VERSION ""

NS_ :

BS_:

BU_: WPC2 PSB SHVU_RR FCS vHS_B2 EMCU SLB GW_APSU GW_DLBCU RCM ARS CGW_CCU vDummy_HS_B GW_RLPSU ATS RLHV SGU PFSU GW_RRPSU ALBCU DSAU SWRC SHVU_FR RCS GW_DPSU BLTN_CAM SCM OHCL RWPC RRHV WPC HOD ASAU

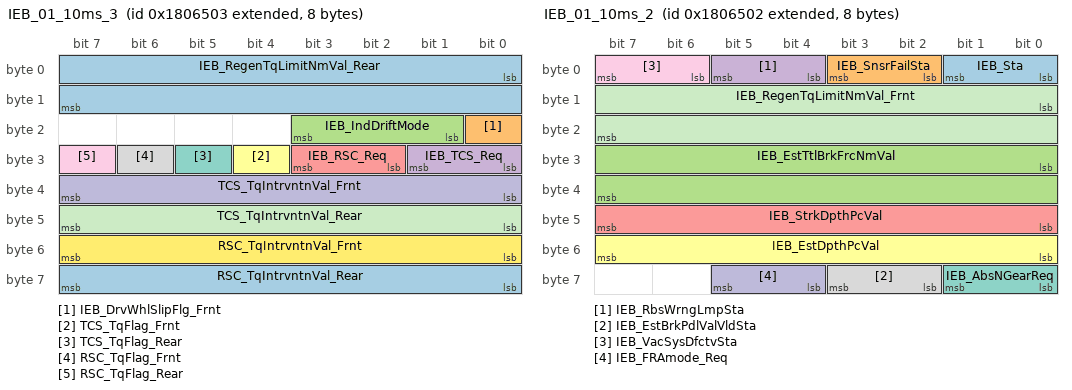
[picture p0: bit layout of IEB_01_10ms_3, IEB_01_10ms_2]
BO_ 2172675331 IEB_01_10ms_3: 8 CGW_CCU
 SG_ IEB_RegenTqLimitNmVal_Rear : 0|16@1+ (1,0) [0|0] "Nm" Vector__XXX
 SG_ IEB_DrvWhlSlipFlg_Frnt : 16|1@1+ (1,0) [0|0] "" Vector__XXX
 SG_ IEB_IndDriftMode : 17|3@1+ (1,0) [0|0] "" Vector__XXX
 SG_ IEB_TCS_Req : 24|2@1+ (1,0) [0|0] "" Vector__XXX
 SG_ IEB_RSC_Req : 26|2@1+ (1,0) [0|0] "" Vector__XXX
 SG_ TCS_TqFlag_Frnt : 28|1@1+ (1,0) [0|0] "" Vector__XXX
 SG_ TCS_TqFlag_Rear : 29|1@1+ (1,0) [0|0] "" Vector__XXX
 SG_ RSC_TqFlag_Frnt : 30|1@1+ (1,0) [0|0] "" Vector__XXX
 SG_ RSC_TqFlag_Rear : 31|1@1+ (1,0) [0|0] "" Vector__XXX
 SG_ TCS_TqIntrvntnVal_Frnt : 32|8@1+ (0.390625,0) [0|0] "%" Vector__XXX
 SG_ TCS_TqIntrvntnVal_Rear : 40|8@1+ (0.390625,0) [0|0] "%" Vector__XXX
 SG_ RSC_TqIntrvntnVal_Frnt : 48|8@1+ (0.390625,0) [0|0] "%" Vector__XXX
 SG_ RSC_TqIntrvntnVal_Rear : 56|8@1+ (0.390625,0) [0|0] "%" Vector__XXX

BO_ 2172675330 IEB_01_10ms_2: 8 CGW_CCU
 SG_ IEB_Sta : 0|2@1+ (1,0) [0|0] "" Vector__XXX
 SG_ IEB_SnsrFailSta : 2|2@1+ (1,0) [0|0] "" Vector__XXX
 SG_ IEB_EstTtlBrkFrcNmVal : 24|16@1+ (1,0) [0|0] "Nm" Vector__XXX
 SG_ IEB_RbsWrngLmpSta : 4|2@1+ (1,0) [0|0] "" Vector__XXX
 SG_ IEB_StrkDpthPcVal : 40|8@1+ (0.39215,0) [0|0] "%" Vector__XXX
 SG_ IEB_EstDpthPcVal : 48|8@1+ (0.390625,0) [0|0] "%" Vector__XXX
 SG_ IEB_AbsNGearReq : 56|2@1+ (1,0) [0|0] "" Vector__XXX
 SG_ IEB_EstBrkPdlValVldSta : 58|2@1+ (1,0) [0|0] "" Vector__XXX
 SG_ IEB_VacSysDfctvSta : 6|2@1+ (1,0) [0|0] "" Vector__XXX
 SG_ IEB_FRAmode_Req : 60|2@1+ (1,0) [0|0] "" Vector__XXX
 SG_ IEB_RegenTqLimitNmVal_Frnt : 8|16@1+ (1,0) [0|0] "Nm" Vector__XXX

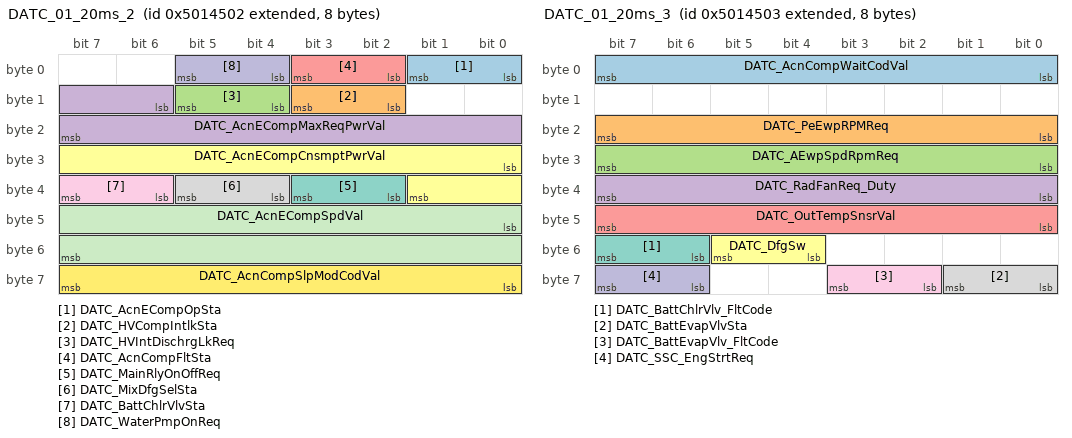
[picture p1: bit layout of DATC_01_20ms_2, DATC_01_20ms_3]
BO_ 2231452930 DATC_01_20ms_2: 8 CGW_CCU
 SG_ DATC_AcnECompOpSta : 0|2@1+ (1,0) [0|0] "flag" Vector__XXX
 SG_ DATC_HVCompIntlkSta : 10|2@1+ (1,0) [0|0] "flag" Vector__XXX
 SG_ DATC_HVIntDischrgLkReq : 12|2@1+ (1,0) [0|0] "flag" Vector__XXX
 SG_ DATC_AcnECompMaxReqPwrVal : 14|10@1+ (20,0) [0|0] "W" Vector__XXX
 SG_ DATC_AcnCompFltSta : 2|2@1+ (1,0) [0|0] "flag" Vector__XXX
 SG_ DATC_AcnECompCnsmptPwrVal : 24|10@1+ (20,0) [0|0] "W" Vector__XXX
 SG_ DATC_MainRlyOnOffReq : 34|2@1+ (1,0) [0|0] "flag" Vector__XXX
 SG_ DATC_MixDfgSelSta : 36|2@1+ (1,0) [0|0] "flag" Vector__XXX
 SG_ DATC_BattChlrVlvSta : 38|2@1+ (1,0) [0|0] "" Vector__XXX
 SG_ DATC_WaterPmpOnReq : 4|2@1+ (1,0) [0|0] "flag" Vector__XXX
 SG_ DATC_AcnECompSpdVal : 40|16@1+ (1,0) [0|0] "rpm" Vector__XXX
 SG_ DATC_AcnCompSlpModCodVal : 56|8@1+ (1,0) [0|0] "" Vector__XXX

BO_ 2231452931 DATC_01_20ms_3: 8 CGW_CCU
 SG_ DATC_AcnCompWaitCodVal : 0|8@1+ (1,0) [0|0] "" Vector__XXX
 SG_ DATC_PeEwpRPMReq : 16|8@1+ (30,0) [0|0] "" Vector__XXX
 SG_ DATC_AEwpSpdRpmReq : 24|8@1+ (20,0) [0|0] "rpm" Vector__XXX
 SG_ DATC_RadFanReq_Duty : 32|8@1+ (1,0) [0|0] "%" Vector__XXX
 SG_ DATC_OutTempSnsrVal : 40|8@1+ (0.5,-40) [0|0] "¡É"  RCM
 SG_ DATC_DfgSw : 52|2@1+ (1,0) [0|0] "" Vector__XXX
 SG_ DATC_BattChlrVlv_FltCode : 54|2@1+ (1,0) [0|0] "" Vector__XXX
 SG_ DATC_BattEvapVlvSta : 56|2@1+ (1,0) [0|0] "" Vector__XXX
 SG_ DATC_BattEvapVlv_FltCode : 58|2@1+ (1,0) [0|0] "" Vector__XXX
 SG_ DATC_SSC_EngStrtReq : 62|2@1+ (1,0) [0|0] "" Vector__XXX

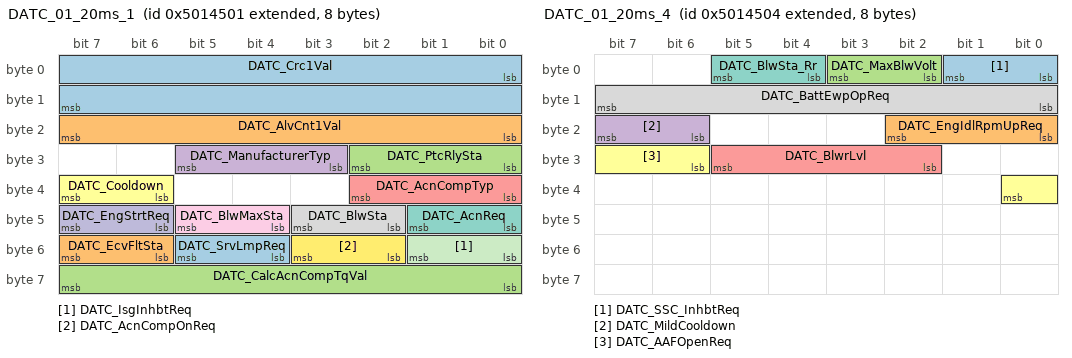
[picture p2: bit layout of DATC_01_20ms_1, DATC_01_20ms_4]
BO_ 2231452929 DATC_01_20ms_1: 8 CGW_CCU
 SG_ DATC_Crc1Val : 0|16@1+ (1,0) [0|0] "" Vector__XXX
 SG_ DATC_AlvCnt1Val : 16|8@1+ (1,0) [0|0] "" Vector__XXX
 SG_ DATC_PtcRlySta : 24|3@1+ (1,0) [0|0] "" Vector__XXX
 SG_ DATC_ManufacturerTyp : 27|3@1+ (1,0) [0|0] "" Vector__XXX
 SG_ DATC_AcnCompTyp : 32|3@1+ (1,0) [0|0] "flag" Vector__XXX
 SG_ DATC_Cooldown : 38|2@1+ (1,0) [0|0] "" Vector__XXX
 SG_ DATC_AcnReq : 40|2@1+ (1,0) [0|0] "" Vector__XXX
 SG_ DATC_BlwSta : 42|2@1+ (1,0) [0|0] "" Vector__XXX
 SG_ DATC_BlwMaxSta : 44|2@1+ (1,0) [0|0] "" Vector__XXX
 SG_ DATC_EngStrtReq : 46|2@1+ (1,0) [0|0] "" Vector__XXX
 SG_ DATC_IsgInhbtReq : 48|2@1+ (1,0) [0|0] "" Vector__XXX
 SG_ DATC_AcnCompOnReq : 50|2@1+ (1,0) [0|0] "flag" Vector__XXX
 SG_ DATC_SrvLmpReq : 52|2@1+ (1,0) [0|0] "" Vector__XXX
 SG_ DATC_EcvFltSta : 54|2@1+ (1,0) [0|0] "" Vector__XXX
 SG_ DATC_CalcAcnCompTqVal : 56|8@1+ (0.2,0) [0|0] "Nm" Vector__XXX

BO_ 2231452932 DATC_01_20ms_4: 8 CGW_CCU
 SG_ DATC_SSC_InhbtReq : 0|2@1+ (1,0) [0|0] "" Vector__XXX
 SG_ DATC_EngIdlRpmUpReq : 16|3@1+ (1,0) [0|0] "" Vector__XXX
 SG_ DATC_MaxBlwVolt : 2|2@1+ (1,0) [0|0] "" Vector__XXX
 SG_ DATC_MildCooldown : 22|2@1+ (1,0) [0|0] "" Vector__XXX
 SG_ DATC_BlwrLvl : 26|4@1+ (1,0) [0|0] "" Vector__XXX
 SG_ DATC_AAFOpenReq : 30|3@1+ (1,0) [0|0] "" Vector__XXX
 SG_ DATC_BlwSta_Rr : 4|2@1+ (1,0) [0|0] "" Vector__XXX
 SG_ DATC_BattEwpOpReq : 8|8@1+ (30,0) [0|0] "rpm" Vector__XXX

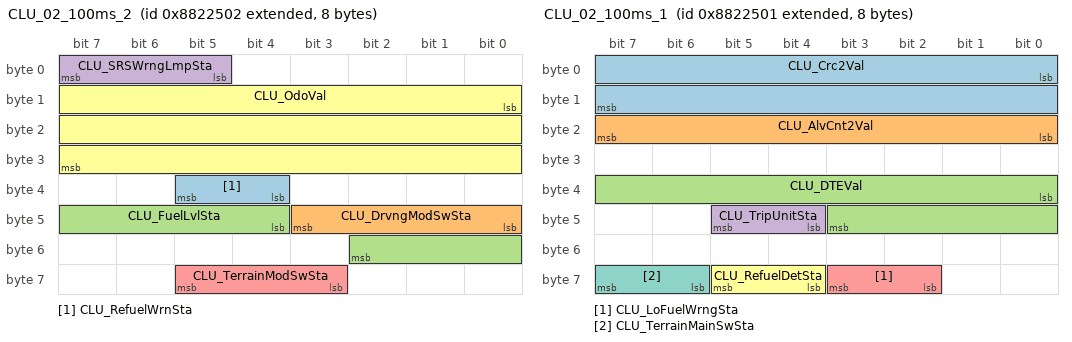
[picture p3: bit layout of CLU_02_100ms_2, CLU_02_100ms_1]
BO_ 2290230530 CLU_02_100ms_2: 8 CGW_CCU
 SG_ CLU_RefuelWrnSta : 36|2@1+ (1,0) [0|0] "" Vector__XXX
 SG_ CLU_DrvngModSwSta : 40|4@1+ (1,0) [0|0] ""  ALBCU,GW_DLBCU,SWRC
 SG_ CLU_FuelLvlSta : 44|7@1+ (1,0) [0|0] "%" Vector__XXX
 SG_ CLU_SRSWrngLmpSta : 5|3@1+ (1,0) [0|0] "" Vector__XXX
 SG_ CLU_TerrainModSwSta : 59|3@1+ (1,0) [0|0] ""  ALBCU,ASAU,DSAU,GW_DLBCU,SWRC
 SG_ CLU_OdoVal : 8|24@1+ (0.1,0) [0|0] "km" Vector__XXX

BO_ 2290230529 CLU_02_100ms_1: 8 CGW_CCU
 SG_ CLU_Crc2Val : 0|16@1+ (1,0) [0|0] "" Vector__XXX
 SG_ CLU_AlvCnt2Val : 16|8@1+ (1,0) [0|0] "" Vector__XXX
 SG_ CLU_DTEVal : 32|12@1+ (1,0) [0|0] "" Vector__XXX
 SG_ CLU_TripUnitSta : 44|2@1+ (1,0) [0|0] "" Vector__XXX
 SG_ CLU_LoFuelWrngSta : 58|2@1+ (1,0) [0|0] "" Vector__XXX
 SG_ CLU_RefuelDetSta : 60|2@1+ (1,0) [0|0] "" Vector__XXX
 SG_ CLU_TerrainMainSwSta : 62|2@1+ (1,0) [0|0] ""  FCS,SWRC

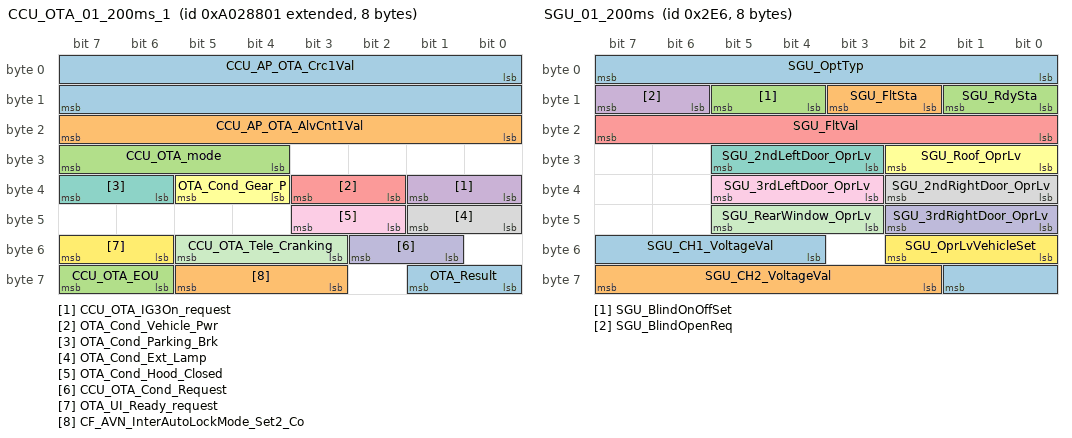
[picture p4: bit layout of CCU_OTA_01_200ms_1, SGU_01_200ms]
BO_ 2315421697 CCU_OTA_01_200ms_1: 8 CGW_CCU
 SG_ CCU_AP_OTA_Crc1Val : 0|16@1+ (1,0) [0|0] ""  vDummy_HS_B
 SG_ CCU_AP_OTA_AlvCnt1Val : 16|8@1+ (1,0) [0|0] ""  vDummy_HS_B
 SG_ CCU_OTA_mode : 28|4@1+ (1,0) [0|0] "" Vector__XXX
 SG_ CCU_OTA_IG3On_request : 32|2@1+ (1,0) [0|0] "" Vector__XXX
 SG_ OTA_Cond_Vehicle_Pwr : 34|2@1+ (1,0) [0|0] "flag" Vector__XXX
 SG_ OTA_Cond_Gear_P : 36|2@1+ (1,0) [0|0] "flag" Vector__XXX
 SG_ OTA_Cond_Parking_Brk : 38|2@1+ (1,0) [0|0] "flag" Vector__XXX
 SG_ OTA_Cond_Ext_Lamp : 40|2@1+ (1,0) [0|0] "flag" Vector__XXX
 SG_ OTA_Cond_Hood_Closed : 42|2@1+ (1,0) [0|0] "flag" Vector__XXX
 SG_ CCU_OTA_Cond_Request : 49|2@1+ (1,0) [0|0] "" Vector__XXX
 SG_ CCU_OTA_Tele_Cranking : 51|3@1+ (1,0) [0|0] "" Vector__XXX
 SG_ OTA_UI_Ready_request : 54|2@1+ (1,0) [0|0] "" Vector__XXX
 SG_ OTA_Result : 56|2@1+ (1,0) [0|0] "flag" Vector__XXX
 SG_ CF_AVN_InterAutoLockMode_Set2_Co : 59|3@1+ (1,0) [0|0] "" Vector__XXX
 SG_ CCU_OTA_EOU : 62|2@1+ (1,0) [0|0] "" Vector__XXX

BO_ 2470763009 CLU_09_00ms_1: 8 CGW_CCU
 SG_ CLU_Crc9Val : 0|16@1+ (1,0) [0|0] "" Vector__XXX
 SG_ CLU_AlvCnt9Val : 16|8@1+ (1,0) [0|0] "" Vector__XXX
 SG_ USM_MdLmpClrSetReq : 24|4@1+ (1,0) [0|0] "" Vector__XXX
 SG_ USM_RrWiperRevSetReq : 28|2@1+ (1,0) [0|0] "" Vector__XXX
 SG_ USM_RrStRemindSetReq : 30|2@1+ (1,0) [0|0] "" Vector__XXX
 SG_ USM_RrWpcSetReq : 32|2@1+ (1,0) [0|0] "" Vector__XXX
 SG_ USM_WpcSetReq : 34|2@1+ (1,0) [0|0] ""  WPC,WPC2
 SG_ USM_SeqLmpSetReq : 36|2@1+ (1,0) [0|0] "" Vector__XXX
 SG_ USM_UnlckWlcmSetReq : 38|2@1+ (1,0) [0|0] "" Vector__XXX
 SG_ USM_SmrtWlcmSetReq : 40|2@1+ (1,0) [0|0] "" Vector__XXX
 SG_ USM_UipSetReq : 42|2@1+ (1,0) [0|0] "" Vector__XXX
 SG_ USM_DigitalKeyEnblSetReq : 44|2@1+ (1,0) [0|0] "" Vector__XXX
 SG_ USM_OwnerPhnRegSetReq : 46|2@1+ (1,0) [0|0] "" Vector__XXX
 SG_ USM_NFCCard1RegSetReq : 48|2@1+ (1,0) [0|0] "" Vector__XXX
 SG_ USM_NFCCard2RegSetReq : 50|2@1+ (1,0) [0|0] "" Vector__XXX
 SG_ USM_ProcStpReq : 52|1@1+ (1,0) [0|0] "" Vector__XXX
 SG_ USM_PwrAutoOffTimeSetReq : 54|3@1+ (1,0) [0|0] "" Vector__XXX
 SG_ USM_RrStRemindSetReq_RestMode : 57|3@1+ (1,0) [0|0] "" Vector__XXX
 SG_ USM_1stRrStRemindSetReq : 60|2@1+ (1,0) [0|0] "" Vector__XXX
 SG_ USM_Wpc2SetReq : 62|2@1+ (1,0) [0|0] ""  WPC2

BO_ 742 SGU_01_200ms: 8 SGU
 SG_ SGU_OptTyp : 0|8@1+ (1,0) [0|0] "" Vector__XXX
 SG_ SGU_FltSta : 10|2@1+ (1,0) [0|0] "" Vector__XXX
 SG_ SGU_BlindOnOffSet : 12|2@1+ (1,0) [0|0] ""  CGW_CCU
 SG_ SGU_BlindOpenReq : 14|2@1+ (1,0) [0|0] ""  RCM
 SG_ SGU_FltVal : 16|8@1+ (1,0) [0|0] "" Vector__XXX
 SG_ SGU_Roof_OprLv : 24|3@1+ (1,0) [0|0] ""  CGW_CCU
 SG_ SGU_2ndLeftDoor_OprLv : 27|3@1+ (1,0) [0|0] ""  CGW_CCU
 SG_ SGU_2ndRightDoor_OprLv : 32|3@1+ (1,0) [0|0] ""  CGW_CCU
 SG_ SGU_3rdLeftDoor_OprLv : 35|3@1+ (1,0) [0|0] ""  CGW_CCU
 SG_ SGU_3rdRightDoor_OprLv : 40|3@1+ (1,0) [0|0] ""  CGW_CCU
 SG_ SGU_RearWindow_OprLv : 43|3@1+ (1,0) [0|0] ""  CGW_CCU
 SG_ SGU_OprLvVehicleSet : 48|3@1+ (1,0) [0|0] ""  CGW_CCU
 SG_ SGU_CH1_VoltageVal : 52|6@1+ (0.1,0) [0|0] "V" Vector__XXX
 SG_ SGU_CH2_VoltageVal : 58|6@1+ (0.1,0) [0|0] "V" Vector__XXX
 SG_ SGU_RdySta : 8|2@1+ (1,0) [0|0] "" Vector__XXX

BO_ 763 SBCM_DRV_03_200ms: 8 CGW_CCU
 SG_ SBCM_DRV_Crc3Val : 0|8@1+ (1,0) [0|0] "" Vector__XXX
 SG_ CDM_TypeOption : 10|2@1+ (1,0) [0|0] "" Vector__XXX
 SG_ SBCM_DRV_AlvCnt3Val : 12|4@1+ (1,0) [0|0] "" Vector__XXX
 SG_ CDM_ImmeChgSw_SBCM : 16|2@1+ (1,0) [0|0] "" Vector__XXX
 SG_ CDM_FobSrchReq_DRV : 18|2@1+ (1,0) [0|0] "" Vector__XXX
 SG_ CDM_OpnClsState_SBCM : 20|2@1+ (1,0) [0|0] "" Vector__XXX
 SG_ CDM_WarnMsg_SBCM : 22|2@1+ (1,0) [0|0] "" Vector__XXX
 SG_ CDM_AutoWashModeSta : 24|3@1+ (1,0) [0|0] "" Vector__XXX
 SG_ CDM_CmdStatus_SBCM : 28|4@1+ (1,0) [0|0] "" Vector__XXX
 SG_ CDM_OutsideOpnSwSta : 32|2@1+ (1,0) [0|0] "" Vector__XXX
 SG_ PwrDRBuzzerOut_DRV : 34|2@1+ (1,0) [0|0] "" Vector__XXX
 SG_ Warn_HoodSwSta_SBCM : 36|2@1+ (1,0) [0|0] ""  BLTN_CAM
 SG_ Hood_TypeOption : 38|2@1+ (1,0) [0|0] ""  BLTN_CAM
 SG_ SBCM_FrunkSta : 40|2@1+ (1,0) [0|0] "" Vector__XXX
 SG_ Warn_HoodSwFullSta_SBCM : 42|2@1+ (1,0) [0|0] "" Vector__XXX
 SG_ FrunkWarning_SBCM : 44|2@1+ (1,0) [0|0] "" Vector__XXX
 SG_ SBCM_Longkey_DRVDrAtClsSwSta : 46|2@1+ (1,0) [0|0] "" Vector__XXX
 SG_ PwrDRClosingDRVDrSta : 48|3@1+ (1,0) [0|0] "" Vector__XXX
 SG_ Drv_DrLkRetryFail_SBCM : 51|2@1+ (1,0) [0|0] "" Vector__XXX
 SG_ CDM_GbtImmeChgSw_SBCM : 54|2@1+ (1,0) [0|0] "" Vector__XXX
 SG_ CDM_GbtOpnClsState_SBCM : 56|2@1+ (1,0) [0|0] "" Vector__XXX
 SG_ CDM_GbtWarnMsg_SBCM : 58|2@1+ (1,0) [0|0] "" Vector__XXX
 SG_ CDM_GbtOutsideOpnSwSta : 60|2@1+ (1,0) [0|0] "" Vector__XXX
 SG_ DoorLock_DrvLkOutSta_SBCM : 62|2@1+ (1,0) [0|0] "" Vector__XXX
 SG_ CDM_InsideOpnSwSta : 8|2@1+ (1,0) [0|0] "" Vector__XXX

BO_ 761 SBCM_AST_03_200ms: 8 CGW_CCU
 SG_ SBCM_AST_Crc3Val : 0|8@1+ (1,0) [0|0] "" Vector__XXX
 SG_ CDM_TypeOption_AST : 10|2@1+ (1,0) [0|0] "" Vector__XXX
 SG_ SBCM_AST_AlvCnt3Val : 12|4@1+ (1,0) [0|0] "" Vector__XXX
 SG_ CDM_ImmeChgSw_AST : 16|2@1+ (1,0) [0|0] "" Vector__XXX
 SG_ CDM_FobSrchReq_AST : 18|2@1+ (1,0) [0|0] "" Vector__XXX
 SG_ CDM_OpnClsState_AST : 20|2@1+ (1,0) [0|0] "" Vector__XXX
 SG_ CDM_WarnMsg_AST : 22|2@1+ (1,0) [0|0] "" Vector__XXX
 SG_ Mirror_RH_FoldingSta : 24|2@1+ (1,0) [0|0] "" Vector__XXX
 SG_ Mirror_RH_UnfoldingSta : 26|2@1+ (1,0) [0|0] "" Vector__XXX
 SG_ CDM_CmdStatus_AST : 28|4@1+ (1,0) [0|0] "" Vector__XXX
 SG_ AST_CrashMRActAlarm : 32|2@1+ (1,0) [0|0] "" Vector__XXX
 SG_ PwrDRBuzzerOut_AST : 34|2@1+ (1,0) [0|0] "" Vector__XXX
 SG_ IMS_OSMirPlayBackSta_RH : 36|4@1+ (1,0) [0|0] ""  GW_DPSU
 SG_ PwrDRClosingASTDrSta : 40|3@1+ (1,0) [0|0] "" Vector__XXX
 SG_ CDM_OutsideOpnSwSta_AST : 44|2@1+ (1,0) [0|0] "" Vector__XXX
 SG_ SBCM_Longkey_ASTDrAtClsSwSta : 46|2@1+ (1,0) [0|0] "" Vector__XXX
 SG_ Hood_TypeOption_AST : 48|2@1+ (1,0) [0|0] "" Vector__XXX
 SG_ Warn_HoodSwSta_AST : 50|2@1+ (1,0) [0|0] "" Vector__XXX
 SG_ FrunkWarning_AST : 52|2@1+ (1,0) [0|0] "" Vector__XXX
 SG_ SBCM_FrunkSta_AST : 54|2@1+ (1,0) [0|0] "" Vector__XXX
 SG_ Ast_DrLkRetryFail_SBCM : 60|2@1+ (1,0) [0|0] "" Vector__XXX
 SG_ DoorLock_AstLkOutSta_SBCM : 62|2@1+ (1,0) [0|0] "" Vector__XXX
 SG_ SBCM_AST_DiagSta : 8|2@1+ (1,0) [0|0] "" Vector__XXX

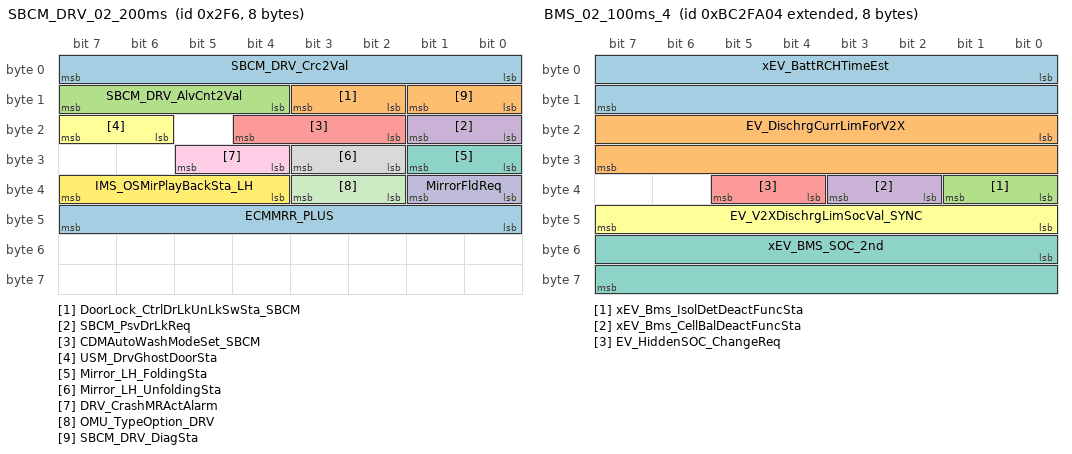
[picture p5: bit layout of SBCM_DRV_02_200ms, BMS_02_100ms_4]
BO_ 758 SBCM_DRV_02_200ms: 8 CGW_CCU
 SG_ SBCM_DRV_Crc2Val : 0|8@1+ (1,0) [0|0] "" Vector__XXX
 SG_ DoorLock_CtrlDrLkUnLkSwSta_SBCM : 10|2@1+ (1,0) [0|0] "" Vector__XXX
 SG_ SBCM_DRV_AlvCnt2Val : 12|4@1+ (1,0) [0|0] "" Vector__XXX
 SG_ SBCM_PsvDrLkReq : 16|2@1+ (1,0) [0|0] "" Vector__XXX
 SG_ CDMAutoWashModeSet_SBCM : 18|3@1+ (1,0) [0|0] "" Vector__XXX
 SG_ USM_DrvGhostDoorSta : 22|2@1+ (1,0) [0|0] "" Vector__XXX
 SG_ Mirror_LH_FoldingSta : 24|2@1+ (1,0) [0|0] "" Vector__XXX
 SG_ Mirror_LH_UnfoldingSta : 26|2@1+ (1,0) [0|0] "" Vector__XXX
 SG_ DRV_CrashMRActAlarm : 28|2@1+ (1,0) [0|0] "" Vector__XXX
 SG_ MirrorFldReq : 32|2@1+ (1,0) [0|0] "" Vector__XXX
 SG_ OMU_TypeOption_DRV : 34|2@1+ (1,0) [0|0] "" Vector__XXX
 SG_ IMS_OSMirPlayBackSta_LH : 36|4@1+ (1,0) [0|0] ""  GW_DPSU
 SG_ ECMMRR_PLUS : 40|8@1+ (1,0) [0|0] "" Vector__XXX
 SG_ SBCM_DRV_DiagSta : 8|2@1+ (1,0) [0|0] "" Vector__XXX

BO_ 2344811012 BMS_02_100ms_4: 8 CGW_CCU
 SG_ xEV_BattRCHTimeEst : 0|16@1+ (1,0) [0|0] "Min" Vector__XXX
 SG_ EV_DischrgCurrLimForV2X : 16|16@1+ (0.1,0) [0|0] "A" Vector__XXX
 SG_ xEV_Bms_IsolDetDeactFuncSta : 32|2@1+ (1,0) [0|0] "flg" Vector__XXX
 SG_ xEV_Bms_CellBalDeactFuncSta : 34|2@1+ (1,0) [0|0] "flag" Vector__XXX
 SG_ EV_HiddenSOC_ChangeReq : 36|2@1+ (1,0) [0|0] "" Vector__XXX
 SG_ EV_V2XDischrgLimSocVal_SYNC : 40|8@1+ (0.5,0) [0|0] "%" Vector__XXX
 SG_ xEV_BMS_SOC_2nd : 48|16@1+ (0.05,0) [0|0] "%" Vector__XXX

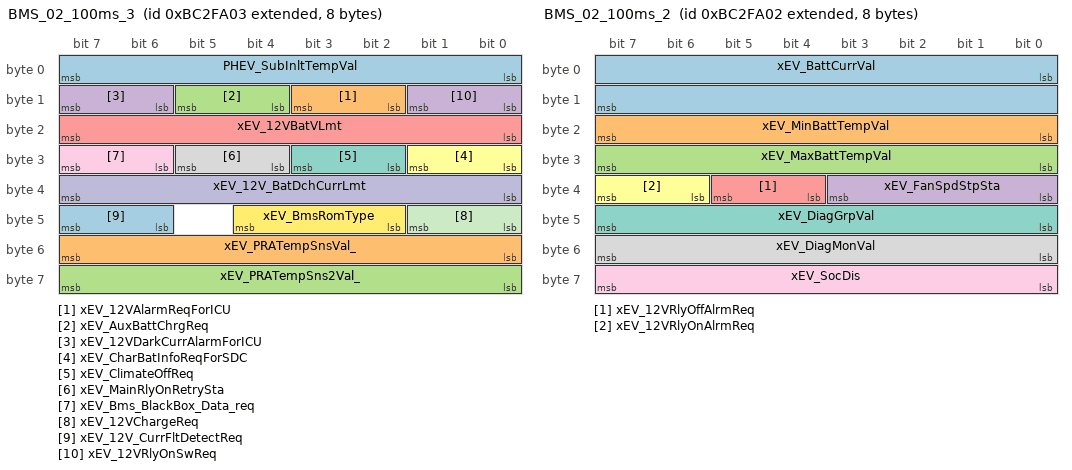
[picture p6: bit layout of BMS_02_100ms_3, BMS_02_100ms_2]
BO_ 2344811011 BMS_02_100ms_3: 8 CGW_CCU
 SG_ PHEV_SubInltTempVal : 0|8@1- (1,0) [0|0] "¡É" Vector__XXX
 SG_ xEV_12VAlarmReqForICU : 10|2@1+ (1,0) [0|0] "" Vector__XXX
 SG_ xEV_AuxBattChrgReq : 12|2@1+ (1,0) [0|0] "" Vector__XXX
 SG_ xEV_12VDarkCurrAlarmForICU : 14|2@1+ (1,0) [0|0] "" Vector__XXX
 SG_ xEV_12VBatVLmt : 16|8@1+ (0.1,0) [0|0] "V" Vector__XXX
 SG_ xEV_CharBatInfoReqForSDC : 24|2@1+ (1,0) [0|0] "" Vector__XXX
 SG_ xEV_ClimateOffReq : 26|2@1+ (1,0) [0|0] "" Vector__XXX
 SG_ xEV_MainRlyOnRetrySta : 28|2@1+ (1,0) [0|0] "" Vector__XXX
 SG_ xEV_Bms_BlackBox_Data_req : 30|2@1+ (1,0) [0|0] "" Vector__XXX
 SG_ xEV_12V_BatDchCurrLmt : 32|8@1+ (1,0) [0|0] "A" Vector__XXX
 SG_ xEV_12VChargeReq : 40|2@1+ (1,0) [0|0] "" Vector__XXX
 SG_ xEV_BmsRomType : 42|3@1+ (1,0) [0|0] "" Vector__XXX
 SG_ xEV_12V_CurrFltDetectReq : 46|2@1+ (1,0) [0|0] "" Vector__XXX
 SG_ xEV_PRATempSnsVal_ : 48|8@1- (2,0) [0|0] "¡É" Vector__XXX
 SG_ xEV_PRATempSns2Val_ : 56|8@1- (2,0) [0|0] "¡É" Vector__XXX
 SG_ xEV_12VRlyOnSwReq : 8|2@1+ (1,0) [0|0] "" Vector__XXX

BO_ 2344811010 BMS_02_100ms_2: 8 CGW_CCU
 SG_ xEV_BattCurrVal : 0|16@1- (0.1,0) [0|0] "A" Vector__XXX
 SG_ xEV_MinBattTempVal : 16|8@1- (1,0) [0|0] "¡É" Vector__XXX
 SG_ xEV_MaxBattTempVal : 24|8@1- (1,0) [0|0] "¡É" Vector__XXX
 SG_ xEV_FanSpdStpSta : 32|4@1+ (1,0) [0|0] "Step" Vector__XXX
 SG_ xEV_12VRlyOffAlrmReq : 36|2@1+ (1,0) [0|0] "" Vector__XXX
 SG_ xEV_12VRlyOnAlrmReq : 38|2@1+ (1,0) [0|0] "" Vector__XXX
 SG_ xEV_DiagGrpVal : 40|8@1+ (1,0) [0|0] "" Vector__XXX
 SG_ xEV_DiagMonVal : 48|8@1+ (1,0) [0|0] "" Vector__XXX
 SG_ xEV_SocDis : 56|8@1+ (0.5,0) [0|0] "%"  SWRC

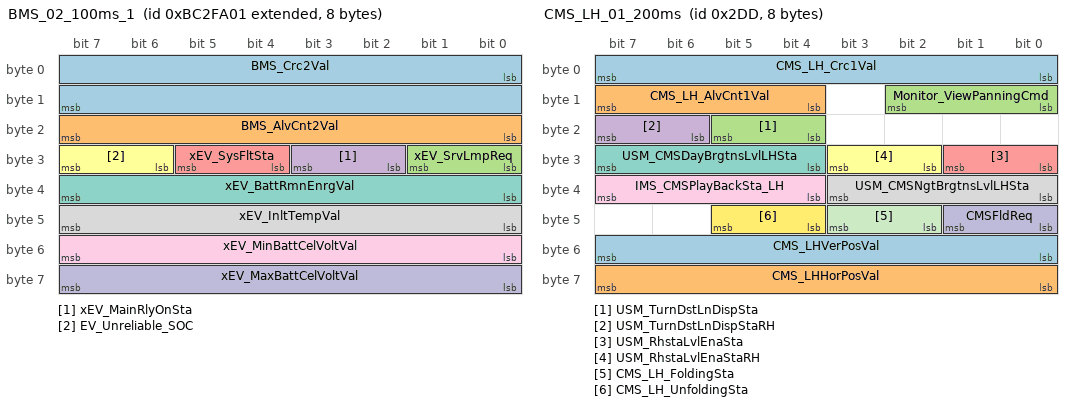
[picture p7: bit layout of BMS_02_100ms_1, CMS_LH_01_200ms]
BO_ 2344811009 BMS_02_100ms_1: 8 CGW_CCU
 SG_ BMS_Crc2Val : 0|16@1+ (1,0) [0|0] "" Vector__XXX
 SG_ BMS_AlvCnt2Val : 16|8@1+ (1,0) [0|0] "" Vector__XXX
 SG_ xEV_SrvLmpReq : 24|2@1+ (1,0) [0|0] "" Vector__XXX
 SG_ xEV_MainRlyOnSta : 26|2@1+ (1,0) [0|0] ""  ALBCU,GW_APSU,GW_DLBCU,GW_DPSU,GW_RLPSU,GW_RRPSU,RLHV,RRHV,SHVU_FR,SHVU_RR
 SG_ xEV_SysFltSta : 28|2@1+ (1,0) [0|0] "" Vector__XXX
 SG_ EV_Unreliable_SOC : 30|2@1+ (1,0) [0|0] "" Vector__XXX
 SG_ xEV_BattRmnEnrgVal : 32|8@1+ (1,0) [0|0] "" Vector__XXX
 SG_ xEV_InltTempVal : 40|8@1- (1,0) [0|0] "¡É" Vector__XXX
 SG_ xEV_MinBattCelVoltVal : 48|8@1+ (0.02,0) [0|0] "V" Vector__XXX
 SG_ xEV_MaxBattCelVoltVal : 56|8@1+ (0.02,0) [0|0] "V" Vector__XXX

BO_ 733 CMS_LH_01_200ms: 8 CGW_CCU
 SG_ CMS_LH_Crc1Val : 0|8@1+ (1,0) [0|0] "" Vector__XXX
 SG_ CMS_LH_AlvCnt1Val : 12|4@1+ (1,0) [0|0] "" Vector__XXX
 SG_ USM_TurnDstLnDispSta : 20|2@1+ (1,0) [0|0] "" Vector__XXX
 SG_ USM_TurnDstLnDispStaRH : 22|2@1+ (1,0) [0|0] "" Vector__XXX
 SG_ USM_RhstaLvlEnaSta : 24|2@1+ (1,0) [0|0] "" Vector__XXX
 SG_ USM_RhstaLvlEnaStaRH : 26|2@1+ (1,0) [0|0] "" Vector__XXX
 SG_ USM_CMSDayBrgtnsLvlLHSta : 28|4@1+ (1,0) [0|0] "" Vector__XXX
 SG_ USM_CMSNgtBrgtnsLvlLHSta : 32|4@1+ (1,0) [0|0] "" Vector__XXX
 SG_ IMS_CMSPlayBackSta_LH : 36|4@1+ (1,0) [0|0] ""  GW_DPSU
 SG_ CMSFldReq : 40|2@1+ (1,0) [0|0] "" Vector__XXX
 SG_ CMS_LH_FoldingSta : 42|2@1+ (1,0) [0|0] "" Vector__XXX
 SG_ CMS_LH_UnfoldingSta : 44|2@1+ (1,0) [0|0] "" Vector__XXX
 SG_ CMS_LHVerPosVal : 48|8@1+ (0.02,0) [0|0] "V" Vector__XXX
 SG_ CMS_LHHorPosVal : 56|8@1+ (0.02,0) [0|0] "V" Vector__XXX
 SG_ Monitor_ViewPanningCmd : 8|3@1+ (1,0) [0|0] "" Vector__XXX

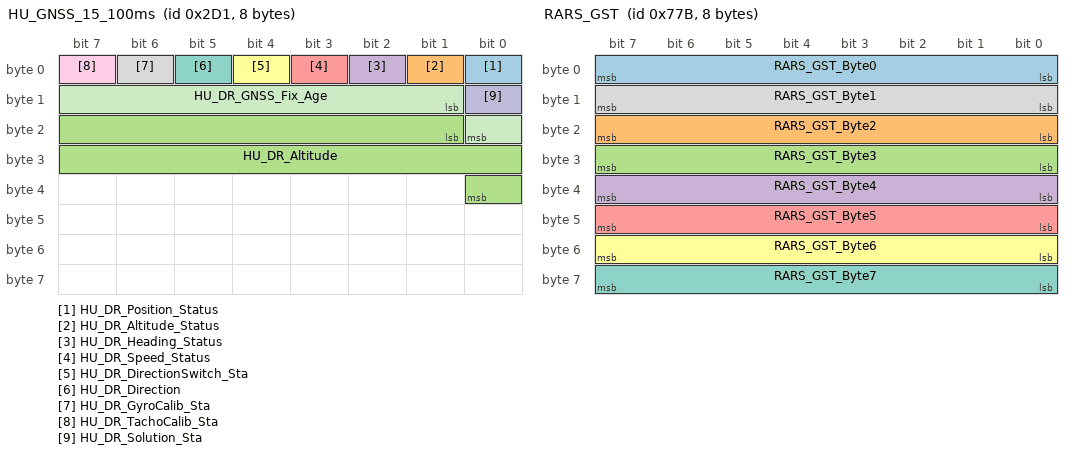
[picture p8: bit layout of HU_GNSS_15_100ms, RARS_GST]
BO_ 721 HU_GNSS_15_100ms: 8 CGW_CCU
 SG_ HU_DR_Position_Status : 0|1@1+ (1,0) [0|0] "" Vector__XXX
 SG_ HU_DR_Altitude_Status : 1|1@1+ (1,0) [0|0] "" Vector__XXX
 SG_ HU_DR_Altitude : 17|16@1- (1,0) [0|0] "m"  BLTN_CAM
 SG_ HU_DR_Heading_Status : 2|1@1+ (1,0) [0|0] "" Vector__XXX
 SG_ HU_DR_Speed_Status : 3|1@1+ (1,0) [0|0] "" Vector__XXX
 SG_ HU_DR_DirectionSwitch_Sta : 4|1@1+ (1,0) [0|0] "" Vector__XXX
 SG_ HU_DR_Direction : 5|1@1+ (1,0) [0|0] "" Vector__XXX
 SG_ HU_DR_GyroCalib_Sta : 6|1@1+ (1,0) [0|0] "" Vector__XXX
 SG_ HU_DR_TachoCalib_Sta : 7|1@1+ (1,0) [0|0] "" Vector__XXX
 SG_ HU_DR_Solution_Sta : 8|1@1+ (1,0) [0|0] "" Vector__XXX
 SG_ HU_DR_GNSS_Fix_Age : 9|8@1+ (1,0) [0|0] "Sec" Vector__XXX

BO_ 722 HU_GNSS_16_100ms: 8 CGW_CCU
 SG_ HU_DR_Latitude : 0|32@1- (1,0) [0|0] "¢ª"  BLTN_CAM
 SG_ HU_DR_Longitude : 32|32@1- (1,0) [0|0] "¢ª"  BLTN_CAM

BO_ 723 HU_GNSS_17_100ms: 8 CGW_CCU
 SG_ HU_DR_Heading : 0|16@1+ (1,0) [0|0] "¢ª"  BLTN_CAM
 SG_ HU_DR_Speed : 16|16@1- (0.01,0) [0|0] "m/s" Vector__XXX

BO_ 1915 RARS_GST: 8 ARS
 SG_ RARS_GST_Byte0 : 0|8@1+ (1,0) [0|0] ""  CGW_CCU
 SG_ RARS_GST_Byte2 : 16|8@1+ (1,0) [0|0] ""  CGW_CCU
 SG_ RARS_GST_Byte3 : 24|8@1+ (1,0) [0|0] ""  CGW_CCU
 SG_ RARS_GST_Byte4 : 32|8@1+ (1,0) [0|0] ""  CGW_CCU
 SG_ RARS_GST_Byte5 : 40|8@1+ (1,0) [0|0] ""  CGW_CCU
 SG_ RARS_GST_Byte6 : 48|8@1+ (1,0) [0|0] ""  CGW_CCU
 SG_ RARS_GST_Byte7 : 56|8@1+ (1,0) [0|0] ""  CGW_CCU
 SG_ RARS_GST_Byte1 : 8|8@1+ (1,0) [0|0] ""  CGW_CCU

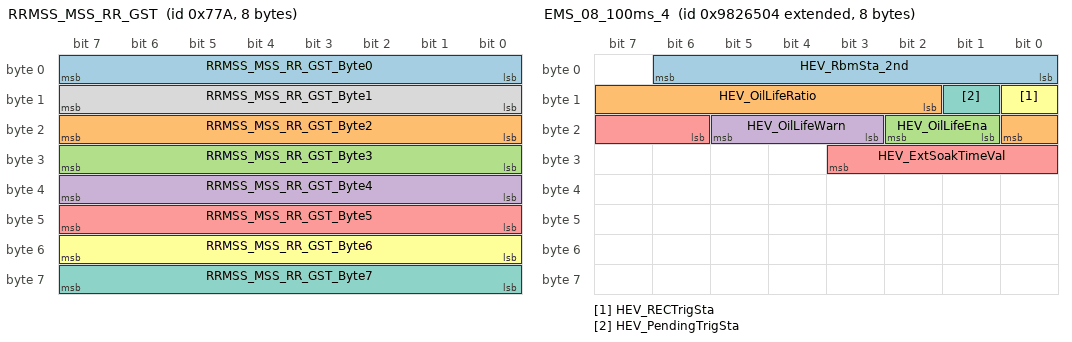
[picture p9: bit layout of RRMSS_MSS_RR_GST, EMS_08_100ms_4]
BO_ 1914 RRMSS_MSS_RR_GST: 8 GW_RRPSU
 SG_ RRMSS_MSS_RR_GST_Byte0 : 0|8@1+ (1,0) [0|0] ""  CGW_CCU
 SG_ RRMSS_MSS_RR_GST_Byte2 : 16|8@1+ (1,0) [0|0] ""  CGW_CCU
 SG_ RRMSS_MSS_RR_GST_Byte3 : 24|8@1+ (1,0) [0|0] ""  CGW_CCU
 SG_ RRMSS_MSS_RR_GST_Byte4 : 32|8@1+ (1,0) [0|0] ""  CGW_CCU
 SG_ RRMSS_MSS_RR_GST_Byte5 : 40|8@1+ (1,0) [0|0] ""  CGW_CCU
 SG_ RRMSS_MSS_RR_GST_Byte6 : 48|8@1+ (1,0) [0|0] ""  CGW_CCU
 SG_ RRMSS_MSS_RR_GST_Byte7 : 56|8@1+ (1,0) [0|0] ""  CGW_CCU
 SG_ RRMSS_MSS_RR_GST_Byte1 : 8|8@1+ (1,0) [0|0] ""  CGW_CCU

BO_ 2307024132 EMS_08_100ms_4: 8 CGW_CCU
 SG_ HEV_RbmSta_2nd : 0|7@1+ (1,0) [0|0] "" Vector__XXX
 SG_ HEV_OilLifeRatio : 10|7@1+ (1,0) [0|0] "%" Vector__XXX
 SG_ HEV_OilLifeEna : 17|2@1+ (1,0) [0|0] "" Vector__XXX
 SG_ HEV_OilLifeWarn : 19|3@1+ (1,0) [0|0] "" Vector__XXX
 SG_ HEV_ExtSoakTimeVal : 22|6@1+ (5,0) [0|0] "" Vector__XXX
 SG_ HEV_RECTrigSta : 8|1@1+ (1,0) [0|0] "" Vector__XXX
 SG_ HEV_PendingTrigSta : 9|1@1+ (1,0) [0|0] "" Vector__XXX

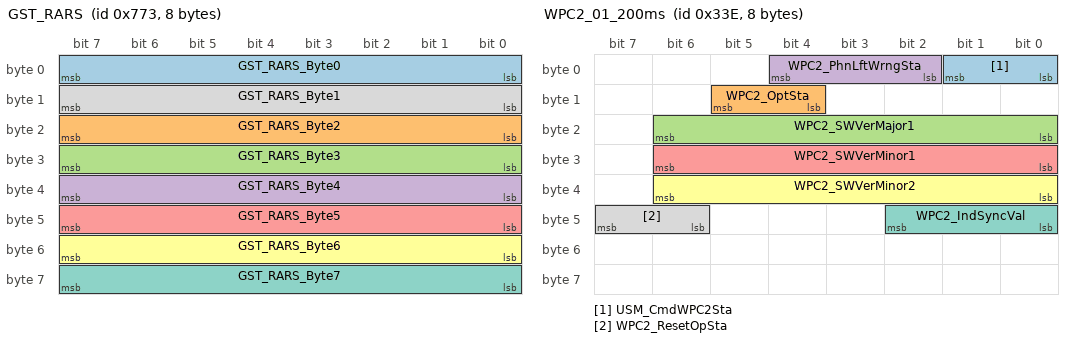
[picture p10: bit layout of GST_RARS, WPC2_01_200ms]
BO_ 1907 GST_RARS: 8 CGW_CCU
 SG_ GST_RARS_Byte0 : 0|8@1+ (1,0) [0|0] ""  ARS
 SG_ GST_RARS_Byte2 : 16|8@1+ (1,0) [0|0] ""  ARS
 SG_ GST_RARS_Byte3 : 24|8@1+ (1,0) [0|0] ""  ARS
 SG_ GST_RARS_Byte4 : 32|8@1+ (1,0) [0|0] ""  ARS
 SG_ GST_RARS_Byte5 : 40|8@1+ (1,0) [0|0] ""  ARS
 SG_ GST_RARS_Byte6 : 48|8@1+ (1,0) [0|0] ""  ARS
 SG_ GST_RARS_Byte7 : 56|8@1+ (1,0) [0|0] ""  ARS
 SG_ GST_RARS_Byte1 : 8|8@1+ (1,0) [0|0] ""  ARS

BO_ 830 WPC2_01_200ms: 8 WPC
 SG_ USM_CmdWPC2Sta : 0|2@1+ (1,0) [0|0] ""  CGW_CCU
 SG_ WPC2_OptSta : 12|2@1+ (1,0) [0|0] ""  CGW_CCU
 SG_ WPC2_SWVerMajor1 : 16|7@1+ (1,0) [0|0] ""  CGW_CCU
 SG_ WPC2_PhnLftWrngSta : 2|3@1+ (1,0) [0|0] ""  CGW_CCU
 SG_ WPC2_SWVerMinor1 : 24|7@1+ (1,0) [0|0] ""  CGW_CCU
 SG_ WPC2_SWVerMinor2 : 32|7@1+ (1,0) [0|0] ""  CGW_CCU
 SG_ WPC2_IndSyncVal : 40|3@1+ (1,0) [0|0] ""  RWPC,WPC
 SG_ WPC2_ResetOpSta : 46|2@1+ (1,0) [0|0] "" Vector__XXX

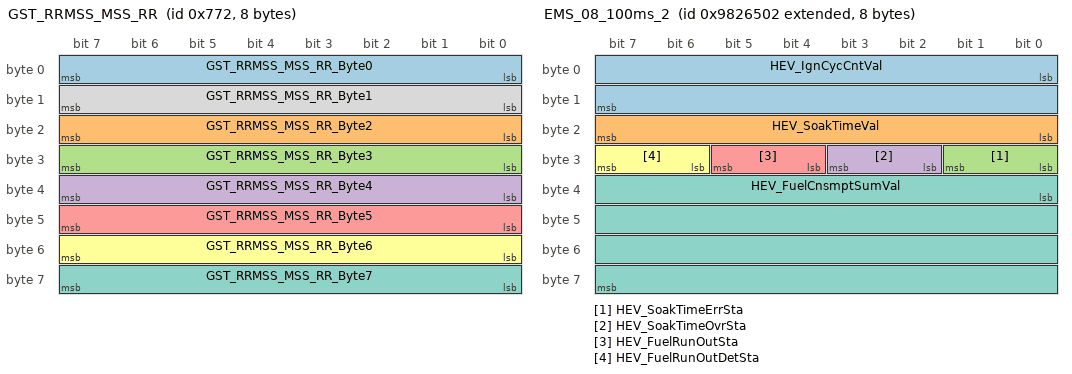
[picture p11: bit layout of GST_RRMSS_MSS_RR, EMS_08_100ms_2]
BO_ 1906 GST_RRMSS_MSS_RR: 8 CGW_CCU
 SG_ GST_RRMSS_MSS_RR_Byte0 : 0|8@1+ (1,0) [0|0] ""  GW_RRPSU
 SG_ GST_RRMSS_MSS_RR_Byte2 : 16|8@1+ (1,0) [0|0] ""  GW_RRPSU
 SG_ GST_RRMSS_MSS_RR_Byte3 : 24|8@1+ (1,0) [0|0] ""  GW_RRPSU
 SG_ GST_RRMSS_MSS_RR_Byte4 : 32|8@1+ (1,0) [0|0] ""  GW_RRPSU
 SG_ GST_RRMSS_MSS_RR_Byte5 : 40|8@1+ (1,0) [0|0] ""  GW_RRPSU
 SG_ GST_RRMSS_MSS_RR_Byte6 : 48|8@1+ (1,0) [0|0] ""  GW_RRPSU
 SG_ GST_RRMSS_MSS_RR_Byte7 : 56|8@1+ (1,0) [0|0] ""  GW_RRPSU
 SG_ GST_RRMSS_MSS_RR_Byte1 : 8|8@1+ (1,0) [0|0] ""  GW_RRPSU

BO_ 2307024130 EMS_08_100ms_2: 8 CGW_CCU
 SG_ HEV_IgnCycCntVal : 0|16@1+ (1,0) [0|0] "" Vector__XXX
 SG_ HEV_SoakTimeVal : 16|8@1+ (1,0) [0|0] "Min" Vector__XXX
 SG_ HEV_SoakTimeErrSta : 24|2@1+ (1,0) [0|0] "" Vector__XXX
 SG_ HEV_SoakTimeOvrSta : 26|2@1+ (1,0) [0|0] "" Vector__XXX
 SG_ HEV_FuelRunOutSta : 28|2@1+ (1,0) [0|0] "" Vector__XXX
 SG_ HEV_FuelRunOutDetSta : 30|2@1+ (1,0) [0|0] "" Vector__XXX
 SG_ HEV_FuelCnsmptSumVal : 32|32@1+ (0.0001280018,0) [0|0] "ml" Vector__XXX

BO_TX_BU_ 830 : WPC,WPC2;
CM_ BO_ 2172675331 "[P] Periodic";
CM_ SG_ 2172675331 IEB_RegenTqLimitNmVal_Rear "IEB_RegenTorqueLimitValue Rear";
CM_ SG_ 2172675331 IEB_DrvWhlSlipFlg_Frnt "Slip status of driving wheel ##2G##ESC ? EBS2 ? CF_Brk_DrvWhlSlipFlg";
CM_ SG_ 2172675331 IEB_IndDriftMode "Signal for feedback from AVNT drift mode ON/OFF command";
CM_ SG_ 2172675331 IEB_TCS_Req "IEB_TCS_Request";
CM_ SG_ 2172675331 IEB_RSC_Req "IEB_RSC_Request";
CM_ SG_ 2172675331 TCS_TqFlag_Frnt "TCS_TorqueFlag_Front";
CM_ SG_ 2172675331 TCS_TqFlag_Rear "TCS_TorqueFlag_Rear";
CM_ SG_ 2172675331 RSC_TqFlag_Frnt "RSC_TorqueFlag_Front";
CM_ SG_ 2172675331 RSC_TqFlag_Rear "RSC_TorqueFlag_Rear";
CM_ SG_ 2172675331 TCS_TqIntrvntnVal_Frnt "TCS_TorqueInterventionValue_Front";
CM_ SG_ 2172675331 TCS_TqIntrvntnVal_Rear "TCS_TorqueInterventionValue_Rear";
CM_ SG_ 2172675331 RSC_TqIntrvntnVal_Frnt "RSC_TorqueInterventionValue_Front";
CM_ SG_ 2172675331 RSC_TqIntrvntnVal_Rear "RSC_TorqueInterventionValue_Rear";
CM_ BO_ 2172675330 "[P] Periodic";
CM_ SG_ 2172675330 IEB_Sta "IEB_Status ##2G##ESC - EBS1 - CF_Brk_EBSStat";
CM_ SG_ 2172675330 IEB_SnsrFailSta "IEB_SensorFailStatus ##2G##ESC - EBS1 - CF_Brk_SnsFail";
CM_ SG_ 2172675330 IEB_EstTtlBrkFrcNmVal "IEB_EstimatedTotalBrakeForceValue ##2G##ESC - EBS1 - CR_Brk_EstTot_Nm";
CM_ SG_ 2172675330 IEB_RbsWrngLmpSta "IEB_RbsWarningLamp ##2G##ESC - EBS1 - CF_Brk_RBSWLamp";
CM_ SG_ 2172675330 IEB_StrkDpthPcVal "IEB_StrokeDepthPcValue ##2G##ESC - EBS2 - CR_Brk_StkDep_Pc";
CM_ SG_ 2172675330 IEB_EstDpthPcVal "IEB_EstimatedPedalDepthValue ##2G##ESC - EBS2 - CR_Brk_Est_StkDep_Pc";
CM_ SG_ 2172675330 IEB_AbsNGearReq "IEB_AbsNGearRequest ##2G##ESC - TCS11 - CF_Brk_AbsNReq";
CM_ SG_ 2172675330 IEB_EstBrkPdlValVldSta "IEB_EstimatedBrakePedalValueValidityStatus ##2G##ESC - EBS2 - CF_Brk_Est_StkValid";
CM_ SG_ 2172675330 IEB_VacSysDfctvSta "IEB_VacuumSystemDefectiveStatus ##2G##ESC - EBS1 - CF_Brk_VacuumSysDef";
CM_ SG_ 2172675330 IEB_RegenTqLimitNmVal_Frnt "IEB_RegenTorqueLimitValue ##2G##ESC - EBS1 - CR_Brk_RegenTqLimit_Nm";
CM_ BO_ 2231452930 "[P] Periodic";
CM_ SG_ 2231452930 DATC_AcnECompOpSta "DATC_AirconElectricCompressorOperationStatus";
CM_ SG_ 2231452930 DATC_HVCompIntlkSta "DATC_HighVoltageCompressorInterlockStatus";
CM_ SG_ 2231452930 DATC_HVIntDischrgLkReq "DATC_HighVoltageInterlockDischargeRequest";
CM_ SG_ 2231452930 DATC_AcnECompMaxReqPwrVal "DATC_AirconElectricalCompressorMaximumRequestPowerValue";
CM_ SG_ 2231452930 DATC_AcnCompFltSta "DATC_AirconElectricCompressorFaultStatus";
CM_ SG_ 2231452930 DATC_AcnECompCnsmptPwrVal "DATC_AirconElectricalCompressorConsumptionPowerValue";
CM_ SG_ 2231452930 DATC_MainRlyOnOffReq "DATC_MainRelayoffRequest";
CM_ SG_ 2231452930 DATC_MixDfgSelSta "DATC_MixDefogSelectStatus";
CM_ SG_ 2231452930 DATC_BattChlrVlvSta "Battery chiller valve status";
CM_ SG_ 2231452930 DATC_WaterPmpOnReq "DATC_WaterPumpOnRequest";
CM_ SG_ 2231452930 DATC_AcnECompSpdVal "DATC_AirconElectricalCompressorSpeedValue";
CM_ SG_ 2231452930 DATC_AcnCompSlpModCodVal "DATC_AirconCompressorSleepModeCodeValue";
CM_ BO_ 2231452931 "[P] Periodic";
CM_ SG_ 2231452931 DATC_AcnCompWaitCodVal "DATC_AirconCompressorWaitCode";
CM_ SG_ 2231452931 DATC_PeEwpRPMReq "DATC_PeEwpRpmRequest";
CM_ SG_ 2231452931 DATC_AEwpSpdRpmReq "DATC_AsistenceEwpSpeedRpmRequest";
CM_ SG_ 2231452931 DATC_RadFanReq_Duty "This signal indicates Request cooling fan speed to cool HVAC System (Duty)";
CM_ SG_ 2231452931 DATC_OutTempSnsrVal "DATC_OutsideTemperatureSensorValue";
CM_ SG_ 2231452931 DATC_DfgSw "DATC_DefogSwitch";
CM_ SG_ 2231452931 DATC_BattChlrVlv_FltCode "Battery Chiller Filt Code";
CM_ SG_ 2231452931 DATC_BattEvapVlvSta "BATTERY COOL V/V (EVAP) STATUS";
CM_ SG_ 2231452931 DATC_BattEvapVlv_FltCode "BATTERY COOL V/V (EVAP) FltCode";
CM_ SG_ 2231452931 DATC_SSC_EngStrtReq "Engine start request in SSC state";
CM_ BO_ 2231452929 "[P] Periodic";
CM_ SG_ 2231452929 DATC_Crc1Val "DATC_CyclicRedundancyCheck1Value";
CM_ SG_ 2231452929 DATC_AlvCnt1Val "DATC_AliveCounter1Value";
CM_ SG_ 2231452929 DATC_PtcRlySta "DATC_PtcRelayStatus";
CM_ SG_ 2231452929 DATC_ManufacturerTyp "DATC_ManufacturerType";
CM_ SG_ 2231452929 DATC_AcnCompTyp "DATC_AirconCompressorType";
CM_ SG_ 2231452929 DATC_Cooldown "Complete of cooldown";
CM_ SG_ 2231452929 DATC_AcnReq "DATC_AirconRequest";
CM_ SG_ 2231452929 DATC_BlwSta "DATC_BlowerStatus";
CM_ SG_ 2231452929 DATC_BlwMaxSta "DATC_BlowerMaxStatus";
CM_ SG_ 2231452929 DATC_EngStrtReq "DATC_EngineStartRequest";
CM_ SG_ 2231452929 DATC_IsgInhbtReq "DATC_IsgInhibitRequset";
CM_ SG_ 2231452929 DATC_AcnCompOnReq "DATC_AirconCompressorOnRequest";
CM_ SG_ 2231452929 DATC_SrvLmpReq "DATC_ServiceLampRequest";
CM_ SG_ 2231452929 DATC_EcvFltSta "DATC_EcvFaultStatus";
CM_ SG_ 2231452929 DATC_CalcAcnCompTqVal "DATC_CalculatedAirconCompressortorqueValue";
CM_ BO_ 2231452932 "[P] Periodic";
CM_ SG_ 2231452932 DATC_SSC_InhbtReq "Request to EMS not to enter SSC";
CM_ SG_ 2231452932 DATC_EngIdlRpmUpReq "DATC_EngineIdleRpmUpRequest";
CM_ SG_ 2231452932 DATC_MaxBlwVolt "DATC_MaxBlowerVoltage";
CM_ SG_ 2231452932 DATC_BlwSta_Rr "DATC_BlowerStatus_Rear";
CM_ SG_ 2231452932 DATC_BattEwpOpReq "Battery EWP Operating Request";
CM_ BO_ 2290230530 "[P] Periodic";
CM_ SG_ 2290230530 CLU_RefuelWrnSta "CLU_RefuelWarningStatus";
CM_ SG_ 2290230530 CLU_DrvngModSwSta "CLU_DrivingModeSwitchStatus";
CM_ SG_ 2290230530 CLU_FuelLvlSta "CLU_FuelLevelStatus";
CM_ SG_ 2290230530 CLU_SRSWrngLmpSta "CLU_SRSWarningLampStatus";
CM_ SG_ 2290230530 CLU_TerrainModSwSta "CLU_TerrainModeSwitchStatus";
CM_ SG_ 2290230530 CLU_OdoVal "CLU_OdometerValue";
CM_ BO_ 2290230529 "[P] Periodic";
CM_ SG_ 2290230529 CLU_Crc2Val "CLU_CyclicRedundancyCheck2Value";
CM_ SG_ 2290230529 CLU_AlvCnt2Val "CLU_AliveCounter2Value";
CM_ SG_ 2290230529 CLU_DTEVal "CLU_DTEValue";
CM_ SG_ 2290230529 CLU_TripUnitSta "CLU_TripUnitStatus";
CM_ SG_ 2290230529 CLU_LoFuelWrngSta "CLU_LowFuelWarningStatus";
CM_ SG_ 2290230529 CLU_RefuelDetSta "CLU_RefuelDetectedStatus";
CM_ SG_ 2290230529 CLU_TerrainMainSwSta "CLU_TerrainMainSwitchStatus";
CM_ BO_ 2315421697 "[PE] Periodic and On Event";
CM_ SG_ 2315421697 CCU_AP_OTA_Crc1Val "CCU_AP_OTA_CyclicRedundancyCheck1Value";
CM_ SG_ 2315421697 CCU_AP_OTA_AlvCnt1Val "CCU_AP_OTA_AliveCounter1Value";
CM_ SG_ 2315421697 CCU_OTA_mode "OTA_mode";
CM_ SG_ 2315421697 CCU_OTA_IG3On_request "IG3 Rly ON request";
CM_ SG_ 2315421697 CCU_OTA_Cond_Request "CCU_OTA_CondRequest";
CM_ SG_ 2315421697 CCU_OTA_Tele_Cranking "Vehicle cranking request signfal for OTA Update";
CM_ SG_ 2315421697 OTA_UI_Ready_request "OTA UI Ready";
CM_ SG_ 2315421697 OTA_Result "¾÷µ¥ÀÌÆ® °á°ú";
CM_ SG_ 2315421697 CF_AVN_InterAutoLockMode_Set2_Co "USM Request for Charing Connector Locking Mode (Auto/Lock/Unlock)";
CM_ BO_ 2470763009 "[EC] On Event and On Change";
CM_ SG_ 2470763009 CLU_Crc9Val "CLU_CyclicRedundancyCheck9Value";
CM_ SG_ 2470763009 CLU_AlvCnt9Val "CLU_AliveCounter9Value";
CM_ SG_ 2470763009 USM_MdLmpClrSetReq "USM_MoodLampColorSetRequest";
CM_ SG_ 2470763009 USM_RrWiperRevSetReq "USM_RearWiperReverseSetRequest";
CM_ SG_ 2470763009 USM_RrStRemindSetReq "USM_RrseatReminderSetRequest(2nd :General: CLU20/CF_Clu_RrSeatRemindNValueSet)";
CM_ SG_ 2470763009 USM_RrWpcSetReq "USM_RearWpcSetRequest";
CM_ SG_ 2470763009 USM_WpcSetReq "USM_WpcSetRequest";
CM_ SG_ 2470763009 USM_SeqLmpSetReq "USM_SequencialLampSetRequest";
CM_ SG_ 2470763009 USM_UnlckWlcmSetReq "USM_UnlockWelcomeSetRequest";
CM_ SG_ 2470763009 USM_SmrtWlcmSetReq "USM_SmartWelcomeSetRequest";
CM_ SG_ 2470763009 USM_UipSetReq "2nd General: CF_Clu_UIPNValueSet";
CM_ SG_ 2470763009 USM_DigitalKeyEnblSetReq "Request to set the Digital Key ON or OFF(2nd General DB: CF_Clu_DigitalKeyNValueSet)";
CM_ SG_ 2470763009 USM_OwnerPhnRegSetReq "2nd general DB: CF_Clu_OwnerPhoneNValueSet";
CM_ SG_ 2470763009 USM_NFCCard1RegSetReq "2nd General DB:CF_Clu_NFCCard1NValueSet";
CM_ SG_ 2470763009 USM_NFCCard2RegSetReq "2nd General DB:CF_Clu_NFCCard2NValueSet";
CM_ SG_ 2470763009 USM_ProcStpReq "2nd General DB:CF_Clu_ProcessStopReq";
CM_ SG_ 2470763009 USM_PwrAutoOffTimeSetReq "USM_PowerAutoofftimeSetRequest";
CM_ SG_ 2470763009 USM_RrStRemindSetReq_RestMode "Request to set  Restmod of Rear Seat remind";
CM_ SG_ 2470763009 USM_1stRrStRemindSetReq "USM_RrseatReminderSetRequest(2nd :General: CLU21/CF_Clu_1stRrSeatRemindNValueSet)";
CM_ SG_ 2470763009 USM_Wpc2SetReq "USM_Wpc2SetRequest";
CM_ BO_ 742 "[PE] Periodic and On Event";
CM_ SG_ 742 SGU_FltSta "It indicates if SGU is normal or fault";
CM_ SG_ 742 SGU_BlindOnOffSet "It indicates smart glass user setting for roll blind operation.";
CM_ SG_ 742 SGU_BlindOpenReq "Blind Open Command by SGU";
CM_ SG_ 742 SGU_FltVal "It indicates details of SGU fault status";
CM_ SG_ 742 SGU_Roof_OprLv "It indicates tranmittance of Roof Smart Glass";
CM_ SG_ 742 SGU_2ndLeftDoor_OprLv "It indicates tranmittance of 2nd Row Left Door Smart Glass";
CM_ SG_ 742 SGU_2ndRightDoor_OprLv "It indicates transmittance of 2nd Row Right Door Smart Glass";
CM_ SG_ 742 SGU_3rdLeftDoor_OprLv "It Indicates transmittance of 3rd Row Left Door Smart Glass";
CM_ SG_ 742 SGU_3rdRightDoor_OprLv "It Indicates transmittance of 3rd Row Right Door Smart Glass";
CM_ SG_ 742 SGU_RearWindow_OprLv "It indicates transmittance of Rear Window Smart Glass";
CM_ SG_ 742 SGU_OprLvVehicleSet "It indicates Smart Glass Maximum Operation Level Setting Value for each vehicles.";
CM_ SG_ 742 SGU_CH1_VoltageVal "It indicates CH1 Alteranting Current voltage value of  smart glass unit";
CM_ SG_ 742 SGU_CH2_VoltageVal "It indicates CH2 Alternating Current voltage value of smart glass unit";
CM_ SG_ 742 SGU_RdySta "It indicates if SGU is ready or not to operate smart glass";
CM_ BO_ 763 "[PE] Periodic and On Event";
CM_ SG_ 763 SBCM_DRV_Crc3Val "SBCM_DRV_CyclicRedundancyCheck3Value";
CM_ SG_ 763 CDM_TypeOption "CDM_HS_OptionType";
CM_ SG_ 763 SBCM_DRV_AlvCnt3Val "SBCM_DRV_AliveCounter3Value";
CM_ SG_ 763 CDM_ImmeChgSw_SBCM "State of Immediate Charging Switch";
CM_ SG_ 763 CDM_OpnClsState_SBCM "CDM_HS_ OpenCloseState";
CM_ SG_ 763 CDM_WarnMsg_SBCM "CDM_HS_WarningMessage";
CM_ SG_ 763 CDM_CmdStatus_SBCM "CDM_HS_CommandStatus";
CM_ SG_ 763 Hood_TypeOption "E-Hood_Option Type";
CM_ SG_ 763 CDM_GbtImmeChgSw_SBCM "State of Immediate Charging Switch";
CM_ SG_ 763 CDM_GbtOpnClsState_SBCM "CDM_HS_ OpenCloseState";
CM_ SG_ 763 CDM_GbtWarnMsg_SBCM "CDM_HS_WarningMessage";
CM_ BO_ 761 "[PE] Periodic and On Event";
CM_ SG_ 761 SBCM_AST_Crc3Val "SBCM_AST_CyclicRedundancyCheck3Value";
CM_ SG_ 761 SBCM_AST_AlvCnt3Val "SBCM_AST_AliveCounter3Value";
CM_ SG_ 761 SBCM_Longkey_ASTDrAtClsSwSta "FCS Power Door Long key Status";
CM_ SG_ 761 Hood_TypeOption_AST "E-Hood_Option Type";
CM_ BO_ 758 "[PE] Periodic and On Event";
CM_ SG_ 758 SBCM_DRV_Crc2Val "SBCM_DRV_CyclicRedundancyCheck2Value";
CM_ SG_ 758 DoorLock_CtrlDrLkUnLkSwSta_SBCM "Central Door Lock/Unlock Switch State";
CM_ SG_ 758 SBCM_DRV_AlvCnt2Val "SBCM_DRV_AliveCounter2Value";
CM_ SG_ 758 CDMAutoWashModeSet_SBCM "Auto wash mode set signal for CDM from SBCM_DRV";
CM_ SG_ 758 ECMMRR_PLUS "ECM Voltage value";
CM_ BO_ 2344811012 "[P] Periodic";
CM_ SG_ 2344811012 xEV_BattRCHTimeEst "calculated charging power by estimated output OBC power";
CM_ SG_ 2344811012 EV_DischrgCurrLimForV2X "Discharge Current Limit(for V2X)";
CM_ SG_ 2344811012 xEV_Bms_IsolDetDeactFuncSta "xEV_Isolation Detection Circuit Deactivate Function Status (GDS Function)";
CM_ SG_ 2344811012 xEV_Bms_CellBalDeactFuncSta "xEV_Cell Balancing Deactivate Function Status (GDS Function)";
CM_ SG_ 2344811012 EV_HiddenSOC_ChangeReq "Hidden SOC Change alarm";
CM_ SG_ 2344811012 EV_V2XDischrgLimSocVal_SYNC "Feedback SOC of  V2X discharge limitation for sync by BMS";
CM_ SG_ 2344811012 xEV_BMS_SOC_2nd "2nd SOC for NEV (Unit 0.05%)";
CM_ BO_ 2344811011 "[P] Periodic";
CM_ SG_ 2344811011 PHEV_SubInltTempVal "PHEV_SubInletTemperatureValue";
CM_ SG_ 2344811011 xEV_12VAlarmReqForICU "xEV_12VBatteryAlarmRequestForICU";
CM_ SG_ 2344811011 xEV_AuxBattChrgReq "Aux. Battery Charge Request Flag";
CM_ SG_ 2344811011 xEV_12VDarkCurrAlarmForICU "xEV_12VDarkCurrentAlarmForICU";
CM_ SG_ 2344811011 xEV_12VBatVLmt "xEV_12VBatteryVoltageLimit";
CM_ SG_ 2344811011 xEV_CharBatInfoReqForSDC "xEV_ChargeBatteryInformationRequestForSDC";
CM_ SG_ 2344811011 xEV_ClimateOffReq "xEV_ClimateOffRequest";
CM_ SG_ 2344811011 xEV_MainRlyOnRetrySta "xEV_MainRelayONRetryStatus";
CM_ SG_ 2344811011 xEV_Bms_BlackBox_Data_req "For Saving BMS data set, this signal transmits to MCU";
CM_ SG_ 2344811011 xEV_12V_BatDchCurrLmt "xEV_12VBatteryDischargeCurrentLimit";
CM_ SG_ 2344811011 xEV_12VChargeReq "xEV_12V BatteryChargeRequest";
CM_ SG_ 2344811011 xEV_12V_CurrFltDetectReq "xEV_12VBatteryCurrentSensorFaultDetectRequest";
CM_ SG_ 2344811011 xEV_PRATempSnsVal_ "PRA Temperature #1 (Relay Busbar Temperature #1)";
CM_ SG_ 2344811011 xEV_PRATempSns2Val_ "PRA Temperature #2 (Relay Busbar Temperature #2)";
CM_ SG_ 2344811011 xEV_12VRlyOnSwReq "xEV_12VRelayOnSwitchRequest";
CM_ BO_ 2344811010 "[P] Periodic";
CM_ SG_ 2344811010 xEV_BattCurrVal "xEV_BatteryCurrentValue";
CM_ SG_ 2344811010 xEV_MinBattTempVal "xEV_MinimumBatteryTemperatureValue";
CM_ SG_ 2344811010 xEV_MaxBattTempVal "xEV_MaximumBatteryTemperatureValue";
CM_ SG_ 2344811010 xEV_FanSpdStpSta "xEV_FanSpeedStepStatus";
CM_ SG_ 2344811010 xEV_12VRlyOffAlrmReq "xEV_12VRelayOffAlarmRequest";
CM_ SG_ 2344811010 xEV_12VRlyOnAlrmReq "xEV_12VRelayOnAlarmRequest";
CM_ SG_ 2344811010 xEV_DiagGrpVal "xEV_DiagnosticGroupValue";
CM_ SG_ 2344811010 xEV_DiagMonVal "xEV_DiagnosticMonitorValue";
CM_ SG_ 2344811010 xEV_SocDis "xEV_StateOfChargeDisplay";
CM_ BO_ 2344811009 "[P] Periodic";
CM_ SG_ 2344811009 BMS_Crc2Val "BMS_CyclicRedundancyCheck2Value";
CM_ SG_ 2344811009 BMS_AlvCnt2Val "BMS_AliveCounter2Value";
CM_ SG_ 2344811009 xEV_SrvLmpReq "xEV_ServiceLampRequest";
CM_ SG_ 2344811009 xEV_MainRlyOnSta "xEV_MainRelayOnStatus";
CM_ SG_ 2344811009 xEV_SysFltSta "xEV_SystemFaultStatus";
CM_ SG_ 2344811009 EV_Unreliable_SOC "Unreliable SOC Alarm FLAG";
CM_ SG_ 2344811009 xEV_BattRmnEnrgVal "xEV_BatteryRemainEnergyValue";
CM_ SG_ 2344811009 xEV_InltTempVal "xEV_InletTemperatureValue";
CM_ SG_ 2344811009 xEV_MinBattCelVoltVal "xEV_MinimumBatteryCellVoltageValue";
CM_ SG_ 2344811009 xEV_MaxBattCelVoltVal "xEV_MaximumBatteryCellVoltageValue";
CM_ BO_ 733 "[PE] Periodic and On Event";
CM_ SG_ 733 CMS_LH_Crc1Val "CMS_LH_CyclicRedundancyCheck1Value";
CM_ SG_ 733 CMS_LH_AlvCnt1Val "CMS_LH_AliveCounter1Value";
CM_ SG_ 733 CMS_LHVerPosVal "LH Outside Mirror Vertical Position sensor value";
CM_ SG_ 733 CMS_LHHorPosVal "LH Outside Mirror Horizontal Position Sensor Voltage";
CM_ SG_ 733 Monitor_ViewPanningCmd "Monitor_ViewPanningCommand";
CM_ BO_ 721 "[P] Periodic";
CM_ SG_ 721 HU_DR_Position_Status "DR Position status";
CM_ SG_ 721 HU_DR_Altitude_Status "DR Altitude Status";
CM_ SG_ 721 HU_DR_Altitude "range [-400,10000]";
CM_ SG_ 721 HU_DR_Heading_Status "DR Heading Status";
CM_ SG_ 721 HU_DR_Speed_Status "DR Speed status";
CM_ SG_ 721 HU_DR_DirectionSwitch_Sta "DR DirectionSwitch Status";
CM_ SG_ 721 HU_DR_Direction "DR Direction, Backward";
CM_ SG_ 721 HU_DR_GyroCalib_Sta "DR Gyro Calibration Status";
CM_ SG_ 721 HU_DR_TachoCalib_Sta "DR Tacho Calibration Status";
CM_ SG_ 721 HU_DR_GNSS_Fix_Age "Time since last GNSS fix";
CM_ BO_ 722 "[P] Periodic";
CM_ SG_ 722 HU_DR_Latitude "1sc(semi-cicle)= pi rad=180  /   unit : 2^-31sc  /  range [-1/2~1/2] sc";
CM_ SG_ 722 HU_DR_Longitude "1sc(semi-circle)=pi rad=180 / unit:2^-31sc / range:[-1, 1]sc";
CM_ BO_ 723 "[P] Periodic";
CM_ SG_ 723 HU_DR_Heading "1sc(semi-circle)=pi rad=180 / unit=2^-15sc / range:[0,2]SC";
CM_ SG_ 723 HU_DR_Speed "unit : 1cm/s";
CM_ BO_ 1915 "[TP] Transport Protocol";
CM_ BO_ 1914 "[TP] Transport Protocol";
CM_ BO_ 2307024132 "[P] Periodic";
CM_ SG_ 2307024132 HEV_RbmSta_2nd "HEV_RateBasedMonitoringStatus";
CM_ SG_ 2307024132 HEV_OilLifeRatio "Remaining engine oil life with % unit";
CM_ SG_ 2307024132 HEV_OilLifeEna "Enabling information if engine oil life monitoring from EMS is applied or not";
CM_ SG_ 2307024132 HEV_OilLifeWarn "Request to activate engine oil life warning";
CM_ SG_ 2307024132 HEV_ExtSoakTimeVal "The additional Soak Time information extended from HEV_SoakTimeVal of EMS_08_100ms";
CM_ SG_ 2307024132 HEV_RECTrigSta "VCRM trigger bit by REC";
CM_ SG_ 2307024132 HEV_PendingTrigSta "VCRM trigger bit by pending DTC";
CM_ BO_ 1907 "[TP] Transport Protocol";
CM_ BO_ 830 "[PE] Periodic and On Event";
CM_ SG_ 830 USM_CmdWPC2Sta "USM_CommandWPC2Status";
CM_ SG_ 830 WPC2_SWVerMajor1 "First Word(ASCII) in WPC2 S/W Ver";
CM_ SG_ 830 WPC2_PhnLftWrngSta "WPC2_PhoneLeftWarningStatus";
CM_ SG_ 830 WPC2_SWVerMinor1 "Second Word(ASCII) in WPC2 S/W Ver";
CM_ SG_ 830 WPC2_SWVerMinor2 "Third Word(ASCII) in WPC2 S/W Ver";
CM_ SG_ 830 WPC2_ResetOpSta "This signal indicates whether the reset operation has been completed or not";
CM_ BO_ 1906 "[TP] Transport Protocol";
CM_ BO_ 2307024130 "[P] Periodic";
CM_ SG_ 2307024130 HEV_IgnCycCntVal "HEV_IgnitionCycleCounterValue";
CM_ SG_ 2307024130 HEV_SoakTimeVal "HEV_SoakTimeValue";
CM_ SG_ 2307024130 HEV_SoakTimeErrSta "HEV_SoakTimeErrorStatus";
CM_ SG_ 2307024130 HEV_SoakTimeOvrSta "HEV_SoakTimeOverStatus";
CM_ SG_ 2307024130 HEV_FuelRunOutSta "HEV_FuelRunOutStatus";
CM_ SG_ 2307024130 HEV_FuelRunOutDetSta "HEV_FuelRunOutDetectStatus";
CM_ SG_ 2307024130 HEV_FuelCnsmptSumVal "HEV_FuelConsumptionSumValue";
BA_DEF_ BO_  "DiagState" ENUM  "No","Yes";
BA_DEF_ BO_  "DiagResponse" ENUM  "No","Yes";
BA_DEF_ BO_  "DiagRequest" ENUM  "No","Yes";
BA_DEF_ BO_  "TpMessage" ENUM  "No","Yes";
BA_DEF_ BO_  "UsrMsgIDSforwardDeviation" INT 0 100;
BA_DEF_ BO_  "UsrMsgIDSbackwardDeviation" INT 50 1000;
BA_DEF_ BO_  "GenMsgCycleTime" INT 0 2000;
BA_DEF_ BO_  "GenMsgStartDelayTime" INT 0 2000;
BA_DEF_ BO_  "GenMsgSendType" ENUM  "Cyclic","NoMsgSendType";
BA_DEF_ BO_  "GenMsgCycleTimeFast" INT 0 500;
BA_DEF_ BO_  "GenMsgDelayTime" INT 0 20;
BA_DEF_ BO_  "GenMsgILSupport" ENUM  "No","Yes";
BA_DEF_ BO_  "GenMsgNrOfRepetition" INT 0 3;
BA_DEF_ BO_  "NmMessage" ENUM  "No","Yes";
BA_DEF_ BO_  "NWM-Botschaft" ENUM  "No","Yes";
BA_DEF_ BO_  "TpTxIndex" INT 0 65535;
BA_DEF_ BO_  "VFrameFormat" ENUM  "StandardCAN","ExtendedCAN","reserved","reserved","reserved","reserved","reserved","reserved","reserved","reserved","reserved","reserved","reserved","reserved","StandardCAN_FD","ExtendedCAN_FD";
BA_DEF_ SG_  "UserSigValidity" ENUM  "B+","ACC","IG","IG1","IG2","IG3","IG1 or IG2","IG1 or IG3","Undef";
BA_DEF_ SG_  "TimeoutValue" STRING ;
BA_DEF_ SG_  "UsrSigPurpose" ENUM  "Undef","FN","DIAG","DIAG(Req)","DIAG(Res)","DIAG(Phy)","DEV","CCP(Req)","CCP(Res)","NM","TP";
BA_DEF_ SG_  "GenSigStartValue" INT 0 1215752192;
BA_DEF_ SG_  "NetworkRequest" ENUM  "Yes","No";
BA_DEF_ SG_  "NetworkRequestHoldingTime" INT 0 65535;
BA_DEF_ SG_  "Description" STRING ;
BA_DEF_ SG_  "Version" STRING ;
BA_DEF_ SG_  "GenSigEnvVarType" ENUM  "Int","Float","Undef";
BA_DEF_ SG_  "GenSigSendType" ENUM  "Cyclic","OnWrite","OnWriteWithRepetition","OnChange","OnChangeWithRepetition","IfActive","IfActiveWithRepetition","NoSigSendType","OnChangeAndIfActive","OnChangeAndIfActiveWithRepetition";
BA_DEF_ SG_  "GwSigLatencyTime" INT 0 65536;
BA_DEF_ SG_  "GwSigMissingSourceType" ENUM  "Undef","OldValue","DefaultValue","InitialValue";
BA_DEF_ SG_  "NWM-WakeupAllowed" ENUM  "<n.a.>";
BA_DEF_ SG_  "RoutingFactor" INT 1 1215752192;
BA_DEF_ SG_  "SystemSignalLongSymbol" STRING ;
BA_DEF_REL_ BU_SG_REL_  "GenSigTimeoutTime" INT 0 7000;
BA_DEF_DEF_  "DiagState" "No";
BA_DEF_DEF_  "DiagResponse" "No";
BA_DEF_DEF_  "DiagRequest" "No";
BA_DEF_DEF_  "TpMessage" "No";
BA_DEF_DEF_  "UsrMsgIDSforwardDeviation" 10;
BA_DEF_DEF_  "UsrMsgIDSbackwardDeviation" 100;
BA_DEF_DEF_  "GenMsgCycleTime" 200;
BA_DEF_DEF_  "GenMsgStartDelayTime" 0;
BA_DEF_DEF_  "GenMsgSendType" "NoMsgSendType";
BA_DEF_DEF_  "GenMsgCycleTimeFast" 40;
BA_DEF_DEF_  "GenMsgDelayTime" 20;
BA_DEF_DEF_  "GenMsgILSupport" "Yes";
BA_DEF_DEF_  "GenMsgNrOfRepetition" 3;
BA_DEF_DEF_  "NmMessage" "No";
BA_DEF_DEF_  "NWM-Botschaft" "No";
BA_DEF_DEF_  "TpTxIndex" 0;
BA_DEF_DEF_  "VFrameFormat" "StandardCAN";
BA_DEF_DEF_  "UserSigValidity" "IG";
BA_DEF_DEF_  "TimeoutValue" "";
BA_DEF_DEF_  "UsrSigPurpose" "FN";
BA_DEF_DEF_  "GenSigStartValue" 0;
BA_DEF_DEF_  "NetworkRequest" "No";
BA_DEF_DEF_  "NetworkRequestHoldingTime" 0;
BA_DEF_DEF_  "Description" "";
BA_DEF_DEF_  "Version" "";
BA_DEF_DEF_  "GenSigEnvVarType" "Undef";
BA_DEF_DEF_  "GenSigSendType" "NoSigSendType";
BA_DEF_DEF_  "GwSigLatencyTime" 40;
BA_DEF_DEF_  "GwSigMissingSourceType" "Undef";
BA_DEF_DEF_  "NWM-WakeupAllowed" "<n.a.>";
BA_DEF_DEF_  "RoutingFactor" 1;
BA_DEF_DEF_REL_ "GenSigTimeoutTime" 500;
BA_DEF_DEF_  "SystemSignalLongSymbol" "";
BA_ "VFrameFormat" BO_ 2172675331 1;
BA_ "GenMsgNrOfRepetition" BO_ 2172675331 0;
BA_ "GenMsgCycleTimeFast" BO_ 2172675331 0;
BA_ "GenMsgCycleTime" BO_ 2172675331 50;
BA_ "GenMsgSendType" BO_ 2172675331 0;
BA_ "VFrameFormat" BO_ 2172675330 1;
BA_ "GenMsgNrOfRepetition" BO_ 2172675330 0;
BA_ "GenMsgCycleTimeFast" BO_ 2172675330 0;
BA_ "GenMsgCycleTime" BO_ 2172675330 50;
BA_ "GenMsgSendType" BO_ 2172675330 0;
BA_ "VFrameFormat" BO_ 2231452930 1;
BA_ "GenMsgNrOfRepetition" BO_ 2231452930 0;
BA_ "GenMsgCycleTimeFast" BO_ 2231452930 0;
BA_ "GenMsgCycleTime" BO_ 2231452930 100;
BA_ "GenMsgSendType" BO_ 2231452930 0;
BA_ "VFrameFormat" BO_ 2231452931 1;
BA_ "GenMsgNrOfRepetition" BO_ 2231452931 0;
BA_ "GenMsgCycleTimeFast" BO_ 2231452931 0;
BA_ "GenMsgCycleTime" BO_ 2231452931 100;
BA_ "GenMsgSendType" BO_ 2231452931 0;
BA_ "VFrameFormat" BO_ 2231452929 1;
BA_ "GenMsgNrOfRepetition" BO_ 2231452929 0;
BA_ "GenMsgCycleTimeFast" BO_ 2231452929 0;
BA_ "GenMsgCycleTime" BO_ 2231452929 100;
BA_ "GenMsgSendType" BO_ 2231452929 0;
BA_ "VFrameFormat" BO_ 2231452932 1;
BA_ "GenMsgNrOfRepetition" BO_ 2231452932 0;
BA_ "GenMsgCycleTimeFast" BO_ 2231452932 0;
BA_ "GenMsgCycleTime" BO_ 2231452932 100;
BA_ "GenMsgSendType" BO_ 2231452932 0;
BA_ "VFrameFormat" BO_ 2290230530 1;
BA_ "GenMsgNrOfRepetition" BO_ 2290230530 0;
BA_ "GenMsgCycleTimeFast" BO_ 2290230530 0;
BA_ "GenMsgSendType" BO_ 2290230530 0;
BA_ "VFrameFormat" BO_ 2290230529 1;
BA_ "GenMsgNrOfRepetition" BO_ 2290230529 0;
BA_ "GenMsgCycleTimeFast" BO_ 2290230529 0;
BA_ "GenMsgSendType" BO_ 2290230529 0;
BA_ "VFrameFormat" BO_ 2315421697 1;
BA_ "GenMsgSendType" BO_ 2315421697 0;
BA_ "VFrameFormat" BO_ 2470763009 1;
BA_ "GenMsgCycleTime" BO_ 2470763009 0;
BA_ "GenMsgSendType" BO_ 742 0;
BA_ "GenMsgSendType" BO_ 763 0;
BA_ "GenMsgSendType" BO_ 761 0;
BA_ "GenMsgSendType" BO_ 758 0;
BA_ "VFrameFormat" BO_ 2344811012 1;
BA_ "GenMsgNrOfRepetition" BO_ 2344811012 0;
BA_ "GenMsgCycleTimeFast" BO_ 2344811012 0;
BA_ "GenMsgSendType" BO_ 2344811012 0;
BA_ "VFrameFormat" BO_ 2344811011 1;
BA_ "GenMsgNrOfRepetition" BO_ 2344811011 0;
BA_ "GenMsgCycleTimeFast" BO_ 2344811011 0;
BA_ "GenMsgSendType" BO_ 2344811011 0;
BA_ "VFrameFormat" BO_ 2344811010 1;
BA_ "GenMsgNrOfRepetition" BO_ 2344811010 0;
BA_ "GenMsgCycleTimeFast" BO_ 2344811010 0;
BA_ "GenMsgSendType" BO_ 2344811010 0;
BA_ "VFrameFormat" BO_ 2344811009 1;
BA_ "GenMsgNrOfRepetition" BO_ 2344811009 0;
BA_ "GenMsgCycleTimeFast" BO_ 2344811009 0;
BA_ "GenMsgSendType" BO_ 2344811009 0;
BA_ "GenMsgSendType" BO_ 733 0;
BA_ "GenMsgNrOfRepetition" BO_ 721 0;
BA_ "GenMsgCycleTimeFast" BO_ 721 0;
BA_ "GenMsgCycleTime" BO_ 721 100;
BA_ "GenMsgSendType" BO_ 721 0;
BA_ "GenMsgNrOfRepetition" BO_ 722 0;
BA_ "GenMsgCycleTimeFast" BO_ 722 0;
BA_ "GenMsgCycleTime" BO_ 722 100;
BA_ "GenMsgSendType" BO_ 722 0;
BA_ "GenMsgNrOfRepetition" BO_ 723 0;
BA_ "GenMsgCycleTimeFast" BO_ 723 0;
BA_ "GenMsgCycleTime" BO_ 723 100;
BA_ "GenMsgSendType" BO_ 723 0;
BA_ "TpTxIndex" BO_ 1915 158;
BA_ "TpMessage" BO_ 1915 1;
BA_ "GenMsgILSupport" BO_ 1915 0;
BA_ "DiagResponse" BO_ 1915 1;
BA_ "GenMsgNrOfRepetition" BO_ 1915 0;
BA_ "GenMsgCycleTimeFast" BO_ 1915 0;
BA_ "GenMsgCycleTime" BO_ 1915 0;
BA_ "TpTxIndex" BO_ 1914 261;
BA_ "TpMessage" BO_ 1914 1;
BA_ "GenMsgILSupport" BO_ 1914 0;
BA_ "DiagResponse" BO_ 1914 1;
BA_ "GenMsgNrOfRepetition" BO_ 1914 0;
BA_ "GenMsgCycleTimeFast" BO_ 1914 0;
BA_ "GenMsgCycleTime" BO_ 1914 0;
BA_ "VFrameFormat" BO_ 2307024132 1;
BA_ "GenMsgNrOfRepetition" BO_ 2307024132 0;
BA_ "GenMsgCycleTimeFast" BO_ 2307024132 0;
BA_ "GenMsgSendType" BO_ 2307024132 0;
BA_ "TpTxIndex" BO_ 1907 158;
BA_ "TpMessage" BO_ 1907 1;
BA_ "GenMsgILSupport" BO_ 1907 0;
BA_ "DiagRequest" BO_ 1907 1;
BA_ "GenMsgNrOfRepetition" BO_ 1907 0;
BA_ "GenMsgCycleTimeFast" BO_ 1907 0;
BA_ "GenMsgCycleTime" BO_ 1907 0;
BA_ "GenMsgSendType" BO_ 830 0;
BA_ "TpTxIndex" BO_ 1906 261;
BA_ "TpMessage" BO_ 1906 1;
BA_ "GenMsgILSupport" BO_ 1906 0;
BA_ "DiagRequest" BO_ 1906 1;
BA_ "GenMsgNrOfRepetition" BO_ 1906 0;
BA_ "GenMsgCycleTimeFast" BO_ 1906 0;
BA_ "GenMsgCycleTime" BO_ 1906 0;
BA_ "VFrameFormat" BO_ 2307024130 1;
BA_ "GenMsgNrOfRepetition" BO_ 2307024130 0;
BA_ "GenMsgCycleTimeFast" BO_ 2307024130 0;
BA_ "GenMsgSendType" BO_ 2307024130 0;
BA_ "Version" SG_ 2172675331 IEB_RegenTqLimitNmVal_Rear "19.05.03";
BA_ "RoutingFactor" SG_ 2172675331 IEB_RegenTqLimitNmVal_Rear 5;
BA_ "UserSigValidity" SG_ 2172675331 IEB_RegenTqLimitNmVal_Rear 3;
BA_ "Description" SG_ 2172675331 IEB_RegenTqLimitNmVal_Rear "Regen Brake Torque limit at rear wheel";
BA_ "Version" SG_ 2172675331 IEB_DrvWhlSlipFlg_Frnt "20.10.02";
BA_ "RoutingFactor" SG_ 2172675331 IEB_DrvWhlSlipFlg_Frnt 5;
BA_ "UserSigValidity" SG_ 2172675331 IEB_DrvWhlSlipFlg_Frnt 3;
BA_ "Description" SG_ 2172675331 IEB_DrvWhlSlipFlg_Frnt "This signal is to indicate the slip status of the driving wheels.";
BA_ "Version" SG_ 2172675331 IEB_IndDriftMode "22.02.04";
BA_ "RoutingFactor" SG_ 2172675331 IEB_IndDriftMode 5;
BA_ "UserSigValidity" SG_ 2172675331 IEB_IndDriftMode 3;
BA_ "Description" SG_ 2172675331 IEB_IndDriftMode "Signal for feedback from AVNT drift mode ON/OFF command";
BA_ "Version" SG_ 2172675331 IEB_TCS_Req "20.04.05";
BA_ "RoutingFactor" SG_ 2172675331 IEB_TCS_Req 5;
BA_ "UserSigValidity" SG_ 2172675331 IEB_TCS_Req 3;
BA_ "Description" SG_ 2172675331 IEB_TCS_Req "ÀÌ ½ÅÈ£´Â IEB_01_10ms ¸Þ½ÃÁöÀÇ TCS ÅäÅ© ½ÅÈ£¿¡ ´ëÇÑ Validity¸¦ ÀÇ¹ÌÇÑ´Ù.



0x1 : TCS_TqIntrvntnVal_Frnt, TCS_TqIntrvntnVal_Rear ½ÅÈ£¿¡ ÀÇÇÑ TCS Á¦¾î

0x2 : TCS_MtrTrgtRpm_Frnt, TCS_MtrTrgtRpm_Rear ½ÅÈ£¿¡ ÀÇÇÑ TCS Á¦¾î";
BA_ "Version" SG_ 2172675331 IEB_RSC_Req "22.01.02";
BA_ "RoutingFactor" SG_ 2172675331 IEB_RSC_Req 5;
BA_ "UserSigValidity" SG_ 2172675331 IEB_RSC_Req 3;
BA_ "Description" SG_ 2172675331 IEB_RSC_Req "Validity of RSC torque signal from IEB_01_10ms";
BA_ "Version" SG_ 2172675331 TCS_TqFlag_Frnt "19.05.03";
BA_ "RoutingFactor" SG_ 2172675331 TCS_TqFlag_Frnt 5;
BA_ "UserSigValidity" SG_ 2172675331 TCS_TqFlag_Frnt 3;
BA_ "Description" SG_ 2172675331 TCS_TqFlag_Frnt "ÀÌ ½ÅÈ£´Â IEB_01_10ms ¸Þ½ÃÁöÀÇ TCS Àü·û ÅäÅ© ½ÅÈ£¿¡ ´ëÇÑ ºÎÈ£¸¦ ÀÇ¹ÌÇÑ´Ù.";
BA_ "Version" SG_ 2172675331 TCS_TqFlag_Rear "19.05.03";
BA_ "RoutingFactor" SG_ 2172675331 TCS_TqFlag_Rear 5;
BA_ "UserSigValidity" SG_ 2172675331 TCS_TqFlag_Rear 3;
BA_ "Description" SG_ 2172675331 TCS_TqFlag_Rear "ÀÌ ½ÅÈ£´Â IEB_01_10ms ¸Þ½ÃÁöÀÇ TCS ÈÄ·û ÅäÅ© ½ÅÈ£¿¡ ´ëÇÑ ºÎÈ£¸¦ ÀÇ¹ÌÇÑ´Ù.";
BA_ "Version" SG_ 2172675331 RSC_TqFlag_Frnt "19.05.03";
BA_ "RoutingFactor" SG_ 2172675331 RSC_TqFlag_Frnt 5;
BA_ "UserSigValidity" SG_ 2172675331 RSC_TqFlag_Frnt 3;
BA_ "Description" SG_ 2172675331 RSC_TqFlag_Frnt "ÀÌ ½ÅÈ£´Â IEB_01_10ms ¸Þ½ÃÁöÀÇ RSC Àü·û ÅäÅ© ½ÅÈ£¿¡ ´ëÇÑ ºÎÈ£¸¦ ÀÇ¹ÌÇÑ´Ù.";
BA_ "Version" SG_ 2172675331 RSC_TqFlag_Rear "19.05.03";
BA_ "RoutingFactor" SG_ 2172675331 RSC_TqFlag_Rear 5;
BA_ "UserSigValidity" SG_ 2172675331 RSC_TqFlag_Rear 3;
BA_ "Description" SG_ 2172675331 RSC_TqFlag_Rear "ÀÌ ½ÅÈ£´Â IEB_01_10ms ¸Þ½ÃÁöÀÇ RSC ÈÄ·û ÅäÅ© ½ÅÈ£¿¡ ´ëÇÑ ºÎÈ£¸¦ ÀÇ¹ÌÇÑ´Ù.";
BA_ "Version" SG_ 2172675331 TCS_TqIntrvntnVal_Frnt "19.05.03";
BA_ "RoutingFactor" SG_ 2172675331 TCS_TqIntrvntnVal_Frnt 5;
BA_ "UserSigValidity" SG_ 2172675331 TCS_TqIntrvntnVal_Frnt 3;
BA_ "Description" SG_ 2172675331 TCS_TqIntrvntnVal_Frnt "TCS Á¦¾î¸¦ À§ÇÑ Àü·û ±¸µ¿ÅäÅ©ÀÇ ¿ä±¸°ªÀ» ÀÇ¹Ì.

ºÎÈ£´Â TCS_TqFlag_Frnt ½ÅÈ£¸¦ ÂüÁ¶.";
BA_ "Version" SG_ 2172675331 TCS_TqIntrvntnVal_Rear "19.05.03";
BA_ "RoutingFactor" SG_ 2172675331 TCS_TqIntrvntnVal_Rear 5;
BA_ "UserSigValidity" SG_ 2172675331 TCS_TqIntrvntnVal_Rear 3;
BA_ "Description" SG_ 2172675331 TCS_TqIntrvntnVal_Rear "TCS Á¦¾î¸¦ À§ÇÑ ÈÄ·û ±¸µ¿ÅäÅ©ÀÇ ¿ä±¸°ªÀ» ÀÇ¹Ì.

ºÎÈ£´Â TCS_TqFlag_Rear ½ÅÈ£¸¦ ÂüÁ¶.";
BA_ "Version" SG_ 2172675331 RSC_TqIntrvntnVal_Frnt "19.05.03";
BA_ "RoutingFactor" SG_ 2172675331 RSC_TqIntrvntnVal_Frnt 5;
BA_ "UserSigValidity" SG_ 2172675331 RSC_TqIntrvntnVal_Frnt 3;
BA_ "Description" SG_ 2172675331 RSC_TqIntrvntnVal_Frnt "RSC Á¦¾î¸¦ À§ÇÑ Àü·û ±¸µ¿ÅäÅ©ÀÇ ¿ä±¸°ªÀ» ÀÇ¹Ì.

ºÎÈ£´Â RSC_TqFlag_Frnt ½ÅÈ£¸¦ ÂüÁ¶.";
BA_ "Version" SG_ 2172675331 RSC_TqIntrvntnVal_Rear "19.05.03";
BA_ "RoutingFactor" SG_ 2172675331 RSC_TqIntrvntnVal_Rear 5;
BA_ "UserSigValidity" SG_ 2172675331 RSC_TqIntrvntnVal_Rear 3;
BA_ "Description" SG_ 2172675331 RSC_TqIntrvntnVal_Rear "RSC Á¦¾î¸¦ À§ÇÑ ÈÄ·û ±¸µ¿ÅäÅ©ÀÇ ¿ä±¸°ªÀ» ÀÇ¹Ì.

ºÎÈ£´Â RSC_TqFlag_Rear ½ÅÈ£¸¦ ÂüÁ¶.";
BA_ "Version" SG_ 2172675330 IEB_Sta "19.06.01";
BA_ "RoutingFactor" SG_ 2172675330 IEB_Sta 5;
BA_ "UserSigValidity" SG_ 2172675330 IEB_Sta 3;
BA_ "Description" SG_ 2172675330 IEB_Sta "EBS Ready Status

¡Ø Àü/ÈÄ·û¿¡ ´ëÇÑ ±¸ºÐÀÌ ¾ø´Â °æ¿ì¿¡´Â 0x0 (Not Ready) / 0x1(Ready) ¸¸ »ç¿ëÇÑ´Ù.

     : Àü·û ±¸µ¿ È¸»ýÁ¦µ¿ Â÷·®ÀÇ °æ¿ì, 0x0 ´Â Front not Ready / 0x1Àº Front only Ready¸¦ ÀÇ¹ÌÇÔ.";
BA_ "Version" SG_ 2172675330 IEB_SnsrFailSta "19.05.02";
BA_ "RoutingFactor" SG_ 2172675330 IEB_SnsrFailSta 5;
BA_ "UserSigValidity" SG_ 2172675330 IEB_SnsrFailSta 3;
BA_ "Version" SG_ 2172675330 IEB_EstTtlBrkFrcNmVal "19.05.02";
BA_ "RoutingFactor" SG_ 2172675330 IEB_EstTtlBrkFrcNmVal 5;
BA_ "UserSigValidity" SG_ 2172675330 IEB_EstTtlBrkFrcNmVal 3;
BA_ "Description" SG_ 2172675330 IEB_EstTtlBrkFrcNmVal "Estimated Total Brake Force";
BA_ "Version" SG_ 2172675330 IEB_RbsWrngLmpSta "19.05.02";
BA_ "RoutingFactor" SG_ 2172675330 IEB_RbsWrngLmpSta 5;
BA_ "UserSigValidity" SG_ 2172675330 IEB_RbsWrngLmpSta 3;
BA_ "Description" SG_ 2172675330 IEB_RbsWrngLmpSta "This signal indicates RBS warning lamp status.";
BA_ "Version" SG_ 2172675330 IEB_StrkDpthPcVal "19.05.02";
BA_ "RoutingFactor" SG_ 2172675330 IEB_StrkDpthPcVal 5;
BA_ "UserSigValidity" SG_ 2172675330 IEB_StrkDpthPcVal 3;
BA_ "Description" SG_ 2172675330 IEB_StrkDpthPcVal "Brake Pedal Stroke Depth";
BA_ "Version" SG_ 2172675330 IEB_EstDpthPcVal "19.05.02";
BA_ "RoutingFactor" SG_ 2172675330 IEB_EstDpthPcVal 5;
BA_ "UserSigValidity" SG_ 2172675330 IEB_EstDpthPcVal 3;
BA_ "Description" SG_ 2172675330 IEB_EstDpthPcVal "Estimated Brake Pedal Depth for SCC";
BA_ "Version" SG_ 2172675330 IEB_AbsNGearReq "19.05.02";
BA_ "RoutingFactor" SG_ 2172675330 IEB_AbsNGearReq 5;
BA_ "UserSigValidity" SG_ 2172675330 IEB_AbsNGearReq 3;
BA_ "Description" SG_ 2172675330 IEB_AbsNGearReq "indigates N gear position request while ABS activation";
BA_ "Version" SG_ 2172675330 IEB_EstBrkPdlValVldSta "19.05.02";
BA_ "RoutingFactor" SG_ 2172675330 IEB_EstBrkPdlValVldSta 5;
BA_ "UserSigValidity" SG_ 2172675330 IEB_EstBrkPdlValVldSta 3;
BA_ "GenSigStartValue" SG_ 2172675330 IEB_EstBrkPdlValVldSta 1;
BA_ "Description" SG_ 2172675330 IEB_EstBrkPdlValVldSta "Estimated Brake pedal value Validity";
BA_ "Version" SG_ 2172675330 IEB_VacSysDfctvSta "19.05.02";
BA_ "RoutingFactor" SG_ 2172675330 IEB_VacSysDfctvSta 5;
BA_ "UserSigValidity" SG_ 2172675330 IEB_VacSysDfctvSta 3;
BA_ "Description" SG_ 2172675330 IEB_VacSysDfctvSta "This signal indicates Vacuum pump ¡°defective¡±.";
BA_ "Version" SG_ 2172675330 IEB_FRAmode_Req "22.10.20";
BA_ "RoutingFactor" SG_ 2172675330 IEB_FRAmode_Req 5;
BA_ "UserSigValidity" SG_ 2172675330 IEB_FRAmode_Req 3;
BA_ "Description" SG_ 2172675330 IEB_FRAmode_Req "This signal requests braking load reduction logic when braking the ABS based on an electric vehicle";
BA_ "Version" SG_ 2172675330 IEB_RegenTqLimitNmVal_Frnt "19.05.03";
BA_ "RoutingFactor" SG_ 2172675330 IEB_RegenTqLimitNmVal_Frnt 5;
BA_ "UserSigValidity" SG_ 2172675330 IEB_RegenTqLimitNmVal_Frnt 3;
BA_ "Description" SG_ 2172675330 IEB_RegenTqLimitNmVal_Frnt "Regen Brake Torque limit at front wheel";
BA_ "Version" SG_ 2231452930 DATC_AcnECompOpSta "17.11.00";
BA_ "RoutingFactor" SG_ 2231452930 DATC_AcnECompOpSta 5;
BA_ "UserSigValidity" SG_ 2231452930 DATC_AcnECompOpSta 7;
BA_ "Version" SG_ 2231452930 DATC_HVCompIntlkSta "17.11.00";
BA_ "RoutingFactor" SG_ 2231452930 DATC_HVCompIntlkSta 5;
BA_ "UserSigValidity" SG_ 2231452930 DATC_HVCompIntlkSta 7;
BA_ "Version" SG_ 2231452930 DATC_HVIntDischrgLkReq "17.11.00";
BA_ "RoutingFactor" SG_ 2231452930 DATC_HVIntDischrgLkReq 5;
BA_ "UserSigValidity" SG_ 2231452930 DATC_HVIntDischrgLkReq 7;
BA_ "Description" SG_ 2231452930 DATC_HVIntDischrgLkReq "This signal indicates forced discharge request when HV PTC Interlock or E-Compressor Interlock is open.";
BA_ "Version" SG_ 2231452930 DATC_AcnECompMaxReqPwrVal "19.08.04";
BA_ "RoutingFactor" SG_ 2231452930 DATC_AcnECompMaxReqPwrVal 5;
BA_ "UserSigValidity" SG_ 2231452930 DATC_AcnECompMaxReqPwrVal 7;
BA_ "Description" SG_ 2231452930 DATC_AcnECompMaxReqPwrVal "0....20440[W] = 00H...3FEH (PH)= 20 * (HEX)[W]";
BA_ "Version" SG_ 2231452930 DATC_AcnCompFltSta "17.11.00";
BA_ "RoutingFactor" SG_ 2231452930 DATC_AcnCompFltSta 5;
BA_ "UserSigValidity" SG_ 2231452930 DATC_AcnCompFltSta 7;
BA_ "Version" SG_ 2231452930 DATC_AcnECompCnsmptPwrVal "19.08.04";
BA_ "RoutingFactor" SG_ 2231452930 DATC_AcnECompCnsmptPwrVal 5;
BA_ "UserSigValidity" SG_ 2231452930 DATC_AcnECompCnsmptPwrVal 7;
BA_ "Description" SG_ 2231452930 DATC_AcnECompCnsmptPwrVal "0¡¦20440[W] = 00H...3FEH (PH)= 20 * (HEX)[W]";
BA_ "Version" SG_ 2231452930 DATC_MainRlyOnOffReq "24.09.00";
BA_ "RoutingFactor" SG_ 2231452930 DATC_MainRlyOnOffReq 5;
BA_ "UserSigValidity" SG_ 2231452930 DATC_MainRlyOnOffReq 3;
BA_ "Version" SG_ 2231452930 DATC_MixDfgSelSta "17.11.00";
BA_ "RoutingFactor" SG_ 2231452930 DATC_MixDfgSelSta 5;
BA_ "UserSigValidity" SG_ 2231452930 DATC_MixDfgSelSta 3;
BA_ "Description" SG_ 2231452930 DATC_MixDfgSelSta "DATC will send this request signal to BMS when controlled in Mix/Def mode.";
BA_ "Version" SG_ 2231452930 DATC_BattChlrVlvSta "22.04.02";
BA_ "RoutingFactor" SG_ 2231452930 DATC_BattChlrVlvSta 5;
BA_ "UserSigValidity" SG_ 2231452930 DATC_BattChlrVlvSta 3;
BA_ "Description" SG_ 2231452930 DATC_BattChlrVlvSta "Battery chiller valve status";
BA_ "Version" SG_ 2231452930 DATC_WaterPmpOnReq "17.11.00";
BA_ "RoutingFactor" SG_ 2231452930 DATC_WaterPmpOnReq 5;
BA_ "UserSigValidity" SG_ 2231452930 DATC_WaterPmpOnReq 3;
BA_ "Version" SG_ 2231452930 DATC_AcnECompSpdVal "17.11.00";
BA_ "RoutingFactor" SG_ 2231452930 DATC_AcnECompSpdVal 5;
BA_ "UserSigValidity" SG_ 2231452930 DATC_AcnECompSpdVal 7;
BA_ "Description" SG_ 2231452930 DATC_AcnECompSpdVal "0 ¡¦65534 [rpm] = 0000H ¡¦ FFFEH, (PH) = 1*(HEX) [rpm]";
BA_ "Version" SG_ 2231452930 DATC_AcnCompSlpModCodVal "17.11.00";
BA_ "RoutingFactor" SG_ 2231452930 DATC_AcnCompSlpModCodVal 5;
BA_ "UserSigValidity" SG_ 2231452930 DATC_AcnCompSlpModCodVal 7;
BA_ "Description" SG_ 2231452930 DATC_AcnCompSlpModCodVal "(PH) = 1 * (HEX) [-]";
BA_ "Version" SG_ 2231452931 DATC_AcnCompWaitCodVal "17.11.00";
BA_ "RoutingFactor" SG_ 2231452931 DATC_AcnCompWaitCodVal 5;
BA_ "UserSigValidity" SG_ 2231452931 DATC_AcnCompWaitCodVal 7;
BA_ "Description" SG_ 2231452931 DATC_AcnCompWaitCodVal "(PH) = 1 * (HEX) [-]";
BA_ "Version" SG_ 2231452931 DATC_PeEwpRPMReq "20.05.02";
BA_ "RoutingFactor" SG_ 2231452931 DATC_PeEwpRPMReq 5;
BA_ "UserSigValidity" SG_ 2231452931 DATC_PeEwpRPMReq 3;
BA_ "Description" SG_ 2231452931 DATC_PeEwpRPMReq "This signal indicates Cooling For High V Component (for A/C or Heatpump)

ÀüÀå¿ë ³Ã°¢¼ö¿ë, ÀüÀåÆó¿­À» ÀÌ¿ëÇÑ ¸®È÷ÆÃ¿ë";
BA_ "Version" SG_ 2231452931 DATC_AEwpSpdRpmReq "17.11.00";
BA_ "RoutingFactor" SG_ 2231452931 DATC_AEwpSpdRpmReq 5;
BA_ "UserSigValidity" SG_ 2231452931 DATC_AEwpSpdRpmReq 7;
BA_ "Description" SG_ 2231452931 DATC_AEwpSpdRpmReq "This signal indicates Request EWP speed to recover heat in HVAC System.(ENG COOLING ¿ë È¸·Î / È÷ÅÍÄÚ¾î ¿¬°ü)";
BA_ "Version" SG_ 2231452931 DATC_RadFanReq_Duty "20.02.05";
BA_ "RoutingFactor" SG_ 2231452931 DATC_RadFanReq_Duty 5;
BA_ "UserSigValidity" SG_ 2231452931 DATC_RadFanReq_Duty 5;
BA_ "Description" SG_ 2231452931 DATC_RadFanReq_Duty "This signal indicates Request cooling fan speed to cool HVAC System (Duty)

(0xFE value is only used to wake up EMS )";
BA_ "Version" SG_ 2231452931 DATC_OutTempSnsrVal "24.07.06";
BA_ "RoutingFactor" SG_ 2231452931 DATC_OutTempSnsrVal 5;
BA_ "UserSigValidity" SG_ 2231452931 DATC_OutTempSnsrVal 7;
BA_ "GenSigStartValue" SG_ 2231452931 DATC_OutTempSnsrVal 254;
BA_ "Description" SG_ 2231452931 DATC_OutTempSnsrVal "Actual temperature of Ambient Sensor via an A/D converter; converted into degrees

centigrade (¡É).

This is raw data of ambient sensor; just transferred from Ambient Sensor Voltage.";
BA_ "Version" SG_ 2231452931 DATC_DfgSw "17.11.00";
BA_ "RoutingFactor" SG_ 2231452931 DATC_DfgSw 5;
BA_ "UserSigValidity" SG_ 2231452931 DATC_DfgSw 7;
BA_ "Description" SG_ 2231452931 DATC_DfgSw "This signal indicates whether FRONT DEF switch is selected or not.";
BA_ "Version" SG_ 2231452931 DATC_BattChlrVlv_FltCode "18.09.00";
BA_ "RoutingFactor" SG_ 2231452931 DATC_BattChlrVlv_FltCode 5;
BA_ "UserSigValidity" SG_ 2231452931 DATC_BattChlrVlv_FltCode 3;
BA_ "Description" SG_ 2231452931 DATC_BattChlrVlv_FltCode "Battery Chiller Filt Code";
BA_ "Version" SG_ 2231452931 DATC_BattEvapVlvSta "18.09.00";
BA_ "RoutingFactor" SG_ 2231452931 DATC_BattEvapVlvSta 5;
BA_ "UserSigValidity" SG_ 2231452931 DATC_BattEvapVlvSta 5;
BA_ "Description" SG_ 2231452931 DATC_BattEvapVlvSta "BATTERY COOL V/V (EVAP) STATUS";
BA_ "Version" SG_ 2231452931 DATC_BattEvapVlv_FltCode "18.09.00";
BA_ "RoutingFactor" SG_ 2231452931 DATC_BattEvapVlv_FltCode 5;
BA_ "UserSigValidity" SG_ 2231452931 DATC_BattEvapVlv_FltCode 5;
BA_ "Description" SG_ 2231452931 DATC_BattEvapVlv_FltCode "BATTERY COOL V/V (EVAP) FltCode";
BA_ "Version" SG_ 2231452931 DATC_SSC_EngStrtReq "19.04.00";
BA_ "RoutingFactor" SG_ 2231452931 DATC_SSC_EngStrtReq 5;
BA_ "UserSigValidity" SG_ 2231452931 DATC_SSC_EngStrtReq 3;
BA_ "Description" SG_ 2231452931 DATC_SSC_EngStrtReq "Engine start request in SSC state";
BA_ "Version" SG_ 2231452929 DATC_Crc1Val "21.09.03";
BA_ "RoutingFactor" SG_ 2231452929 DATC_Crc1Val 5;
BA_ "UserSigValidity" SG_ 2231452929 DATC_Crc1Val 7;
BA_ "GenSigStartValue" SG_ 2231452929 DATC_Crc1Val 65535;
BA_ "Description" SG_ 2231452929 DATC_Crc1Val "The data area for CRC calculation is based on the data length (DLC) of the message DB.

The CRC shall be calculated over the entire data block (excluding the CRC bytes) including the user data, alive counter and Data ID



- CRC Polynomial (0x1021) , Ini";
BA_ "Version" SG_ 2231452929 DATC_AlvCnt1Val "21.09.03";
BA_ "RoutingFactor" SG_ 2231452929 DATC_AlvCnt1Val 5;
BA_ "UserSigValidity" SG_ 2231452929 DATC_AlvCnt1Val 7;
BA_ "Description" SG_ 2231452929 DATC_AlvCnt1Val "For the first transmission request for a data element the counter shall be initialized with 0 and shall be incremented by 1 for every subsequent send request. 

When the counter reaches the maximum value(0xFF), then it shall restart with 0 for the next s";
BA_ "Version" SG_ 2231452929 DATC_PtcRlySta "17.11.00";
BA_ "RoutingFactor" SG_ 2231452929 DATC_PtcRlySta 5;
BA_ "UserSigValidity" SG_ 2231452929 DATC_PtcRlySta 7;
BA_ "Description" SG_ 2231452929 DATC_PtcRlySta "This signal indicates PTC relay operation condition of gasoline engine. This signal is used for EMS to decide engine RPM up.";
BA_ "Version" SG_ 2231452929 DATC_ManufacturerTyp "17.11.00";
BA_ "RoutingFactor" SG_ 2231452929 DATC_ManufacturerTyp 5;
BA_ "UserSigValidity" SG_ 2231452929 DATC_ManufacturerTyp 3;
BA_ "Description" SG_ 2231452929 DATC_ManufacturerTyp "This signal FATC_ID identifies FATC Maker.";
BA_ "Version" SG_ 2231452929 DATC_AcnCompTyp "17.11.00";
BA_ "RoutingFactor" SG_ 2231452929 DATC_AcnCompTyp 5;
BA_ "UserSigValidity" SG_ 2231452929 DATC_AcnCompTyp 3;
BA_ "Description" SG_ 2231452929 DATC_AcnCompTyp "Heater Control(FATC/MTC) information generated by HVAC Compressor type.";
BA_ "Version" SG_ 2231452929 DATC_Cooldown "18.09.00";
BA_ "RoutingFactor" SG_ 2231452929 DATC_Cooldown 5;
BA_ "UserSigValidity" SG_ 2231452929 DATC_Cooldown 3;
BA_ "Description" SG_ 2231452929 DATC_Cooldown "This signal indicates complete of cooldown.";
BA_ "Version" SG_ 2231452929 DATC_AcnReq "17.11.00";
BA_ "RoutingFactor" SG_ 2231452929 DATC_AcnReq 5;
BA_ "UserSigValidity" SG_ 2231452929 DATC_AcnReq 7;
BA_ "Description" SG_ 2231452929 DATC_AcnReq "This signal indicates A/C request switch by FATC

This signal occurs when A/C switch(button) is selected either manually or automatically.

EMS decides the torque compensation value to avoid torque shortage while A/C on";
BA_ "Version" SG_ 2231452929 DATC_BlwSta "17.11.00";
BA_ "RoutingFactor" SG_ 2231452929 DATC_BlwSta 5;
BA_ "UserSigValidity" SG_ 2231452929 DATC_BlwSta 7;
BA_ "Description" SG_ 2231452929 DATC_BlwSta "This signal indicates HVAC blower motor operation condition.

The signal is used for EMS to decide PTC on or manage battery level.";
BA_ "Version" SG_ 2231452929 DATC_BlwMaxSta "17.11.00";
BA_ "RoutingFactor" SG_ 2231452929 DATC_BlwMaxSta 5;
BA_ "UserSigValidity" SG_ 2231452929 DATC_BlwMaxSta 7;
BA_ "Description" SG_ 2231452929 DATC_BlwMaxSta "This signal indicates that FATC operates HVAC blower by maximum speed.";
BA_ "Version" SG_ 2231452929 DATC_EngStrtReq "17.11.00";
BA_ "RoutingFactor" SG_ 2231452929 DATC_EngStrtReq 5;
BA_ "UserSigValidity" SG_ 2231452929 DATC_EngStrtReq 3;
BA_ "Description" SG_ 2231452929 DATC_EngStrtReq "FATC requests Engine Auto Start to EMS by this signal during idle stop.";
BA_ "Version" SG_ 2231452929 DATC_IsgInhbtReq "17.11.00";
BA_ "RoutingFactor" SG_ 2231452929 DATC_IsgInhbtReq 5;
BA_ "UserSigValidity" SG_ 2231452929 DATC_IsgInhbtReq 3;
BA_ "Description" SG_ 2231452929 DATC_IsgInhbtReq "FATC requests EMS that ISG is prohibited (ISG function is not operating) by this signal.

FATC send the disable signal in the condition, for example HVAC Blower is Max.";
BA_ "Version" SG_ 2231452929 DATC_AcnCompOnReq "17.11.00";
BA_ "RoutingFactor" SG_ 2231452929 DATC_AcnCompOnReq 5;
BA_ "UserSigValidity" SG_ 2231452929 DATC_AcnCompOnReq 3;
BA_ "Description" SG_ 2231452929 DATC_AcnCompOnReq "FATC requests A/C compressor clutch on or off to EMS by this signal

This signal is off to maintain a/c refrigerant flow and air flow smoothly and avoid abnormal a/c compressor torque rising even though A/C request switch on, if the surface temperature o";
BA_ "Version" SG_ 2231452929 DATC_SrvLmpReq "19.08.04";
BA_ "RoutingFactor" SG_ 2231452929 DATC_SrvLmpReq 5;
BA_ "UserSigValidity" SG_ 2231452929 DATC_SrvLmpReq 7;
BA_ "Description" SG_ 2231452929 DATC_SrvLmpReq "This signal indicates request of service Lamp";
BA_ "Version" SG_ 2231452929 DATC_EcvFltSta "17.11.00";
BA_ "RoutingFactor" SG_ 2231452929 DATC_EcvFltSta 5;
BA_ "UserSigValidity" SG_ 2231452929 DATC_EcvFltSta 3;
BA_ "Description" SG_ 2231452929 DATC_EcvFltSta "This signal indicates ECV control fault.

The detailed fault state is in the error identifiers of CR_Fatc_TqAcnOut signal";
BA_ "Version" SG_ 2231452929 DATC_CalcAcnCompTqVal "17.11.00";
BA_ "RoutingFactor" SG_ 2231452929 DATC_CalcAcnCompTqVal 5;
BA_ "UserSigValidity" SG_ 2231452929 DATC_CalcAcnCompTqVal 3;
BA_ "Description" SG_ 2231452929 DATC_CalcAcnCompTqVal "This signal indicates the torque output of A/C compressor calculated by FATC.

EMS decides the torque compensation value or A/C compressor clutch disengagement (off) by receiving of this signal.";
BA_ "Version" SG_ 2231452932 DATC_SSC_InhbtReq "19.04.00";
BA_ "RoutingFactor" SG_ 2231452932 DATC_SSC_InhbtReq 5;
BA_ "UserSigValidity" SG_ 2231452932 DATC_SSC_InhbtReq 3;
BA_ "Description" SG_ 2231452932 DATC_SSC_InhbtReq "Request to EMS not to enter SSC";
BA_ "Version" SG_ 2231452932 DATC_EngIdlRpmUpReq "20.07.12";
BA_ "RoutingFactor" SG_ 2231452932 DATC_EngIdlRpmUpReq 5;
BA_ "UserSigValidity" SG_ 2231452932 DATC_EngIdlRpmUpReq 3;
BA_ "Description" SG_ 2231452932 DATC_EngIdlRpmUpReq "This signal is information of A/C Comp_Load by FATC.";
BA_ "Version" SG_ 2231452932 DATC_MaxBlwVolt "20.05.01";
BA_ "RoutingFactor" SG_ 2231452932 DATC_MaxBlwVolt 5;
BA_ "UserSigValidity" SG_ 2231452932 DATC_MaxBlwVolt 7;
BA_ "Description" SG_ 2231452932 DATC_MaxBlwVolt "Max blower voltage that only B+ status send to LDC";
BA_ "Version" SG_ 2231452932 DATC_MildCooldown "18.10.06";
BA_ "RoutingFactor" SG_ 2231452932 DATC_MildCooldown 5;
BA_ "UserSigValidity" SG_ 2231452932 DATC_MildCooldown 7;
BA_ "Description" SG_ 2231452932 DATC_MildCooldown "Mild Cooldown State";
BA_ "Version" SG_ 2231452932 DATC_BlwrLvl "18.10.06";
BA_ "RoutingFactor" SG_ 2231452932 DATC_BlwrLvl 5;
BA_ "UserSigValidity" SG_ 2231452932 DATC_BlwrLvl 7;
BA_ "Description" SG_ 2231452932 DATC_BlwrLvl "This signal indicates step of Front blower operation .";
BA_ "Version" SG_ 2231452932 DATC_AAFOpenReq "19.06.03";
BA_ "RoutingFactor" SG_ 2231452932 DATC_AAFOpenReq 5;
BA_ "UserSigValidity" SG_ 2231452932 DATC_AAFOpenReq 7;
BA_ "Description" SG_ 2231452932 DATC_AAFOpenReq "Open Reqest Active Air Flap(AAF) before Compressor max rpm";
BA_ "Version" SG_ 2231452932 DATC_BlwSta_Rr "22.11.03";
BA_ "RoutingFactor" SG_ 2231452932 DATC_BlwSta_Rr 5;
BA_ "UserSigValidity" SG_ 2231452932 DATC_BlwSta_Rr 7;
BA_ "Description" SG_ 2231452932 DATC_BlwSta_Rr "This signal indicates HVAC blower motor operation condition for rear seat.";
BA_ "Version" SG_ 2231452932 DATC_BattEwpOpReq "18.12.03";
BA_ "RoutingFactor" SG_ 2231452932 DATC_BattEwpOpReq 5;
BA_ "UserSigValidity" SG_ 2231452932 DATC_BattEwpOpReq 5;
BA_ "Description" SG_ 2231452932 DATC_BattEwpOpReq "This signal requests the operation of BATT EWP for heat recovery technique.";
BA_ "Version" SG_ 2290230530 CLU_RefuelWrnSta "17.11.00";
BA_ "RoutingFactor" SG_ 2290230530 CLU_RefuelWrnSta 2;
BA_ "UserSigValidity" SG_ 2290230530 CLU_RefuelWrnSta 3;
BA_ "Description" SG_ 2290230530 CLU_RefuelWrnSta "This signal indicates that the Refuel popup is the cluster is On or Off.

When Refuel popup is on, its value is 0x1 otherwise its value is 0x0.";
BA_ "Version" SG_ 2290230530 CLU_DrvngModSwSta "25.01.00";
BA_ "RoutingFactor" SG_ 2290230530 CLU_DrvngModSwSta 2;
BA_ "UserSigValidity" SG_ 2290230530 CLU_DrvngModSwSta 3;
BA_ "Description" SG_ 2290230530 CLU_DrvngModSwSta "This signal occurs when drive mode switch is selected either 'Normal' or 'Eco' or 'Sport' or 'Sport+' or 'Smart' or 'Custom' or 'N-mode'.";
BA_ "Version" SG_ 2290230530 CLU_FuelLvlSta "17.12.03";
BA_ "RoutingFactor" SG_ 2290230530 CLU_FuelLvlSta 2;
BA_ "UserSigValidity" SG_ 2290230530 CLU_FuelLvlSta 3;
BA_ "Description" SG_ 2290230530 CLU_FuelLvlSta "The signal is fuel level of the cluster that fuel gauge indicate (Unit: %)";
BA_ "Version" SG_ 2290230530 CLU_SRSWrngLmpSta "22.04.01";
BA_ "RoutingFactor" SG_ 2290230530 CLU_SRSWrngLmpSta 2;
BA_ "UserSigValidity" SG_ 2290230530 CLU_SRSWrngLmpSta 3;
BA_ "GenSigStartValue" SG_ 2290230530 CLU_SRSWrngLmpSta 6;
BA_ "Description" SG_ 2290230530 CLU_SRSWrngLmpSta "This signal is generated by one of the following 5 self-diagnostic result of micro-controller of Cluster.

1) ¡°Lamp ON¡± status as a self-status diagnostic result of cluster

2) ¡°Lamp OFF¡± status as a self-status diagnostic result of cluster

3) ¡°Lam";
BA_ "Version" SG_ 2290230530 CLU_TerrainModSwSta "23.07.02";
BA_ "RoutingFactor" SG_ 2290230530 CLU_TerrainModSwSta 2;
BA_ "UserSigValidity" SG_ 2290230530 CLU_TerrainModSwSta 3;
BA_ "Description" SG_ 2290230530 CLU_TerrainModSwSta "This signal occurs when terrain mode switch is selected either 'Snow' or 'Sand' or 'Mud' or 'Auto', 'Deep Snow', 'Rock'";
BA_ "Version" SG_ 2290230530 CLU_OdoVal "17.11.00";
BA_ "RoutingFactor" SG_ 2290230530 CLU_OdoVal 2;
BA_ "UserSigValidity" SG_ 2290230530 CLU_OdoVal 3;
BA_ "Description" SG_ 2290230530 CLU_OdoVal "This signal indicates mileage counter of a vehicle. Cluster calculates total mileage and sends it to SCC and CUBIS. This value shall be the same with the mileage that is displayed to a driver.";
BA_ "Version" SG_ 2290230529 CLU_Crc2Val "21.09.03";
BA_ "RoutingFactor" SG_ 2290230529 CLU_Crc2Val 2;
BA_ "UserSigValidity" SG_ 2290230529 CLU_Crc2Val 3;
BA_ "GenSigStartValue" SG_ 2290230529 CLU_Crc2Val 65535;
BA_ "Description" SG_ 2290230529 CLU_Crc2Val "The data area for CRC calculation is based on the data length (DLC) of the message DB.

The CRC shall be calculated over the entire data block (excluding the CRC bytes) including the user data, alive counter and Data ID



- CRC Polynomial (0x1021) , Ini";
BA_ "Version" SG_ 2290230529 CLU_AlvCnt2Val "21.09.03";
BA_ "RoutingFactor" SG_ 2290230529 CLU_AlvCnt2Val 2;
BA_ "UserSigValidity" SG_ 2290230529 CLU_AlvCnt2Val 3;
BA_ "Description" SG_ 2290230529 CLU_AlvCnt2Val "For the first transmission request for a data element the counter shall be initialized with 0 and shall be incremented by 1 for every subsequent send request. 

When the counter reaches the maximum value(0xFF), then it shall restart with 0 for the next s";
BA_ "Version" SG_ 2290230529 CLU_DTEVal "19.02.07";
BA_ "RoutingFactor" SG_ 2290230529 CLU_DTEVal 2;
BA_ "UserSigValidity" SG_ 2290230529 CLU_DTEVal 3;
BA_ "Description" SG_ 2290230529 CLU_DTEVal "This signal indicates DTE.

0x0: Valid DTE 0 (Display '---')

0x1~0xFFE: Valid DTE (1 ~ 4094 km)

(DTE >4094 km : 0xFFE)

0xFFF : Invalid(Display '---' Blink)";
BA_ "Version" SG_ 2290230529 CLU_TripUnitSta "17.11.00";
BA_ "RoutingFactor" SG_ 2290230529 CLU_TripUnitSta 2;
BA_ "UserSigValidity" SG_ 2290230529 CLU_TripUnitSta 3;
BA_ "Description" SG_ 2290230529 CLU_TripUnitSta "This signal indicates Distance to Empty UNIT";
BA_ "Version" SG_ 2290230529 CLU_LoFuelWrngSta "17.11.00";
BA_ "RoutingFactor" SG_ 2290230529 CLU_LoFuelWrngSta 2;
BA_ "UserSigValidity" SG_ 2290230529 CLU_LoFuelWrngSta 3;
BA_ "Description" SG_ 2290230529 CLU_LoFuelWrngSta "This signal indicates that the Low fuel warning in the cluster is On or Off. When Low Fuel Warning is On, its value is 01H otherwise its value is 00H.";
BA_ "Version" SG_ 2290230529 CLU_RefuelDetSta "17.11.00";
BA_ "RoutingFactor" SG_ 2290230529 CLU_RefuelDetSta 2;
BA_ "UserSigValidity" SG_ 2290230529 CLU_RefuelDetSta 3;
BA_ "Description" SG_ 2290230529 CLU_RefuelDetSta "This signal sends the refuel detected status to the tele-matics control unit. 

It transfers 3 times during refuel detected event why if valid one is missing, valid signals are used for extra signal.";
BA_ "Version" SG_ 2290230529 CLU_TerrainMainSwSta "18.04.00";
BA_ "RoutingFactor" SG_ 2290230529 CLU_TerrainMainSwSta 2;
BA_ "UserSigValidity" SG_ 2290230529 CLU_TerrainMainSwSta 3;
BA_ "Description" SG_ 2290230529 CLU_TerrainMainSwSta "This signal represents the terrain mode main switch's state.

0x1:On-Road /0x2:Off-Road";
BA_ "Version" SG_ 2315421697 CCU_AP_OTA_Crc1Val "21.09.03";
BA_ "UserSigValidity" SG_ 2315421697 CCU_AP_OTA_Crc1Val 3;
BA_ "GenSigStartValue" SG_ 2315421697 CCU_AP_OTA_Crc1Val 65535;
BA_ "GenSigSendType" SG_ 2315421697 CCU_AP_OTA_Crc1Val 4;
BA_ "Description" SG_ 2315421697 CCU_AP_OTA_Crc1Val "The data area for CRC calculation is based on the data length (DLC) of the message DB.

The CRC shall be calculated over the entire data block (excluding the CRC bytes) including the user data, alive counter and Data ID



- CRC Polynomial (0x1021) , Ini";
BA_ "Version" SG_ 2315421697 CCU_AP_OTA_AlvCnt1Val "21.09.03";
BA_ "UserSigValidity" SG_ 2315421697 CCU_AP_OTA_AlvCnt1Val 3;
BA_ "GenSigSendType" SG_ 2315421697 CCU_AP_OTA_AlvCnt1Val 4;
BA_ "Description" SG_ 2315421697 CCU_AP_OTA_AlvCnt1Val "For the first transmission request for a data element the counter shall be initialized with 0 and shall be incremented by 1 for every subsequent send request. 

When the counter reaches the maximum value(0xFF), then it shall restart with 0 for the next s";
BA_ "Version" SG_ 2315421697 CCU_OTA_mode "20.01.01";
BA_ "UserSigValidity" SG_ 2315421697 CCU_OTA_mode 0;
BA_ "GenSigSendType" SG_ 2315421697 CCU_OTA_mode 4;
BA_ "Version" SG_ 2315421697 CCU_OTA_IG3On_request "20.01.02";
BA_ "UserSigValidity" SG_ 2315421697 CCU_OTA_IG3On_request 0;
BA_ "GenSigSendType" SG_ 2315421697 CCU_OTA_IG3On_request 4;
BA_ "Version" SG_ 2315421697 OTA_Cond_Vehicle_Pwr "20.11.03";
BA_ "UserSigValidity" SG_ 2315421697 OTA_Cond_Vehicle_Pwr 0;
BA_ "GenSigStartValue" SG_ 2315421697 OTA_Cond_Vehicle_Pwr 1;
BA_ "GenSigSendType" SG_ 2315421697 OTA_Cond_Vehicle_Pwr 4;
BA_ "Version" SG_ 2315421697 OTA_Cond_Gear_P "20.11.03";
BA_ "UserSigValidity" SG_ 2315421697 OTA_Cond_Gear_P 0;
BA_ "GenSigStartValue" SG_ 2315421697 OTA_Cond_Gear_P 1;
BA_ "GenSigSendType" SG_ 2315421697 OTA_Cond_Gear_P 4;
BA_ "Version" SG_ 2315421697 OTA_Cond_Parking_Brk "20.11.03";
BA_ "UserSigValidity" SG_ 2315421697 OTA_Cond_Parking_Brk 0;
BA_ "GenSigStartValue" SG_ 2315421697 OTA_Cond_Parking_Brk 1;
BA_ "GenSigSendType" SG_ 2315421697 OTA_Cond_Parking_Brk 4;
BA_ "Version" SG_ 2315421697 OTA_Cond_Ext_Lamp "20.11.03";
BA_ "UserSigValidity" SG_ 2315421697 OTA_Cond_Ext_Lamp 0;
BA_ "GenSigStartValue" SG_ 2315421697 OTA_Cond_Ext_Lamp 1;
BA_ "GenSigSendType" SG_ 2315421697 OTA_Cond_Ext_Lamp 4;
BA_ "Version" SG_ 2315421697 OTA_Cond_Hood_Closed "20.11.03";
BA_ "UserSigValidity" SG_ 2315421697 OTA_Cond_Hood_Closed 0;
BA_ "GenSigStartValue" SG_ 2315421697 OTA_Cond_Hood_Closed 1;
BA_ "GenSigSendType" SG_ 2315421697 OTA_Cond_Hood_Closed 4;
BA_ "Version" SG_ 2315421697 CCU_OTA_Cond_Request "22.08.01";
BA_ "UserSigValidity" SG_ 2315421697 CCU_OTA_Cond_Request 0;
BA_ "GenSigSendType" SG_ 2315421697 CCU_OTA_Cond_Request 4;
BA_ "Description" SG_ 2315421697 CCU_OTA_Cond_Request "Request for OTA Condition (to EPB, extLamp)";
BA_ "Version" SG_ 2315421697 CCU_OTA_Tele_Cranking "22.02.02";
BA_ "NetworkRequestHoldingTime" SG_ 2315421697 CCU_OTA_Tele_Cranking 2000;
BA_ "NetworkRequest" SG_ 2315421697 CCU_OTA_Tele_Cranking 0;
BA_ "UserSigValidity" SG_ 2315421697 CCU_OTA_Tele_Cranking 0;
BA_ "GenSigSendType" SG_ 2315421697 CCU_OTA_Tele_Cranking 4;
BA_ "Version" SG_ 2315421697 OTA_UI_Ready_request "21.04.00";
BA_ "UserSigValidity" SG_ 2315421697 OTA_UI_Ready_request 0;
BA_ "GenSigSendType" SG_ 2315421697 OTA_UI_Ready_request 4;
BA_ "Description" SG_ 2315421697 OTA_UI_Ready_request "OTA User Approval Popup Request Signal (to ccIC)";
BA_ "Version" SG_ 2315421697 OTA_Result "21.02.02";
BA_ "UserSigValidity" SG_ 2315421697 OTA_Result 0;
BA_ "GenSigSendType" SG_ 2315421697 OTA_Result 4;
BA_ "Version" SG_ 2315421697 CF_AVN_InterAutoLockMode_Set2_Co "20.09.00";
BA_ "UserSigValidity" SG_ 2315421697 CF_AVN_InterAutoLockMode_Set2_Co 3;
BA_ "GenSigSendType" SG_ 2315421697 CF_AVN_InterAutoLockMode_Set2_Co 4;
BA_ "SystemSignalLongSymbol" SG_ 2315421697 CF_AVN_InterAutoLockMode_Set2_Co "CF_AVN_InterAutoLockMode_Set2_Copy_1";
BA_ "Version" SG_ 2315421697 CCU_OTA_EOU "20.09.00";
BA_ "UserSigValidity" SG_ 2315421697 CCU_OTA_EOU 0;
BA_ "GenSigSendType" SG_ 2315421697 CCU_OTA_EOU 4;
BA_ "Version" SG_ 2470763009 CLU_Crc9Val "21.09.03";
BA_ "UserSigValidity" SG_ 2470763009 CLU_Crc9Val 3;
BA_ "GenSigStartValue" SG_ 2470763009 CLU_Crc9Val 65535;
BA_ "GenSigSendType" SG_ 2470763009 CLU_Crc9Val 4;
BA_ "Description" SG_ 2470763009 CLU_Crc9Val "The data area for CRC calculation is based on the data length (DLC) of the message DB.

The CRC shall be calculated over the entire data block (excluding the CRC bytes) including the user data, alive counter and Data ID



- CRC Polynomial (0x1021) , Ini";
BA_ "Version" SG_ 2470763009 CLU_AlvCnt9Val "21.09.03";
BA_ "UserSigValidity" SG_ 2470763009 CLU_AlvCnt9Val 3;
BA_ "GenSigSendType" SG_ 2470763009 CLU_AlvCnt9Val 4;
BA_ "Description" SG_ 2470763009 CLU_AlvCnt9Val "For the first transmission request for a data element the counter shall be initialized with 0 and shall be incremented by 1 for every subsequent send request. 

When the counter reaches the maximum value(0xFF), then it shall restart with 0 for the next s";
BA_ "Version" SG_ 2470763009 USM_MdLmpClrSetReq "20.08.06";
BA_ "UserSigValidity" SG_ 2470763009 USM_MdLmpClrSetReq 3;
BA_ "GenSigSendType" SG_ 2470763009 USM_MdLmpClrSetReq 4;
BA_ "Description" SG_ 2470763009 USM_MdLmpClrSetReq "Request set the Mood Lamp Color";
BA_ "Version" SG_ 2470763009 USM_RrWiperRevSetReq "17.11.00";
BA_ "UserSigValidity" SG_ 2470763009 USM_RrWiperRevSetReq 3;
BA_ "GenSigSendType" SG_ 2470763009 USM_RrWiperRevSetReq 4;
BA_ "Description" SG_ 2470763009 USM_RrWiperRevSetReq "Request to set RearWiper Reverse Mode";
BA_ "Version" SG_ 2470763009 USM_RrStRemindSetReq "19.01.04";
BA_ "UserSigValidity" SG_ 2470763009 USM_RrStRemindSetReq 3;
BA_ "GenSigSendType" SG_ 2470763009 USM_RrStRemindSetReq 4;
BA_ "Description" SG_ 2470763009 USM_RrStRemindSetReq "USM Function for RearSeatReminder on/off SW";
BA_ "Version" SG_ 2470763009 USM_RrWpcSetReq "17.11.00";
BA_ "UserSigValidity" SG_ 2470763009 USM_RrWpcSetReq 3;
BA_ "GenSigSendType" SG_ 2470763009 USM_RrWpcSetReq 4;
BA_ "Description" SG_ 2470763009 USM_RrWpcSetReq "USM Function for REAR WPC(Wireless Phone Chager) on/off SW";
BA_ "Version" SG_ 2470763009 USM_WpcSetReq "17.11.00";
BA_ "UserSigValidity" SG_ 2470763009 USM_WpcSetReq 3;
BA_ "GenSigSendType" SG_ 2470763009 USM_WpcSetReq 4;
BA_ "Description" SG_ 2470763009 USM_WpcSetReq "USM Function for WPC(Wireless Phone Chager) on/off SW";
BA_ "Version" SG_ 2470763009 USM_SeqLmpSetReq "17.11.00";
BA_ "UserSigValidity" SG_ 2470763009 USM_SeqLmpSetReq 3;
BA_ "GenSigSendType" SG_ 2470763009 USM_SeqLmpSetReq 4;
BA_ "Description" SG_ 2470763009 USM_SeqLmpSetReq "This signal is used for a request to set the value of USM Menus. This signal requests to change status of SequencialLamp ON/OFF setting.





When this signal change, the message (CLU18) is sent 3 times.";
BA_ "Version" SG_ 2470763009 USM_UnlckWlcmSetReq "17.11.00";
BA_ "UserSigValidity" SG_ 2470763009 USM_UnlckWlcmSetReq 3;
BA_ "GenSigSendType" SG_ 2470763009 USM_UnlckWlcmSetReq 4;
BA_ "Description" SG_ 2470763009 USM_UnlckWlcmSetReq "This signal is used for a request to set the value of USM Menus. This signal requests to change status of Welcome System setting.





When this signal change, the message (CLU18) is sent 3 times.";
BA_ "Version" SG_ 2470763009 USM_SmrtWlcmSetReq "17.11.00";
BA_ "UserSigValidity" SG_ 2470763009 USM_SmrtWlcmSetReq 3;
BA_ "GenSigSendType" SG_ 2470763009 USM_SmrtWlcmSetReq 4;
BA_ "Description" SG_ 2470763009 USM_SmrtWlcmSetReq "This signal is used for a request to set the value of USM Menus. This signal requests to change status of Welcome System setting.





When this signal change, the message (CLU18) is sent 3 times.";
BA_ "Version" SG_ 2470763009 USM_UipSetReq "18.11.07";
BA_ "UserSigValidity" SG_ 2470763009 USM_UipSetReq 3;
BA_ "GenSigSendType" SG_ 2470763009 USM_UipSetReq 4;
BA_ "Description" SG_ 2470763009 USM_UipSetReq "Request to set Uip(Ultrasonic Intrusion Protection)

This signal is used for a request to set the value of USM Menus. 

When this signal change, the message is sent 3 times.";
BA_ "Version" SG_ 2470763009 USM_DigitalKeyEnblSetReq "18.11.00";
BA_ "UserSigValidity" SG_ 2470763009 USM_DigitalKeyEnblSetReq 3;
BA_ "GenSigSendType" SG_ 2470763009 USM_DigitalKeyEnblSetReq 4;
BA_ "Description" SG_ 2470763009 USM_DigitalKeyEnblSetReq "This signal is used for a request to set the value of USM Menus. This signal requests to set Digital Key On/Off.";
BA_ "Version" SG_ 2470763009 USM_OwnerPhnRegSetReq "18.11.00";
BA_ "UserSigValidity" SG_ 2470763009 USM_OwnerPhnRegSetReq 3;
BA_ "GenSigSendType" SG_ 2470763009 USM_OwnerPhnRegSetReq 4;
BA_ "Description" SG_ 2470763009 USM_OwnerPhnRegSetReq "This signal is used for a request to set the value of USM Menus.

This signal requests to set Digital Key On/Off";
BA_ "Version" SG_ 2470763009 USM_NFCCard1RegSetReq "18.11.00";
BA_ "UserSigValidity" SG_ 2470763009 USM_NFCCard1RegSetReq 3;
BA_ "GenSigSendType" SG_ 2470763009 USM_NFCCard1RegSetReq 4;
BA_ "Description" SG_ 2470763009 USM_NFCCard1RegSetReq "This signal is used for a request to set the value of USM Menus. This signal requests to go through the process for NFC Card 1 recoding.";
BA_ "Version" SG_ 2470763009 USM_NFCCard2RegSetReq "18.11.00";
BA_ "UserSigValidity" SG_ 2470763009 USM_NFCCard2RegSetReq 3;
BA_ "GenSigSendType" SG_ 2470763009 USM_NFCCard2RegSetReq 4;
BA_ "Description" SG_ 2470763009 USM_NFCCard2RegSetReq "This signal is used for arequest to set the value of usm menus.

This signal requests to go through the process NFC Card 2 recording";
BA_ "Version" SG_ 2470763009 USM_ProcStpReq "18.11.00";
BA_ "UserSigValidity" SG_ 2470763009 USM_ProcStpReq 3;
BA_ "GenSigSendType" SG_ 2470763009 USM_ProcStpReq 4;
BA_ "Description" SG_ 2470763009 USM_ProcStpReq "This signal is used for a request to escape the IAU Authorizaton processing";
BA_ "Version" SG_ 2470763009 USM_PwrAutoOffTimeSetReq "18.12.02";
BA_ "UserSigValidity" SG_ 2470763009 USM_PwrAutoOffTimeSetReq 3;
BA_ "GenSigSendType" SG_ 2470763009 USM_PwrAutoOffTimeSetReq 4;
BA_ "Description" SG_ 2470763009 USM_PwrAutoOffTimeSetReq "This signal is used for a request to set the value of USM Menus. This signal requests to change status of Power auto off time setting.";
BA_ "Version" SG_ 2470763009 USM_RrStRemindSetReq_RestMode "19.09.04";
BA_ "UserSigValidity" SG_ 2470763009 USM_RrStRemindSetReq_RestMode 3;
BA_ "GenSigSendType" SG_ 2470763009 USM_RrStRemindSetReq_RestMode 4;
BA_ "Description" SG_ 2470763009 USM_RrStRemindSetReq_RestMode "This is a signal for Rear Seat remind USM 

Request to set  Restmod of Rear Seat remind";
BA_ "Version" SG_ 2470763009 USM_1stRrStRemindSetReq "20.02.06";
BA_ "UserSigValidity" SG_ 2470763009 USM_1stRrStRemindSetReq 3;
BA_ "GenSigSendType" SG_ 2470763009 USM_1stRrStRemindSetReq 4;
BA_ "Description" SG_ 2470763009 USM_1stRrStRemindSetReq "USM Function for RearSeatReminder on/off SW for IBU only Type";
BA_ "Version" SG_ 2470763009 USM_Wpc2SetReq "22.02.06";
BA_ "UserSigValidity" SG_ 2470763009 USM_Wpc2SetReq 3;
BA_ "GenSigSendType" SG_ 2470763009 USM_Wpc2SetReq 4;
BA_ "Description" SG_ 2470763009 USM_Wpc2SetReq "USM Function for WPC(Wireless Phone Chager) on/off SW";
BA_ "Version" SG_ 742 SGU_OptTyp "21.06.12";
BA_ "RoutingFactor" SG_ 742 SGU_OptTyp 0;
BA_ "UserSigValidity" SG_ 742 SGU_OptTyp 0;
BA_ "GenSigSendType" SG_ 742 SGU_OptTyp 4;
BA_ "Description" SG_ 742 SGU_OptTyp "This signal indicates if smart glass is installed and whta kind of smart glass is.

bit0 : Smart Glass Installation

bit1 : Smart Roof Glass

bit2 : Rear Smart Door Glass

bit3~bit7 : Reserved";
BA_ "Version" SG_ 742 SGU_FltSta "21.07.04";
BA_ "RoutingFactor" SG_ 742 SGU_FltSta 0;
BA_ "UserSigValidity" SG_ 742 SGU_FltSta 0;
BA_ "GenSigSendType" SG_ 742 SGU_FltSta 4;
BA_ "Description" SG_ 742 SGU_FltSta "SGU Fault Status";
BA_ "Version" SG_ 742 SGU_BlindOnOffSet "21.07.05";
BA_ "RoutingFactor" SG_ 742 SGU_BlindOnOffSet 0;
BA_ "UserSigValidity" SG_ 742 SGU_BlindOnOffSet 0;
BA_ "GenSigSendType" SG_ 742 SGU_BlindOnOffSet 4;
BA_ "Description" SG_ 742 SGU_BlindOnOffSet "Roll Blind Open/Close Control Set Value";
BA_ "Version" SG_ 742 SGU_BlindOpenReq "21.09.05";
BA_ "RoutingFactor" SG_ 742 SGU_BlindOpenReq 0;
BA_ "UserSigValidity" SG_ 742 SGU_BlindOpenReq 0;
BA_ "GenSigSendType" SG_ 742 SGU_BlindOpenReq 4;
BA_ "Description" SG_ 742 SGU_BlindOpenReq "This signal is for controlling a blind when SGU controls transparency of smart glass.";
BA_ "Version" SG_ 742 SGU_FltVal "21.07.04";
BA_ "RoutingFactor" SG_ 742 SGU_FltVal 0;
BA_ "UserSigValidity" SG_ 742 SGU_FltVal 0;
BA_ "GenSigSendType" SG_ 742 SGU_FltVal 4;
BA_ "Description" SG_ 742 SGU_FltVal "SGU Fault Value";
BA_ "Version" SG_ 742 SGU_Roof_OprLv "21.09.00";
BA_ "RoutingFactor" SG_ 742 SGU_Roof_OprLv 0;
BA_ "UserSigValidity" SG_ 742 SGU_Roof_OprLv 0;
BA_ "GenSigSendType" SG_ 742 SGU_Roof_OprLv 4;
BA_ "Description" SG_ 742 SGU_Roof_OprLv "Roof Smart Glass Operation Level";
BA_ "Version" SG_ 742 SGU_2ndLeftDoor_OprLv "21.09.00";
BA_ "RoutingFactor" SG_ 742 SGU_2ndLeftDoor_OprLv 0;
BA_ "UserSigValidity" SG_ 742 SGU_2ndLeftDoor_OprLv 0;
BA_ "GenSigSendType" SG_ 742 SGU_2ndLeftDoor_OprLv 4;
BA_ "Description" SG_ 742 SGU_2ndLeftDoor_OprLv "2nd Row Left Door Smart Glass Operation Level";
BA_ "Version" SG_ 742 SGU_2ndRightDoor_OprLv "21.09.00";
BA_ "RoutingFactor" SG_ 742 SGU_2ndRightDoor_OprLv 0;
BA_ "UserSigValidity" SG_ 742 SGU_2ndRightDoor_OprLv 0;
BA_ "GenSigSendType" SG_ 742 SGU_2ndRightDoor_OprLv 4;
BA_ "Description" SG_ 742 SGU_2ndRightDoor_OprLv "2nd Row Right Door Smart Glass Operation Level";
BA_ "Version" SG_ 742 SGU_3rdLeftDoor_OprLv "21.09.00";
BA_ "RoutingFactor" SG_ 742 SGU_3rdLeftDoor_OprLv 0;
BA_ "UserSigValidity" SG_ 742 SGU_3rdLeftDoor_OprLv 0;
BA_ "GenSigSendType" SG_ 742 SGU_3rdLeftDoor_OprLv 4;
BA_ "Description" SG_ 742 SGU_3rdLeftDoor_OprLv "3rd Row Left Door Smart Glass Operation Level";
BA_ "Version" SG_ 742 SGU_3rdRightDoor_OprLv "21.09.00";
BA_ "RoutingFactor" SG_ 742 SGU_3rdRightDoor_OprLv 0;
BA_ "UserSigValidity" SG_ 742 SGU_3rdRightDoor_OprLv 0;
BA_ "GenSigSendType" SG_ 742 SGU_3rdRightDoor_OprLv 4;
BA_ "Description" SG_ 742 SGU_3rdRightDoor_OprLv "3rd Row Right Door Smart Glass Operation Level";
BA_ "Version" SG_ 742 SGU_RearWindow_OprLv "21.09.00";
BA_ "RoutingFactor" SG_ 742 SGU_RearWindow_OprLv 0;
BA_ "UserSigValidity" SG_ 742 SGU_RearWindow_OprLv 0;
BA_ "GenSigSendType" SG_ 742 SGU_RearWindow_OprLv 4;
BA_ "Description" SG_ 742 SGU_RearWindow_OprLv "Rear Window Smart Glass Operation Level";
BA_ "Version" SG_ 742 SGU_OprLvVehicleSet "21.11.05";
BA_ "RoutingFactor" SG_ 742 SGU_OprLvVehicleSet 0;
BA_ "UserSigValidity" SG_ 742 SGU_OprLvVehicleSet 0;
BA_ "GenSigSendType" SG_ 742 SGU_OprLvVehicleSet 4;
BA_ "Description" SG_ 742 SGU_OprLvVehicleSet "Smart Glass Maximum Operation Level Setting Value for each vechicles";
BA_ "Version" SG_ 742 SGU_CH1_VoltageVal "22.05.03";
BA_ "RoutingFactor" SG_ 742 SGU_CH1_VoltageVal 0;
BA_ "UserSigValidity" SG_ 742 SGU_CH1_VoltageVal 0;
BA_ "GenSigSendType" SG_ 742 SGU_CH1_VoltageVal 4;
BA_ "Description" SG_ 742 SGU_CH1_VoltageVal "SGU Channel 1 AC Voltage Value

0x0~0x3B:Valid Range  (AC Voltage Value 0.0 ~ 6.0V)

0x0~0x40:Not Used";
BA_ "Version" SG_ 742 SGU_CH2_VoltageVal "22.05.03";
BA_ "RoutingFactor" SG_ 742 SGU_CH2_VoltageVal 0;
BA_ "UserSigValidity" SG_ 742 SGU_CH2_VoltageVal 0;
BA_ "GenSigSendType" SG_ 742 SGU_CH2_VoltageVal 4;
BA_ "Description" SG_ 742 SGU_CH2_VoltageVal "SGU Channel 2 AC Voltage Value

0x0~0x3B:Valid Range  (AC Voltage Value 0.0 ~ 6.0V)

0x0~0x40:Not Used";
BA_ "Version" SG_ 742 SGU_RdySta "21.07.04";
BA_ "RoutingFactor" SG_ 742 SGU_RdySta 0;
BA_ "UserSigValidity" SG_ 742 SGU_RdySta 0;
BA_ "GenSigSendType" SG_ 742 SGU_RdySta 4;
BA_ "Description" SG_ 742 SGU_RdySta "SGU Ready Status";
BA_ "Version" SG_ 763 SBCM_DRV_Crc3Val "22.05.03";
BA_ "UserSigValidity" SG_ 763 SBCM_DRV_Crc3Val 0;
BA_ "GenSigSendType" SG_ 763 SBCM_DRV_Crc3Val 4;
BA_ "Description" SG_ 763 SBCM_DRV_Crc3Val "The data area for CRC calculation is based on the data length (DLC) of the message DB.

The CRC shall be calculated over the entire data block (excluding the CRC bytes) including the user data, alive counter and Data ID 

 

- CRC Polynomial (0x1D) , Ini";
BA_ "Version" SG_ 763 CDM_TypeOption "23.04.02";
BA_ "NetworkRequestHoldingTime" SG_ 763 CDM_TypeOption 5000;
BA_ "NetworkRequest" SG_ 763 CDM_TypeOption 0;
BA_ "UserSigValidity" SG_ 763 CDM_TypeOption 0;
BA_ "GenSigSendType" SG_ 763 CDM_TypeOption 4;
BA_ "Description" SG_ 763 CDM_TypeOption "0x1 : On (CDM is applied)

0x2 : On_2EA (CDM 2EA are applied)";
BA_ "Version" SG_ 763 SBCM_DRV_AlvCnt3Val "22.05.03";
BA_ "UserSigValidity" SG_ 763 SBCM_DRV_AlvCnt3Val 0;
BA_ "GenSigSendType" SG_ 763 SBCM_DRV_AlvCnt3Val 4;
BA_ "Description" SG_ 763 SBCM_DRV_AlvCnt3Val "For the first transmission request for a data element the counter shall be initialized with 0 and shall be incremented by 1

for every subsequent send request. When the counter reaches the maximum value(0xE), then it shall restart with 0 for the next sen";
BA_ "Version" SG_ 763 CDM_ImmeChgSw_SBCM "21.07.07";
BA_ "UserSigValidity" SG_ 763 CDM_ImmeChgSw_SBCM 7;
BA_ "GenSigSendType" SG_ 763 CDM_ImmeChgSw_SBCM 4;
BA_ "Description" SG_ 763 CDM_ImmeChgSw_SBCM "State of Immediate Charging Switch";
BA_ "Version" SG_ 763 CDM_FobSrchReq_DRV "24.04.10";
BA_ "NetworkRequestHoldingTime" SG_ 763 CDM_FobSrchReq_DRV 5000;
BA_ "NetworkRequest" SG_ 763 CDM_FobSrchReq_DRV 0;
BA_ "UserSigValidity" SG_ 763 CDM_FobSrchReq_DRV 7;
BA_ "GenSigSendType" SG_ 763 CDM_FobSrchReq_DRV 4;
BA_ "Version" SG_ 763 CDM_OpnClsState_SBCM "21.07.07";
BA_ "UserSigValidity" SG_ 763 CDM_OpnClsState_SBCM 7;
BA_ "GenSigSendType" SG_ 763 CDM_OpnClsState_SBCM 4;
BA_ "Description" SG_ 763 CDM_OpnClsState_SBCM "This signal indicates CDM Open/Close Status";
BA_ "Version" SG_ 763 CDM_WarnMsg_SBCM "21.07.07";
BA_ "UserSigValidity" SG_ 763 CDM_WarnMsg_SBCM 7;
BA_ "GenSigSendType" SG_ 763 CDM_WarnMsg_SBCM 4;
BA_ "Description" SG_ 763 CDM_WarnMsg_SBCM "Command for CDM Warning on cluster";
BA_ "Version" SG_ 763 CDM_AutoWashModeSta "22.02.00";
BA_ "NetworkRequestHoldingTime" SG_ 763 CDM_AutoWashModeSta 5000;
BA_ "NetworkRequest" SG_ 763 CDM_AutoWashModeSta 0;
BA_ "UserSigValidity" SG_ 763 CDM_AutoWashModeSta 0;
BA_ "GenSigSendType" SG_ 763 CDM_AutoWashModeSta 4;
BA_ "Version" SG_ 763 CDM_CmdStatus_SBCM "22.08.03";
BA_ "UserSigValidity" SG_ 763 CDM_CmdStatus_SBCM 7;
BA_ "GenSigStartValue" SG_ 763 CDM_CmdStatus_SBCM 15;
BA_ "GenSigSendType" SG_ 763 CDM_CmdStatus_SBCM 4;
BA_ "Description" SG_ 763 CDM_CmdStatus_SBCM "User Condition Check For CDM Operation";
BA_ "Version" SG_ 763 CDM_OutsideOpnSwSta "23.02.02";
BA_ "NetworkRequestHoldingTime" SG_ 763 CDM_OutsideOpnSwSta 5000;
BA_ "NetworkRequest" SG_ 763 CDM_OutsideOpnSwSta 0;
BA_ "UserSigValidity" SG_ 763 CDM_OutsideOpnSwSta 7;
BA_ "GenSigSendType" SG_ 763 CDM_OutsideOpnSwSta 4;
BA_ "Description" SG_ 763 CDM_OutsideOpnSwSta "Charing Dorr O/S SW State";
BA_ "Version" SG_ 763 PwrDRBuzzerOut_DRV "21.07.07";
BA_ "NetworkRequestHoldingTime" SG_ 763 PwrDRBuzzerOut_DRV 5000;
BA_ "NetworkRequest" SG_ 763 PwrDRBuzzerOut_DRV 0;
BA_ "UserSigValidity" SG_ 763 PwrDRBuzzerOut_DRV 0;
BA_ "GenSigSendType" SG_ 763 PwrDRBuzzerOut_DRV 4;
BA_ "Version" SG_ 763 Warn_HoodSwSta_SBCM "21.09.08";
BA_ "NetworkRequestHoldingTime" SG_ 763 Warn_HoodSwSta_SBCM 5000;
BA_ "NetworkRequest" SG_ 763 Warn_HoodSwSta_SBCM 0;
BA_ "UserSigValidity" SG_ 763 Warn_HoodSwSta_SBCM 0;
BA_ "GenSigSendType" SG_ 763 Warn_HoodSwSta_SBCM 4;
BA_ "Version" SG_ 763 Hood_TypeOption "22.03.01";
BA_ "NetworkRequestHoldingTime" SG_ 763 Hood_TypeOption 5000;
BA_ "NetworkRequest" SG_ 763 Hood_TypeOption 0;
BA_ "UserSigValidity" SG_ 763 Hood_TypeOption 0;
BA_ "GenSigSendType" SG_ 763 Hood_TypeOption 4;
BA_ "Description" SG_ 763 Hood_TypeOption "If the E-Hood is applied, the signal will be send.";
BA_ "Version" SG_ 763 SBCM_FrunkSta "22.01.06";
BA_ "NetworkRequestHoldingTime" SG_ 763 SBCM_FrunkSta 5000;
BA_ "NetworkRequest" SG_ 763 SBCM_FrunkSta 0;
BA_ "UserSigValidity" SG_ 763 SBCM_FrunkSta 0;
BA_ "GenSigSendType" SG_ 763 SBCM_FrunkSta 4;
BA_ "Version" SG_ 763 Warn_HoodSwFullSta_SBCM "22.01.06";
BA_ "NetworkRequestHoldingTime" SG_ 763 Warn_HoodSwFullSta_SBCM 5000;
BA_ "NetworkRequest" SG_ 763 Warn_HoodSwFullSta_SBCM 0;
BA_ "UserSigValidity" SG_ 763 Warn_HoodSwFullSta_SBCM 0;
BA_ "GenSigSendType" SG_ 763 Warn_HoodSwFullSta_SBCM 4;
BA_ "Version" SG_ 763 FrunkWarning_SBCM "22.03.01";
BA_ "NetworkRequestHoldingTime" SG_ 763 FrunkWarning_SBCM 5000;
BA_ "NetworkRequest" SG_ 763 FrunkWarning_SBCM 0;
BA_ "UserSigValidity" SG_ 763 FrunkWarning_SBCM 0;
BA_ "GenSigSendType" SG_ 763 FrunkWarning_SBCM 4;
BA_ "Version" SG_ 763 SBCM_Longkey_DRVDrAtClsSwSta "22.04.02";
BA_ "NetworkRequestHoldingTime" SG_ 763 SBCM_Longkey_DRVDrAtClsSwSta 5000;
BA_ "NetworkRequest" SG_ 763 SBCM_Longkey_DRVDrAtClsSwSta 0;
BA_ "UserSigValidity" SG_ 763 SBCM_Longkey_DRVDrAtClsSwSta 0;
BA_ "GenSigSendType" SG_ 763 SBCM_Longkey_DRVDrAtClsSwSta 4;
BA_ "Description" SG_ 763 SBCM_Longkey_DRVDrAtClsSwSta "FCS Power Door Long key Status";
BA_ "Version" SG_ 763 PwrDRClosingDRVDrSta "22.04.01";
BA_ "NetworkRequestHoldingTime" SG_ 763 PwrDRClosingDRVDrSta 5000;
BA_ "NetworkRequest" SG_ 763 PwrDRClosingDRVDrSta 0;
BA_ "UserSigValidity" SG_ 763 PwrDRClosingDRVDrSta 0;
BA_ "GenSigSendType" SG_ 763 PwrDRClosingDRVDrSta 4;
BA_ "Version" SG_ 763 Drv_DrLkRetryFail_SBCM "23.03.00";
BA_ "NetworkRequestHoldingTime" SG_ 763 Drv_DrLkRetryFail_SBCM 5000;
BA_ "NetworkRequest" SG_ 763 Drv_DrLkRetryFail_SBCM 0;
BA_ "UserSigValidity" SG_ 763 Drv_DrLkRetryFail_SBCM 0;
BA_ "TimeoutValue" SG_ 763 Drv_DrLkRetryFail_SBCM "0x0";
BA_ "GenSigSendType" SG_ 763 Drv_DrLkRetryFail_SBCM 4;
BA_ "Version" SG_ 763 CDM_GbtImmeChgSw_SBCM "23.04.02";
BA_ "UserSigValidity" SG_ 763 CDM_GbtImmeChgSw_SBCM 0;
BA_ "GenSigSendType" SG_ 763 CDM_GbtImmeChgSw_SBCM 4;
BA_ "Description" SG_ 763 CDM_GbtImmeChgSw_SBCM "State of Immediate Charging Switch";
BA_ "Version" SG_ 763 CDM_GbtOpnClsState_SBCM "23.04.02";
BA_ "UserSigValidity" SG_ 763 CDM_GbtOpnClsState_SBCM 0;
BA_ "GenSigSendType" SG_ 763 CDM_GbtOpnClsState_SBCM 4;
BA_ "Description" SG_ 763 CDM_GbtOpnClsState_SBCM "This signal indicates CDM Open/Close Status(Gbt)";
BA_ "Version" SG_ 763 CDM_GbtWarnMsg_SBCM "23.04.02";
BA_ "UserSigValidity" SG_ 763 CDM_GbtWarnMsg_SBCM 0;
BA_ "GenSigSendType" SG_ 763 CDM_GbtWarnMsg_SBCM 4;
BA_ "Description" SG_ 763 CDM_GbtWarnMsg_SBCM "Command for CDM Warning on cluster(Gbt)";
BA_ "Version" SG_ 763 CDM_GbtOutsideOpnSwSta "24.01.03";
BA_ "NetworkRequestHoldingTime" SG_ 763 CDM_GbtOutsideOpnSwSta 5000;
BA_ "NetworkRequest" SG_ 763 CDM_GbtOutsideOpnSwSta 0;
BA_ "UserSigValidity" SG_ 763 CDM_GbtOutsideOpnSwSta 0;
BA_ "GenSigSendType" SG_ 763 CDM_GbtOutsideOpnSwSta 4;
BA_ "Version" SG_ 763 DoorLock_DrvLkOutSta_SBCM "23.02.09";
BA_ "NetworkRequestHoldingTime" SG_ 763 DoorLock_DrvLkOutSta_SBCM 5000;
BA_ "NetworkRequest" SG_ 763 DoorLock_DrvLkOutSta_SBCM 0;
BA_ "UserSigValidity" SG_ 763 DoorLock_DrvLkOutSta_SBCM 0;
BA_ "GenSigSendType" SG_ 763 DoorLock_DrvLkOutSta_SBCM 4;
BA_ "Description" SG_ 763 DoorLock_DrvLkOutSta_SBCM "- Door Lock or Unlock Output State 

0x0 : Off (Door lock/unlock output Off state)

0x1 : On (Door lock/unlock output On state)";
BA_ "Version" SG_ 763 CDM_InsideOpnSwSta "21.07.07";
BA_ "NetworkRequestHoldingTime" SG_ 763 CDM_InsideOpnSwSta 5000;
BA_ "NetworkRequest" SG_ 763 CDM_InsideOpnSwSta 0;
BA_ "UserSigValidity" SG_ 763 CDM_InsideOpnSwSta 7;
BA_ "GenSigSendType" SG_ 763 CDM_InsideOpnSwSta 4;
BA_ "Version" SG_ 761 SBCM_AST_Crc3Val "22.05.03";
BA_ "RoutingFactor" SG_ 761 SBCM_AST_Crc3Val 0;
BA_ "UserSigValidity" SG_ 761 SBCM_AST_Crc3Val 0;
BA_ "GenSigSendType" SG_ 761 SBCM_AST_Crc3Val 4;
BA_ "Description" SG_ 761 SBCM_AST_Crc3Val "The data area for CRC calculation is based on the data length (DLC) of the message DB.

The CRC shall be calculated over the entire data block (excluding the CRC bytes) including the user data, alive counter and Data ID 

 

- CRC Polynomial (0x1D) , Ini";
BA_ "Version" SG_ 761 CDM_TypeOption_AST "24.07.03";
BA_ "RoutingFactor" SG_ 761 CDM_TypeOption_AST 0;
BA_ "NetworkRequestHoldingTime" SG_ 761 CDM_TypeOption_AST 5000;
BA_ "NetworkRequest" SG_ 761 CDM_TypeOption_AST 0;
BA_ "UserSigValidity" SG_ 761 CDM_TypeOption_AST 7;
BA_ "GenSigSendType" SG_ 761 CDM_TypeOption_AST 4;
BA_ "Version" SG_ 761 SBCM_AST_AlvCnt3Val "22.05.03";
BA_ "RoutingFactor" SG_ 761 SBCM_AST_AlvCnt3Val 0;
BA_ "UserSigValidity" SG_ 761 SBCM_AST_AlvCnt3Val 0;
BA_ "GenSigSendType" SG_ 761 SBCM_AST_AlvCnt3Val 4;
BA_ "Description" SG_ 761 SBCM_AST_AlvCnt3Val "For the first transmission request for a data element the counter shall be initialized with 0 and shall be incremented by 1

for every subsequent send request. When the counter reaches the maximum value(0xE), then it shall restart with 0 for the next sen";
BA_ "Version" SG_ 761 CDM_ImmeChgSw_AST "21.07.07";
BA_ "RoutingFactor" SG_ 761 CDM_ImmeChgSw_AST 0;
BA_ "NetworkRequestHoldingTime" SG_ 761 CDM_ImmeChgSw_AST 5000;
BA_ "NetworkRequest" SG_ 761 CDM_ImmeChgSw_AST 0;
BA_ "UserSigValidity" SG_ 761 CDM_ImmeChgSw_AST 7;
BA_ "GenSigSendType" SG_ 761 CDM_ImmeChgSw_AST 4;
BA_ "Version" SG_ 761 CDM_FobSrchReq_AST "24.04.10";
BA_ "RoutingFactor" SG_ 761 CDM_FobSrchReq_AST 0;
BA_ "NetworkRequestHoldingTime" SG_ 761 CDM_FobSrchReq_AST 5000;
BA_ "NetworkRequest" SG_ 761 CDM_FobSrchReq_AST 0;
BA_ "UserSigValidity" SG_ 761 CDM_FobSrchReq_AST 7;
BA_ "GenSigSendType" SG_ 761 CDM_FobSrchReq_AST 4;
BA_ "Version" SG_ 761 CDM_OpnClsState_AST "21.07.07";
BA_ "RoutingFactor" SG_ 761 CDM_OpnClsState_AST 0;
BA_ "NetworkRequestHoldingTime" SG_ 761 CDM_OpnClsState_AST 5000;
BA_ "NetworkRequest" SG_ 761 CDM_OpnClsState_AST 0;
BA_ "UserSigValidity" SG_ 761 CDM_OpnClsState_AST 7;
BA_ "GenSigSendType" SG_ 761 CDM_OpnClsState_AST 4;
BA_ "Version" SG_ 761 CDM_WarnMsg_AST "21.07.07";
BA_ "RoutingFactor" SG_ 761 CDM_WarnMsg_AST 0;
BA_ "NetworkRequestHoldingTime" SG_ 761 CDM_WarnMsg_AST 5000;
BA_ "NetworkRequest" SG_ 761 CDM_WarnMsg_AST 0;
BA_ "UserSigValidity" SG_ 761 CDM_WarnMsg_AST 7;
BA_ "GenSigSendType" SG_ 761 CDM_WarnMsg_AST 4;
BA_ "Version" SG_ 761 Mirror_RH_FoldingSta "21.07.07";
BA_ "RoutingFactor" SG_ 761 Mirror_RH_FoldingSta 0;
BA_ "NetworkRequestHoldingTime" SG_ 761 Mirror_RH_FoldingSta 5000;
BA_ "NetworkRequest" SG_ 761 Mirror_RH_FoldingSta 0;
BA_ "UserSigValidity" SG_ 761 Mirror_RH_FoldingSta 0;
BA_ "GenSigSendType" SG_ 761 Mirror_RH_FoldingSta 4;
BA_ "Version" SG_ 761 Mirror_RH_UnfoldingSta "21.07.07";
BA_ "RoutingFactor" SG_ 761 Mirror_RH_UnfoldingSta 0;
BA_ "NetworkRequestHoldingTime" SG_ 761 Mirror_RH_UnfoldingSta 5000;
BA_ "NetworkRequest" SG_ 761 Mirror_RH_UnfoldingSta 0;
BA_ "UserSigValidity" SG_ 761 Mirror_RH_UnfoldingSta 0;
BA_ "GenSigSendType" SG_ 761 Mirror_RH_UnfoldingSta 4;
BA_ "Version" SG_ 761 CDM_CmdStatus_AST "22.08.03";
BA_ "RoutingFactor" SG_ 761 CDM_CmdStatus_AST 0;
BA_ "NetworkRequestHoldingTime" SG_ 761 CDM_CmdStatus_AST 5000;
BA_ "NetworkRequest" SG_ 761 CDM_CmdStatus_AST 0;
BA_ "UserSigValidity" SG_ 761 CDM_CmdStatus_AST 7;
BA_ "GenSigStartValue" SG_ 761 CDM_CmdStatus_AST 15;
BA_ "GenSigSendType" SG_ 761 CDM_CmdStatus_AST 4;
BA_ "Version" SG_ 761 AST_CrashMRActAlarm "21.07.07";
BA_ "RoutingFactor" SG_ 761 AST_CrashMRActAlarm 0;
BA_ "NetworkRequestHoldingTime" SG_ 761 AST_CrashMRActAlarm 5000;
BA_ "NetworkRequest" SG_ 761 AST_CrashMRActAlarm 0;
BA_ "UserSigValidity" SG_ 761 AST_CrashMRActAlarm 0;
BA_ "GenSigSendType" SG_ 761 AST_CrashMRActAlarm 4;
BA_ "Version" SG_ 761 PwrDRBuzzerOut_AST "21.07.07";
BA_ "RoutingFactor" SG_ 761 PwrDRBuzzerOut_AST 0;
BA_ "NetworkRequestHoldingTime" SG_ 761 PwrDRBuzzerOut_AST 5000;
BA_ "NetworkRequest" SG_ 761 PwrDRBuzzerOut_AST 0;
BA_ "UserSigValidity" SG_ 761 PwrDRBuzzerOut_AST 0;
BA_ "GenSigSendType" SG_ 761 PwrDRBuzzerOut_AST 4;
BA_ "Version" SG_ 761 IMS_OSMirPlayBackSta_RH "21.07.07";
BA_ "RoutingFactor" SG_ 761 IMS_OSMirPlayBackSta_RH 0;
BA_ "NetworkRequestHoldingTime" SG_ 761 IMS_OSMirPlayBackSta_RH 5;
BA_ "NetworkRequest" SG_ 761 IMS_OSMirPlayBackSta_RH 0;
BA_ "UserSigValidity" SG_ 761 IMS_OSMirPlayBackSta_RH 0;
BA_ "GenSigSendType" SG_ 761 IMS_OSMirPlayBackSta_RH 4;
BA_ "Version" SG_ 761 PwrDRClosingASTDrSta "22.04.01";
BA_ "RoutingFactor" SG_ 761 PwrDRClosingASTDrSta 0;
BA_ "NetworkRequestHoldingTime" SG_ 761 PwrDRClosingASTDrSta 5000;
BA_ "NetworkRequest" SG_ 761 PwrDRClosingASTDrSta 0;
BA_ "UserSigValidity" SG_ 761 PwrDRClosingASTDrSta 0;
BA_ "GenSigSendType" SG_ 761 PwrDRClosingASTDrSta 4;
BA_ "Version" SG_ 761 CDM_OutsideOpnSwSta_AST "23.02.02";
BA_ "RoutingFactor" SG_ 761 CDM_OutsideOpnSwSta_AST 0;
BA_ "NetworkRequestHoldingTime" SG_ 761 CDM_OutsideOpnSwSta_AST 5000;
BA_ "NetworkRequest" SG_ 761 CDM_OutsideOpnSwSta_AST 0;
BA_ "UserSigValidity" SG_ 761 CDM_OutsideOpnSwSta_AST 7;
BA_ "GenSigSendType" SG_ 761 CDM_OutsideOpnSwSta_AST 4;
BA_ "Description" SG_ 761 CDM_OutsideOpnSwSta_AST "Charging Door O/S SW State";
BA_ "Version" SG_ 761 SBCM_Longkey_ASTDrAtClsSwSta "22.04.02";
BA_ "RoutingFactor" SG_ 761 SBCM_Longkey_ASTDrAtClsSwSta 0;
BA_ "NetworkRequestHoldingTime" SG_ 761 SBCM_Longkey_ASTDrAtClsSwSta 5000;
BA_ "NetworkRequest" SG_ 761 SBCM_Longkey_ASTDrAtClsSwSta 0;
BA_ "UserSigValidity" SG_ 761 SBCM_Longkey_ASTDrAtClsSwSta 0;
BA_ "GenSigSendType" SG_ 761 SBCM_Longkey_ASTDrAtClsSwSta 4;
BA_ "Version" SG_ 761 Hood_TypeOption_AST "22.10.19";
BA_ "RoutingFactor" SG_ 761 Hood_TypeOption_AST 0;
BA_ "NetworkRequestHoldingTime" SG_ 761 Hood_TypeOption_AST 5000;
BA_ "NetworkRequest" SG_ 761 Hood_TypeOption_AST 0;
BA_ "UserSigValidity" SG_ 761 Hood_TypeOption_AST 0;
BA_ "GenSigSendType" SG_ 761 Hood_TypeOption_AST 4;
BA_ "Description" SG_ 761 Hood_TypeOption_AST "If the E-Hood is applied, the signal will be send.

Frunk signal from SBCM_AST to SBCM_DRV (RHD specification)";
BA_ "Version" SG_ 761 Warn_HoodSwSta_AST "22.10.19";
BA_ "RoutingFactor" SG_ 761 Warn_HoodSwSta_AST 0;
BA_ "NetworkRequestHoldingTime" SG_ 761 Warn_HoodSwSta_AST 5000;
BA_ "NetworkRequest" SG_ 761 Warn_HoodSwSta_AST 0;
BA_ "UserSigValidity" SG_ 761 Warn_HoodSwSta_AST 0;
BA_ "GenSigSendType" SG_ 761 Warn_HoodSwSta_AST 4;
BA_ "Description" SG_ 761 Warn_HoodSwSta_AST "Frunk signal from SBCM_AST to SBCM_DRV (RHD specification)";
BA_ "Version" SG_ 761 FrunkWarning_AST "22.10.19";
BA_ "RoutingFactor" SG_ 761 FrunkWarning_AST 0;
BA_ "NetworkRequestHoldingTime" SG_ 761 FrunkWarning_AST 5000;
BA_ "NetworkRequest" SG_ 761 FrunkWarning_AST 0;
BA_ "UserSigValidity" SG_ 761 FrunkWarning_AST 0;
BA_ "GenSigSendType" SG_ 761 FrunkWarning_AST 4;
BA_ "Description" SG_ 761 FrunkWarning_AST "Frunk signal from SBCM_AST to SBCM_DRV (RHD specification)";
BA_ "Version" SG_ 761 SBCM_FrunkSta_AST "22.10.19";
BA_ "RoutingFactor" SG_ 761 SBCM_FrunkSta_AST 0;
BA_ "NetworkRequestHoldingTime" SG_ 761 SBCM_FrunkSta_AST 5000;
BA_ "NetworkRequest" SG_ 761 SBCM_FrunkSta_AST 0;
BA_ "UserSigValidity" SG_ 761 SBCM_FrunkSta_AST 0;
BA_ "GenSigSendType" SG_ 761 SBCM_FrunkSta_AST 4;
BA_ "Description" SG_ 761 SBCM_FrunkSta_AST "Frunk signal from SBCM_AST to SBCM_DRV (RHD specification)";
BA_ "Version" SG_ 761 Ast_DrLkRetryFail_SBCM "23.03.00";
BA_ "RoutingFactor" SG_ 761 Ast_DrLkRetryFail_SBCM 0;
BA_ "NetworkRequestHoldingTime" SG_ 761 Ast_DrLkRetryFail_SBCM 5000;
BA_ "NetworkRequest" SG_ 761 Ast_DrLkRetryFail_SBCM 0;
BA_ "UserSigValidity" SG_ 761 Ast_DrLkRetryFail_SBCM 0;
BA_ "TimeoutValue" SG_ 761 Ast_DrLkRetryFail_SBCM "0x0";
BA_ "GenSigSendType" SG_ 761 Ast_DrLkRetryFail_SBCM 4;
BA_ "Version" SG_ 761 DoorLock_AstLkOutSta_SBCM "23.02.09";
BA_ "RoutingFactor" SG_ 761 DoorLock_AstLkOutSta_SBCM 0;
BA_ "NetworkRequestHoldingTime" SG_ 761 DoorLock_AstLkOutSta_SBCM 5000;
BA_ "NetworkRequest" SG_ 761 DoorLock_AstLkOutSta_SBCM 0;
BA_ "UserSigValidity" SG_ 761 DoorLock_AstLkOutSta_SBCM 0;
BA_ "GenSigSendType" SG_ 761 DoorLock_AstLkOutSta_SBCM 4;
BA_ "Description" SG_ 761 DoorLock_AstLkOutSta_SBCM "- Door Lock or Unlock Output State 

0x0 : Off (Door lock/unlock output Off state)

0x1 : On (Door lock/unlock output On state)";
BA_ "Version" SG_ 761 SBCM_AST_DiagSta "21.07.07";
BA_ "RoutingFactor" SG_ 761 SBCM_AST_DiagSta 0;
BA_ "NetworkRequestHoldingTime" SG_ 761 SBCM_AST_DiagSta 5000;
BA_ "NetworkRequest" SG_ 761 SBCM_AST_DiagSta 0;
BA_ "UserSigValidity" SG_ 761 SBCM_AST_DiagSta 0;
BA_ "GenSigSendType" SG_ 761 SBCM_AST_DiagSta 4;
BA_ "Version" SG_ 758 SBCM_DRV_Crc2Val "22.05.03";
BA_ "RoutingFactor" SG_ 758 SBCM_DRV_Crc2Val 0;
BA_ "UserSigValidity" SG_ 758 SBCM_DRV_Crc2Val 0;
BA_ "GenSigSendType" SG_ 758 SBCM_DRV_Crc2Val 4;
BA_ "Description" SG_ 758 SBCM_DRV_Crc2Val "The data area for CRC calculation is based on the data length (DLC) of the message DB.

The CRC shall be calculated over the entire data block (excluding the CRC bytes) including the user data, alive counter and Data ID 

 

- CRC Polynomial (0x1D) , Ini";
BA_ "Version" SG_ 758 DoorLock_CtrlDrLkUnLkSwSta_SBCM "21.07.07";
BA_ "RoutingFactor" SG_ 758 DoorLock_CtrlDrLkUnLkSwSta_SBCM 0;
BA_ "NetworkRequestHoldingTime" SG_ 758 DoorLock_CtrlDrLkUnLkSwSta_SBCM 5000;
BA_ "NetworkRequest" SG_ 758 DoorLock_CtrlDrLkUnLkSwSta_SBCM 0;
BA_ "UserSigValidity" SG_ 758 DoorLock_CtrlDrLkUnLkSwSta_SBCM 0;
BA_ "GenSigSendType" SG_ 758 DoorLock_CtrlDrLkUnLkSwSta_SBCM 4;
BA_ "Description" SG_ 758 DoorLock_CtrlDrLkUnLkSwSta_SBCM "Central Door Lock/Unlock Switch State";
BA_ "Version" SG_ 758 SBCM_DRV_AlvCnt2Val "22.05.03";
BA_ "RoutingFactor" SG_ 758 SBCM_DRV_AlvCnt2Val 0;
BA_ "UserSigValidity" SG_ 758 SBCM_DRV_AlvCnt2Val 0;
BA_ "GenSigSendType" SG_ 758 SBCM_DRV_AlvCnt2Val 4;
BA_ "Description" SG_ 758 SBCM_DRV_AlvCnt2Val "For the first transmission request for a data element the counter shall be initialized with 0 and shall be incremented by 1

for every subsequent send request. When the counter reaches the maximum value(0xE), then it shall restart with 0 for the next sen";
BA_ "Version" SG_ 758 SBCM_PsvDrLkReq "21.07.07";
BA_ "RoutingFactor" SG_ 758 SBCM_PsvDrLkReq 0;
BA_ "NetworkRequest" SG_ 758 SBCM_PsvDrLkReq 0;
BA_ "UserSigValidity" SG_ 758 SBCM_PsvDrLkReq 0;
BA_ "GenSigSendType" SG_ 758 SBCM_PsvDrLkReq 4;
BA_ "Version" SG_ 758 CDMAutoWashModeSet_SBCM "22.07.00";
BA_ "RoutingFactor" SG_ 758 CDMAutoWashModeSet_SBCM 0;
BA_ "UserSigValidity" SG_ 758 CDMAutoWashModeSet_SBCM 3;
BA_ "GenSigSendType" SG_ 758 CDMAutoWashModeSet_SBCM 4;
BA_ "Version" SG_ 758 USM_DrvGhostDoorSta "21.07.07";
BA_ "RoutingFactor" SG_ 758 USM_DrvGhostDoorSta 0;
BA_ "NetworkRequestHoldingTime" SG_ 758 USM_DrvGhostDoorSta 5000;
BA_ "NetworkRequest" SG_ 758 USM_DrvGhostDoorSta 0;
BA_ "UserSigValidity" SG_ 758 USM_DrvGhostDoorSta 0;
BA_ "GenSigSendType" SG_ 758 USM_DrvGhostDoorSta 4;
BA_ "Version" SG_ 758 Mirror_LH_FoldingSta "21.07.07";
BA_ "RoutingFactor" SG_ 758 Mirror_LH_FoldingSta 0;
BA_ "NetworkRequestHoldingTime" SG_ 758 Mirror_LH_FoldingSta 5000;
BA_ "NetworkRequest" SG_ 758 Mirror_LH_FoldingSta 0;
BA_ "UserSigValidity" SG_ 758 Mirror_LH_FoldingSta 0;
BA_ "GenSigSendType" SG_ 758 Mirror_LH_FoldingSta 4;
BA_ "Version" SG_ 758 Mirror_LH_UnfoldingSta "21.07.07";
BA_ "RoutingFactor" SG_ 758 Mirror_LH_UnfoldingSta 0;
BA_ "NetworkRequestHoldingTime" SG_ 758 Mirror_LH_UnfoldingSta 5000;
BA_ "NetworkRequest" SG_ 758 Mirror_LH_UnfoldingSta 0;
BA_ "UserSigValidity" SG_ 758 Mirror_LH_UnfoldingSta 0;
BA_ "GenSigSendType" SG_ 758 Mirror_LH_UnfoldingSta 4;
BA_ "Version" SG_ 758 DRV_CrashMRActAlarm "21.07.07";
BA_ "RoutingFactor" SG_ 758 DRV_CrashMRActAlarm 0;
BA_ "NetworkRequestHoldingTime" SG_ 758 DRV_CrashMRActAlarm 5000;
BA_ "NetworkRequest" SG_ 758 DRV_CrashMRActAlarm 0;
BA_ "UserSigValidity" SG_ 758 DRV_CrashMRActAlarm 0;
BA_ "GenSigSendType" SG_ 758 DRV_CrashMRActAlarm 4;
BA_ "Version" SG_ 758 MirrorFldReq "21.07.07";
BA_ "RoutingFactor" SG_ 758 MirrorFldReq 0;
BA_ "NetworkRequestHoldingTime" SG_ 758 MirrorFldReq 5;
BA_ "NetworkRequest" SG_ 758 MirrorFldReq 0;
BA_ "UserSigValidity" SG_ 758 MirrorFldReq 0;
BA_ "GenSigSendType" SG_ 758 MirrorFldReq 4;
BA_ "Version" SG_ 758 OMU_TypeOption_DRV "21.07.07";
BA_ "RoutingFactor" SG_ 758 OMU_TypeOption_DRV 0;
BA_ "NetworkRequestHoldingTime" SG_ 758 OMU_TypeOption_DRV 5000;
BA_ "NetworkRequest" SG_ 758 OMU_TypeOption_DRV 0;
BA_ "UserSigValidity" SG_ 758 OMU_TypeOption_DRV 0;
BA_ "GenSigSendType" SG_ 758 OMU_TypeOption_DRV 4;
BA_ "Version" SG_ 758 IMS_OSMirPlayBackSta_LH "21.07.07";
BA_ "RoutingFactor" SG_ 758 IMS_OSMirPlayBackSta_LH 0;
BA_ "NetworkRequestHoldingTime" SG_ 758 IMS_OSMirPlayBackSta_LH 5;
BA_ "NetworkRequest" SG_ 758 IMS_OSMirPlayBackSta_LH 0;
BA_ "UserSigValidity" SG_ 758 IMS_OSMirPlayBackSta_LH 0;
BA_ "GenSigSendType" SG_ 758 IMS_OSMirPlayBackSta_LH 4;
BA_ "Version" SG_ 758 ECMMRR_PLUS "21.07.07";
BA_ "RoutingFactor" SG_ 758 ECMMRR_PLUS 0;
BA_ "NetworkRequestHoldingTime" SG_ 758 ECMMRR_PLUS 5000;
BA_ "NetworkRequest" SG_ 758 ECMMRR_PLUS 0;
BA_ "UserSigValidity" SG_ 758 ECMMRR_PLUS 0;
BA_ "GenSigSendType" SG_ 758 ECMMRR_PLUS 4;
BA_ "Description" SG_ 758 ECMMRR_PLUS "This signal for passenger outside mirror OEC function(or ECM)

SBCM_DRV receive the ECM voltage value via H/wiring and then send this signal to SBCM_AST";
BA_ "Version" SG_ 758 SBCM_DRV_DiagSta "21.07.07";
BA_ "RoutingFactor" SG_ 758 SBCM_DRV_DiagSta 0;
BA_ "NetworkRequestHoldingTime" SG_ 758 SBCM_DRV_DiagSta 5000;
BA_ "NetworkRequest" SG_ 758 SBCM_DRV_DiagSta 0;
BA_ "UserSigValidity" SG_ 758 SBCM_DRV_DiagSta 0;
BA_ "GenSigSendType" SG_ 758 SBCM_DRV_DiagSta 4;
BA_ "Version" SG_ 2344811012 xEV_BattRCHTimeEst "19.04.06";
BA_ "RoutingFactor" SG_ 2344811012 xEV_BattRCHTimeEst 2;
BA_ "UserSigValidity" SG_ 2344811012 xEV_BattRCHTimeEst 7;
BA_ "Description" SG_ 2344811012 xEV_BattRCHTimeEst "calculated charging time by esrimated OBC output power

***HS CAN : BMS7(0x598), CR_Bms_RCHTimeEst***";
BA_ "Version" SG_ 2344811012 EV_DischrgCurrLimForV2X "20.04.03";
BA_ "RoutingFactor" SG_ 2344811012 EV_DischrgCurrLimForV2X 2;
BA_ "UserSigValidity" SG_ 2344811012 EV_DischrgCurrLimForV2X 7;
BA_ "Description" SG_ 2344811012 EV_DischrgCurrLimForV2X "Discharge Current Limit(for V2X)

***new signal***";
BA_ "Version" SG_ 2344811012 xEV_Bms_IsolDetDeactFuncSta "20.06.10";
BA_ "RoutingFactor" SG_ 2344811012 xEV_Bms_IsolDetDeactFuncSta 2;
BA_ "UserSigValidity" SG_ 2344811012 xEV_Bms_IsolDetDeactFuncSta 7;
BA_ "Description" SG_ 2344811012 xEV_Bms_IsolDetDeactFuncSta "xEV_Isolation Detection Circuit Deactivate Function Status (GDS Function)";
BA_ "Version" SG_ 2344811012 xEV_Bms_CellBalDeactFuncSta "20.06.10";
BA_ "RoutingFactor" SG_ 2344811012 xEV_Bms_CellBalDeactFuncSta 2;
BA_ "UserSigValidity" SG_ 2344811012 xEV_Bms_CellBalDeactFuncSta 7;
BA_ "Description" SG_ 2344811012 xEV_Bms_CellBalDeactFuncSta "xEV_Cell Balancing Deactivate Function Status (GDS Function)";
BA_ "Version" SG_ 2344811012 EV_HiddenSOC_ChangeReq "23.01.00";
BA_ "RoutingFactor" SG_ 2344811012 EV_HiddenSOC_ChangeReq 2;
BA_ "UserSigValidity" SG_ 2344811012 EV_HiddenSOC_ChangeReq 7;
BA_ "Description" SG_ 2344811012 EV_HiddenSOC_ChangeReq "Hidden SOC Change alarm";
BA_ "Version" SG_ 2344811012 EV_V2XDischrgLimSocVal_SYNC "20.11.02";
BA_ "RoutingFactor" SG_ 2344811012 EV_V2XDischrgLimSocVal_SYNC 2;
BA_ "UserSigValidity" SG_ 2344811012 EV_V2XDischrgLimSocVal_SYNC 7;
BA_ "Description" SG_ 2344811012 EV_V2XDischrgLimSocVal_SYNC "Feedback SOC of  V2X discharge limitation for sync by BMS

***New Signal***";
BA_ "Version" SG_ 2344811012 xEV_BMS_SOC_2nd "20.03.07";
BA_ "RoutingFactor" SG_ 2344811012 xEV_BMS_SOC_2nd 2;
BA_ "UserSigValidity" SG_ 2344811012 xEV_BMS_SOC_2nd 7;
BA_ "Description" SG_ 2344811012 xEV_BMS_SOC_2nd "2nd SOC for NEV";
BA_ "Version" SG_ 2344811011 PHEV_SubInltTempVal "18.11.01";
BA_ "RoutingFactor" SG_ 2344811011 PHEV_SubInltTempVal 2;
BA_ "UserSigValidity" SG_ 2344811011 PHEV_SubInltTempVal 7;
BA_ "Description" SG_ 2344811011 PHEV_SubInltTempVal "Sub Pack Inlet Temperature

(If MSB is 1, (PH) = 1 * (HEX) ? 256 [¡É]

else (PH) = 1 * (HEX) [¡É])";
BA_ "Version" SG_ 2344811011 xEV_12VAlarmReqForICU "18.11.01";
BA_ "RoutingFactor" SG_ 2344811011 xEV_12VAlarmReqForICU 2;
BA_ "UserSigValidity" SG_ 2344811011 xEV_12VAlarmReqForICU 7;
BA_ "Description" SG_ 2344811011 xEV_12VAlarmReqForICU "xEV_12V Battery Alarm Request For ICU";
BA_ "Version" SG_ 2344811011 xEV_AuxBattChrgReq "23.02.01";
BA_ "RoutingFactor" SG_ 2344811011 xEV_AuxBattChrgReq 2;
BA_ "UserSigValidity" SG_ 2344811011 xEV_AuxBattChrgReq 7;
BA_ "Description" SG_ 2344811011 xEV_AuxBattChrgReq "Aux. Battery Charge Request Flag

LV2 Charge Request : Battery Saver

LV1 Charge Request : Auxiliary Charge";
BA_ "Version" SG_ 2344811011 xEV_12VDarkCurrAlarmForICU "18.11.01";
BA_ "RoutingFactor" SG_ 2344811011 xEV_12VDarkCurrAlarmForICU 2;
BA_ "UserSigValidity" SG_ 2344811011 xEV_12VDarkCurrAlarmForICU 7;
BA_ "Description" SG_ 2344811011 xEV_12VDarkCurrAlarmForICU "12V Battery Alarm request for ICU(CGW)";
BA_ "Version" SG_ 2344811011 xEV_12VBatVLmt "18.11.01";
BA_ "RoutingFactor" SG_ 2344811011 xEV_12VBatVLmt 2;
BA_ "UserSigValidity" SG_ 2344811011 xEV_12VBatVLmt 7;
BA_ "Description" SG_ 2344811011 xEV_12VBatVLmt "xEV_12VBatteryVoltageLimit(CR_Bms_12V_BatV_Lmt)";
BA_ "Version" SG_ 2344811011 xEV_CharBatInfoReqForSDC "18.11.01";
BA_ "RoutingFactor" SG_ 2344811011 xEV_CharBatInfoReqForSDC 2;
BA_ "UserSigValidity" SG_ 2344811011 xEV_CharBatInfoReqForSDC 7;
BA_ "Description" SG_ 2344811011 xEV_CharBatInfoReqForSDC "Function of determining first battery to charge (12V battery or High voltage battery)";
BA_ "Version" SG_ 2344811011 xEV_ClimateOffReq "18.11.01";
BA_ "RoutingFactor" SG_ 2344811011 xEV_ClimateOffReq 2;
BA_ "UserSigValidity" SG_ 2344811011 xEV_ClimateOffReq 7;
BA_ "Description" SG_ 2344811011 xEV_ClimateOffReq "xEV_ClimateOffRequest  --Alarm flag at climate off requested (CF_Bms_ClimateOffReq)";
BA_ "Version" SG_ 2344811011 xEV_MainRlyOnRetrySta "18.11.01";
BA_ "RoutingFactor" SG_ 2344811011 xEV_MainRlyOnRetrySta 2;
BA_ "UserSigValidity" SG_ 2344811011 xEV_MainRlyOnRetrySta 7;
BA_ "Description" SG_ 2344811011 xEV_MainRlyOnRetrySta "BMS sets this Flag until BMS completes Relay ON Sequence for Relay recontact";
BA_ "Version" SG_ 2344811011 xEV_Bms_BlackBox_Data_req "20.03.06";
BA_ "RoutingFactor" SG_ 2344811011 xEV_Bms_BlackBox_Data_req 2;
BA_ "UserSigValidity" SG_ 2344811011 xEV_Bms_BlackBox_Data_req 7;
BA_ "Description" SG_ 2344811011 xEV_Bms_BlackBox_Data_req "For Saving BMS data set, this signal transmits to MCU";
BA_ "Version" SG_ 2344811011 xEV_12V_BatDchCurrLmt "18.11.01";
BA_ "RoutingFactor" SG_ 2344811011 xEV_12V_BatDchCurrLmt 2;
BA_ "UserSigValidity" SG_ 2344811011 xEV_12V_BatDchCurrLmt 7;
BA_ "Description" SG_ 2344811011 xEV_12V_BatDchCurrLmt "xEV_12V Battery Discharge Current Limit (CR_Bms_12V_BatDchI_Lmt)";
BA_ "Version" SG_ 2344811011 xEV_12VChargeReq "18.11.02";
BA_ "RoutingFactor" SG_ 2344811011 xEV_12VChargeReq 2;
BA_ "UserSigValidity" SG_ 2344811011 xEV_12VChargeReq 7;
BA_ "Description" SG_ 2344811011 xEV_12VChargeReq "xEV_12VBatteryChargeRequest (for 12V battery over-discharge protection) (CF_Bms_12_ChargeReq)";
BA_ "Version" SG_ 2344811011 xEV_BmsRomType "21.01.03";
BA_ "RoutingFactor" SG_ 2344811011 xEV_BmsRomType 2;
BA_ "UserSigValidity" SG_ 2344811011 xEV_BmsRomType 7;
BA_ "Description" SG_ 2344811011 xEV_BmsRomType "BMS rom type variation of Battery Pack Specification";
BA_ "Version" SG_ 2344811011 xEV_12V_CurrFltDetectReq "19.01.00";
BA_ "RoutingFactor" SG_ 2344811011 xEV_12V_CurrFltDetectReq 2;
BA_ "UserSigValidity" SG_ 2344811011 xEV_12V_CurrFltDetectReq 7;
BA_ "Description" SG_ 2344811011 xEV_12V_CurrFltDetectReq "xEV_12V Battery Current Sensor Fault Detect Request";
BA_ "Version" SG_ 2344811011 xEV_PRATempSnsVal_ "19.01.00";
BA_ "RoutingFactor" SG_ 2344811011 xEV_PRATempSnsVal_ 2;
BA_ "UserSigValidity" SG_ 2344811011 xEV_PRATempSnsVal_ 7;
BA_ "Description" SG_ 2344811011 xEV_PRATempSnsVal_ "xEV_PRATemperatureSensorValue";
BA_ "Version" SG_ 2344811011 xEV_PRATempSns2Val_ "19.01.00";
BA_ "RoutingFactor" SG_ 2344811011 xEV_PRATempSns2Val_ 2;
BA_ "UserSigValidity" SG_ 2344811011 xEV_PRATempSns2Val_ 7;
BA_ "Description" SG_ 2344811011 xEV_PRATempSns2Val_ "xEV_PRATemperatureSensor2Value";
BA_ "Version" SG_ 2344811011 xEV_12VRlyOnSwReq "18.11.01";
BA_ "RoutingFactor" SG_ 2344811011 xEV_12VRlyOnSwReq 2;
BA_ "UserSigValidity" SG_ 2344811011 xEV_12VRlyOnSwReq 7;
BA_ "Description" SG_ 2344811011 xEV_12VRlyOnSwReq "12V relay ON switch ON status. BMS sets this Flag when 12V Relay Switch is ON.";
BA_ "Version" SG_ 2344811010 xEV_BattCurrVal "18.11.01";
BA_ "RoutingFactor" SG_ 2344811010 xEV_BattCurrVal 2;
BA_ "UserSigValidity" SG_ 2344811010 xEV_BattCurrVal 7;
BA_ "Description" SG_ 2344811010 xEV_BattCurrVal "xEV_Battery Current Value (CR_Bms_BatI_A)";
BA_ "Version" SG_ 2344811010 xEV_MinBattTempVal "21.10.04";
BA_ "RoutingFactor" SG_ 2344811010 xEV_MinBattTempVal 2;
BA_ "UserSigValidity" SG_ 2344811010 xEV_MinBattTempVal 7;
BA_ "Description" SG_ 2344811010 xEV_MinBattTempVal "Minimum Battery Temperature

(All the analog value indicate valid values except for Error ID)";
BA_ "Version" SG_ 2344811010 xEV_MaxBattTempVal "18.11.01";
BA_ "RoutingFactor" SG_ 2344811010 xEV_MaxBattTempVal 2;
BA_ "UserSigValidity" SG_ 2344811010 xEV_MaxBattTempVal 7;
BA_ "Description" SG_ 2344811010 xEV_MaxBattTempVal "Maximum Battery Temperature";
BA_ "Version" SG_ 2344811010 xEV_FanSpdStpSta "18.11.01";
BA_ "RoutingFactor" SG_ 2344811010 xEV_FanSpdStpSta 2;
BA_ "UserSigValidity" SG_ 2344811010 xEV_FanSpdStpSta 7;
BA_ "Description" SG_ 2344811010 xEV_FanSpdStpSta "Battery Cooling Fan Speed Step";
BA_ "Version" SG_ 2344811010 xEV_12VRlyOffAlrmReq "18.11.01";
BA_ "RoutingFactor" SG_ 2344811010 xEV_12VRlyOffAlrmReq 2;
BA_ "UserSigValidity" SG_ 2344811010 xEV_12VRlyOffAlrmReq 7;
BA_ "Description" SG_ 2344811010 xEV_12VRlyOffAlrmReq "12V Battery Relay Off Alarm Request";
BA_ "Version" SG_ 2344811010 xEV_12VRlyOnAlrmReq "18.11.01";
BA_ "RoutingFactor" SG_ 2344811010 xEV_12VRlyOnAlrmReq 2;
BA_ "UserSigValidity" SG_ 2344811010 xEV_12VRlyOnAlrmReq 7;
BA_ "Description" SG_ 2344811010 xEV_12VRlyOnAlrmReq "12V Battery Relay On Alarm Request";
BA_ "Version" SG_ 2344811010 xEV_DiagGrpVal "18.11.01";
BA_ "RoutingFactor" SG_ 2344811010 xEV_DiagGrpVal 2;
BA_ "UserSigValidity" SG_ 2344811010 xEV_DiagGrpVal 7;
BA_ "Description" SG_ 2344811010 xEV_DiagGrpVal "Diagnosis code";
BA_ "Version" SG_ 2344811010 xEV_DiagMonVal "18.11.01";
BA_ "RoutingFactor" SG_ 2344811010 xEV_DiagMonVal 2;
BA_ "UserSigValidity" SG_ 2344811010 xEV_DiagMonVal 7;
BA_ "Description" SG_ 2344811010 xEV_DiagMonVal "Diagnosis data";
BA_ "Version" SG_ 2344811010 xEV_SocDis "21.10.04";
BA_ "RoutingFactor" SG_ 2344811010 xEV_SocDis 2;
BA_ "UserSigValidity" SG_ 2344811010 xEV_SocDis 7;
BA_ "Description" SG_ 2344811010 xEV_SocDis "Cluster, AVN Display SOC

(All the analog value indicate valid values except for Error ID)";
BA_ "Version" SG_ 2344811009 BMS_Crc2Val "21.09.03";
BA_ "RoutingFactor" SG_ 2344811009 BMS_Crc2Val 2;
BA_ "UserSigValidity" SG_ 2344811009 BMS_Crc2Val 3;
BA_ "GenSigStartValue" SG_ 2344811009 BMS_Crc2Val 65535;
BA_ "Description" SG_ 2344811009 BMS_Crc2Val "The data area for CRC calculation is based on the data length (DLC) of the message DB.

The CRC shall be calculated over the entire data block (excluding the CRC bytes) including the user data, alive counter and Data ID



- CRC Polynomial (0x1021) , Ini";
BA_ "Version" SG_ 2344811009 BMS_AlvCnt2Val "21.09.03";
BA_ "RoutingFactor" SG_ 2344811009 BMS_AlvCnt2Val 2;
BA_ "UserSigValidity" SG_ 2344811009 BMS_AlvCnt2Val 3;
BA_ "Description" SG_ 2344811009 BMS_AlvCnt2Val "For the first transmission request for a data element the counter shall be initialized with 0 and shall be incremented by 1 for every subsequent send request. 

When the counter reaches the maximum value(0xFF), then it shall restart with 0 for the next s";
BA_ "Version" SG_ 2344811009 xEV_SrvLmpReq "18.11.01";
BA_ "RoutingFactor" SG_ 2344811009 xEV_SrvLmpReq 2;
BA_ "UserSigValidity" SG_ 2344811009 xEV_SrvLmpReq 7;
BA_ "Description" SG_ 2344811009 xEV_SrvLmpReq "Service Lamp request";
BA_ "Version" SG_ 2344811009 xEV_MainRlyOnSta "18.11.01";
BA_ "RoutingFactor" SG_ 2344811009 xEV_MainRlyOnSta 2;
BA_ "UserSigValidity" SG_ 2344811009 xEV_MainRlyOnSta 7;
BA_ "Description" SG_ 2344811009 xEV_MainRlyOnSta "Main Relay On Status";
BA_ "Version" SG_ 2344811009 xEV_SysFltSta "18.11.01";
BA_ "RoutingFactor" SG_ 2344811009 xEV_SysFltSta 2;
BA_ "UserSigValidity" SG_ 2344811009 xEV_SysFltSta 7;
BA_ "Description" SG_ 2344811009 xEV_SysFltSta "BMS Fault";
BA_ "Version" SG_ 2344811009 EV_Unreliable_SOC "23.03.01";
BA_ "RoutingFactor" SG_ 2344811009 EV_Unreliable_SOC 2;
BA_ "UserSigValidity" SG_ 2344811009 EV_Unreliable_SOC 7;
BA_ "Description" SG_ 2344811009 EV_Unreliable_SOC "LFP Battery Unreliable SOC Alarm Flag (to Cluster/AVN)";
BA_ "Version" SG_ 2344811009 xEV_BattRmnEnrgVal "18.11.01";
BA_ "RoutingFactor" SG_ 2344811009 xEV_BattRmnEnrgVal 2;
BA_ "UserSigValidity" SG_ 2344811009 xEV_BattRmnEnrgVal 7;
BA_ "Description" SG_ 2344811009 xEV_BattRmnEnrgVal "Difference of increased or decreased battery resistance";
BA_ "Version" SG_ 2344811009 xEV_InltTempVal "20.07.05";
BA_ "RoutingFactor" SG_ 2344811009 xEV_InltTempVal 2;
BA_ "UserSigValidity" SG_ 2344811009 xEV_InltTempVal 7;
BA_ "Description" SG_ 2344811009 xEV_InltTempVal "Battery Inlet Temperature";
BA_ "Version" SG_ 2344811009 xEV_MinBattCelVoltVal "18.11.01";
BA_ "RoutingFactor" SG_ 2344811009 xEV_MinBattCelVoltVal 2;
BA_ "UserSigValidity" SG_ 2344811009 xEV_MinBattCelVoltVal 7;
BA_ "GenSigStartValue" SG_ 2344811009 xEV_MinBattCelVoltVal 3;
BA_ "Description" SG_ 2344811009 xEV_MinBattCelVoltVal "Minimum Battery Cell Voltage";
BA_ "Version" SG_ 2344811009 xEV_MaxBattCelVoltVal "18.11.01";
BA_ "RoutingFactor" SG_ 2344811009 xEV_MaxBattCelVoltVal 2;
BA_ "UserSigValidity" SG_ 2344811009 xEV_MaxBattCelVoltVal 7;
BA_ "GenSigStartValue" SG_ 2344811009 xEV_MaxBattCelVoltVal 3;
BA_ "Description" SG_ 2344811009 xEV_MaxBattCelVoltVal "Maximum Battery Cell Voltage";
BA_ "Version" SG_ 733 CMS_LH_Crc1Val "21.09.03";
BA_ "RoutingFactor" SG_ 733 CMS_LH_Crc1Val 0;
BA_ "UserSigValidity" SG_ 733 CMS_LH_Crc1Val 0;
BA_ "GenSigSendType" SG_ 733 CMS_LH_Crc1Val 4;
BA_ "Description" SG_ 733 CMS_LH_Crc1Val "The data area for CRC calculation is based on the data length (DLC) of the message DB.

The CRC shall be calculated over the entire data block (excluding the CRC bytes) including the user data, alive counter and Data ID 

 

- CRC Polynomial (0x1D) , Ini";
BA_ "Version" SG_ 733 CMS_LH_AlvCnt1Val "21.09.03";
BA_ "RoutingFactor" SG_ 733 CMS_LH_AlvCnt1Val 0;
BA_ "UserSigValidity" SG_ 733 CMS_LH_AlvCnt1Val 0;
BA_ "GenSigSendType" SG_ 733 CMS_LH_AlvCnt1Val 4;
BA_ "Description" SG_ 733 CMS_LH_AlvCnt1Val "For the first transmission request for a data element the counter shall be initialized with 0 and shall be incremented by 1

for every subsequent send request. When the counter reaches the maximum value(0xE), then it shall restart with 0 for the next sen";
BA_ "Version" SG_ 733 USM_TurnDstLnDispSta "21.08.01";
BA_ "RoutingFactor" SG_ 733 USM_TurnDstLnDispSta 0;
BA_ "NetworkRequestHoldingTime" SG_ 733 USM_TurnDstLnDispSta 5;
BA_ "NetworkRequest" SG_ 733 USM_TurnDstLnDispSta 0;
BA_ "UserSigValidity" SG_ 733 USM_TurnDstLnDispSta 0;
BA_ "GenSigSendType" SG_ 733 USM_TurnDstLnDispSta 4;
BA_ "Version" SG_ 733 USM_TurnDstLnDispStaRH "21.08.01";
BA_ "RoutingFactor" SG_ 733 USM_TurnDstLnDispStaRH 0;
BA_ "NetworkRequestHoldingTime" SG_ 733 USM_TurnDstLnDispStaRH 5;
BA_ "NetworkRequest" SG_ 733 USM_TurnDstLnDispStaRH 0;
BA_ "UserSigValidity" SG_ 733 USM_TurnDstLnDispStaRH 0;
BA_ "GenSigSendType" SG_ 733 USM_TurnDstLnDispStaRH 4;
BA_ "Version" SG_ 733 USM_RhstaLvlEnaSta "21.08.01";
BA_ "RoutingFactor" SG_ 733 USM_RhstaLvlEnaSta 0;
BA_ "NetworkRequestHoldingTime" SG_ 733 USM_RhstaLvlEnaSta 5;
BA_ "NetworkRequest" SG_ 733 USM_RhstaLvlEnaSta 0;
BA_ "UserSigValidity" SG_ 733 USM_RhstaLvlEnaSta 0;
BA_ "GenSigSendType" SG_ 733 USM_RhstaLvlEnaSta 4;
BA_ "Version" SG_ 733 USM_RhstaLvlEnaStaRH "21.08.01";
BA_ "RoutingFactor" SG_ 733 USM_RhstaLvlEnaStaRH 0;
BA_ "NetworkRequestHoldingTime" SG_ 733 USM_RhstaLvlEnaStaRH 5;
BA_ "NetworkRequest" SG_ 733 USM_RhstaLvlEnaStaRH 0;
BA_ "UserSigValidity" SG_ 733 USM_RhstaLvlEnaStaRH 0;
BA_ "GenSigSendType" SG_ 733 USM_RhstaLvlEnaStaRH 4;
BA_ "Version" SG_ 733 USM_CMSDayBrgtnsLvlLHSta "21.08.01";
BA_ "RoutingFactor" SG_ 733 USM_CMSDayBrgtnsLvlLHSta 0;
BA_ "NetworkRequestHoldingTime" SG_ 733 USM_CMSDayBrgtnsLvlLHSta 5;
BA_ "NetworkRequest" SG_ 733 USM_CMSDayBrgtnsLvlLHSta 0;
BA_ "UserSigValidity" SG_ 733 USM_CMSDayBrgtnsLvlLHSta 0;
BA_ "GenSigStartValue" SG_ 733 USM_CMSDayBrgtnsLvlLHSta 5;
BA_ "GenSigSendType" SG_ 733 USM_CMSDayBrgtnsLvlLHSta 4;
BA_ "Version" SG_ 733 USM_CMSNgtBrgtnsLvlLHSta "21.08.01";
BA_ "RoutingFactor" SG_ 733 USM_CMSNgtBrgtnsLvlLHSta 0;
BA_ "NetworkRequestHoldingTime" SG_ 733 USM_CMSNgtBrgtnsLvlLHSta 5;
BA_ "NetworkRequest" SG_ 733 USM_CMSNgtBrgtnsLvlLHSta 0;
BA_ "UserSigValidity" SG_ 733 USM_CMSNgtBrgtnsLvlLHSta 0;
BA_ "GenSigStartValue" SG_ 733 USM_CMSNgtBrgtnsLvlLHSta 5;
BA_ "GenSigSendType" SG_ 733 USM_CMSNgtBrgtnsLvlLHSta 4;
BA_ "Version" SG_ 733 IMS_CMSPlayBackSta_LH "21.08.01";
BA_ "RoutingFactor" SG_ 733 IMS_CMSPlayBackSta_LH 0;
BA_ "NetworkRequestHoldingTime" SG_ 733 IMS_CMSPlayBackSta_LH 5;
BA_ "NetworkRequest" SG_ 733 IMS_CMSPlayBackSta_LH 0;
BA_ "UserSigValidity" SG_ 733 IMS_CMSPlayBackSta_LH 0;
BA_ "GenSigSendType" SG_ 733 IMS_CMSPlayBackSta_LH 4;
BA_ "Version" SG_ 733 CMSFldReq "21.08.01";
BA_ "RoutingFactor" SG_ 733 CMSFldReq 0;
BA_ "NetworkRequestHoldingTime" SG_ 733 CMSFldReq 5;
BA_ "NetworkRequest" SG_ 733 CMSFldReq 0;
BA_ "UserSigValidity" SG_ 733 CMSFldReq 0;
BA_ "GenSigSendType" SG_ 733 CMSFldReq 4;
BA_ "Version" SG_ 733 CMS_LH_FoldingSta "21.08.01";
BA_ "RoutingFactor" SG_ 733 CMS_LH_FoldingSta 0;
BA_ "NetworkRequestHoldingTime" SG_ 733 CMS_LH_FoldingSta 5000;
BA_ "NetworkRequest" SG_ 733 CMS_LH_FoldingSta 0;
BA_ "UserSigValidity" SG_ 733 CMS_LH_FoldingSta 0;
BA_ "GenSigSendType" SG_ 733 CMS_LH_FoldingSta 4;
BA_ "Version" SG_ 733 CMS_LH_UnfoldingSta "21.08.01";
BA_ "RoutingFactor" SG_ 733 CMS_LH_UnfoldingSta 0;
BA_ "NetworkRequestHoldingTime" SG_ 733 CMS_LH_UnfoldingSta 5000;
BA_ "NetworkRequest" SG_ 733 CMS_LH_UnfoldingSta 0;
BA_ "UserSigValidity" SG_ 733 CMS_LH_UnfoldingSta 0;
BA_ "GenSigSendType" SG_ 733 CMS_LH_UnfoldingSta 4;
BA_ "Version" SG_ 733 CMS_LHVerPosVal "21.08.01";
BA_ "RoutingFactor" SG_ 733 CMS_LHVerPosVal 0;
BA_ "NetworkRequestHoldingTime" SG_ 733 CMS_LHVerPosVal 5000;
BA_ "NetworkRequest" SG_ 733 CMS_LHVerPosVal 0;
BA_ "UserSigValidity" SG_ 733 CMS_LHVerPosVal 0;
BA_ "GenSigSendType" SG_ 733 CMS_LHVerPosVal 4;
BA_ "Description" SG_ 733 CMS_LHVerPosVal "This signal indicates LH Outside Mirror Vertical Position Sensor Voltage";
BA_ "Version" SG_ 733 CMS_LHHorPosVal "21.08.01";
BA_ "RoutingFactor" SG_ 733 CMS_LHHorPosVal 0;
BA_ "NetworkRequestHoldingTime" SG_ 733 CMS_LHHorPosVal 5000;
BA_ "NetworkRequest" SG_ 733 CMS_LHHorPosVal 0;
BA_ "UserSigValidity" SG_ 733 CMS_LHHorPosVal 0;
BA_ "GenSigSendType" SG_ 733 CMS_LHHorPosVal 4;
BA_ "Description" SG_ 733 CMS_LHHorPosVal "This signal indicates LH Outside Mirror Horizontal Position Sensor Voltage";
BA_ "Version" SG_ 733 Monitor_ViewPanningCmd "21.08.01";
BA_ "RoutingFactor" SG_ 733 Monitor_ViewPanningCmd 0;
BA_ "NetworkRequestHoldingTime" SG_ 733 Monitor_ViewPanningCmd 5000;
BA_ "NetworkRequest" SG_ 733 Monitor_ViewPanningCmd 0;
BA_ "UserSigValidity" SG_ 733 Monitor_ViewPanningCmd 0;
BA_ "GenSigSendType" SG_ 733 Monitor_ViewPanningCmd 4;
BA_ "Version" SG_ 721 HU_DR_Position_Status "22.07.05";
BA_ "RoutingFactor" SG_ 721 HU_DR_Position_Status 0;
BA_ "UserSigValidity" SG_ 721 HU_DR_Position_Status 1;
BA_ "Description" SG_ 721 HU_DR_Position_Status "0x1:Valid";
BA_ "Version" SG_ 721 HU_DR_Altitude_Status "22.07.05";
BA_ "RoutingFactor" SG_ 721 HU_DR_Altitude_Status 0;
BA_ "UserSigValidity" SG_ 721 HU_DR_Altitude_Status 1;
BA_ "Description" SG_ 721 HU_DR_Altitude_Status "0x1=Valid";
BA_ "Version" SG_ 721 HU_DR_Altitude "22.07.05";
BA_ "RoutingFactor" SG_ 721 HU_DR_Altitude 0;
BA_ "UserSigValidity" SG_ 721 HU_DR_Altitude 1;
BA_ "Description" SG_ 721 HU_DR_Altitude "MSL";
BA_ "Version" SG_ 721 HU_DR_Heading_Status "22.07.05";
BA_ "RoutingFactor" SG_ 721 HU_DR_Heading_Status 0;
BA_ "UserSigValidity" SG_ 721 HU_DR_Heading_Status 1;
BA_ "Description" SG_ 721 HU_DR_Heading_Status "0x1=Valid";
BA_ "Version" SG_ 721 HU_DR_Speed_Status "22.07.05";
BA_ "RoutingFactor" SG_ 721 HU_DR_Speed_Status 0;
BA_ "UserSigValidity" SG_ 721 HU_DR_Speed_Status 1;
BA_ "Description" SG_ 721 HU_DR_Speed_Status "0x1=Valid";
BA_ "Version" SG_ 721 HU_DR_DirectionSwitch_Sta "22.07.05";
BA_ "RoutingFactor" SG_ 721 HU_DR_DirectionSwitch_Sta 0;
BA_ "UserSigValidity" SG_ 721 HU_DR_DirectionSwitch_Sta 1;
BA_ "Description" SG_ 721 HU_DR_DirectionSwitch_Sta "0x1=valid";
BA_ "Version" SG_ 721 HU_DR_Direction "22.07.05";
BA_ "RoutingFactor" SG_ 721 HU_DR_Direction 0;
BA_ "UserSigValidity" SG_ 721 HU_DR_Direction 1;
BA_ "Description" SG_ 721 HU_DR_Direction "0x1=Backward";
BA_ "Version" SG_ 721 HU_DR_GyroCalib_Sta "22.07.05";
BA_ "RoutingFactor" SG_ 721 HU_DR_GyroCalib_Sta 0;
BA_ "UserSigValidity" SG_ 721 HU_DR_GyroCalib_Sta 1;
BA_ "Description" SG_ 721 HU_DR_GyroCalib_Sta "0x1=Calibrated";
BA_ "Version" SG_ 721 HU_DR_TachoCalib_Sta "22.07.05";
BA_ "RoutingFactor" SG_ 721 HU_DR_TachoCalib_Sta 0;
BA_ "UserSigValidity" SG_ 721 HU_DR_TachoCalib_Sta 1;
BA_ "Description" SG_ 721 HU_DR_TachoCalib_Sta "0x1=Calibrated";
BA_ "Version" SG_ 721 HU_DR_Solution_Sta "22.07.05";
BA_ "RoutingFactor" SG_ 721 HU_DR_Solution_Sta 0;
BA_ "UserSigValidity" SG_ 721 HU_DR_Solution_Sta 1;
BA_ "Description" SG_ 721 HU_DR_Solution_Sta "0x1 : Dr is fully calibrated and DR position is valid";
BA_ "Version" SG_ 721 HU_DR_GNSS_Fix_Age "22.07.05";
BA_ "RoutingFactor" SG_ 721 HU_DR_GNSS_Fix_Age 0;
BA_ "UserSigValidity" SG_ 721 HU_DR_GNSS_Fix_Age 1;
BA_ "Description" SG_ 721 HU_DR_GNSS_Fix_Age "0-254 = Time since last GNSS fix

255= No GNSS fix yet";
BA_ "Version" SG_ 722 HU_DR_Latitude "22.07.05";
BA_ "RoutingFactor" SG_ 722 HU_DR_Latitude 0;
BA_ "UserSigValidity" SG_ 722 HU_DR_Latitude 1;
BA_ "Version" SG_ 722 HU_DR_Longitude "22.07.05";
BA_ "RoutingFactor" SG_ 722 HU_DR_Longitude 0;
BA_ "UserSigValidity" SG_ 722 HU_DR_Longitude 1;
BA_ "Version" SG_ 723 HU_DR_Heading "22.07.05";
BA_ "RoutingFactor" SG_ 723 HU_DR_Heading 0;
BA_ "UserSigValidity" SG_ 723 HU_DR_Heading 1;
BA_ "Version" SG_ 723 HU_DR_Speed "22.07.05";
BA_ "RoutingFactor" SG_ 723 HU_DR_Speed 0;
BA_ "UserSigValidity" SG_ 723 HU_DR_Speed 1;
BA_ "Description" SG_ 723 HU_DR_Speed "negative if the direction is backward.";
BA_ "Version" SG_ 1915 RARS_GST_Byte0 "22.07.01";
BA_ "NetworkRequestHoldingTime" SG_ 1915 RARS_GST_Byte0 5000;
BA_ "NetworkRequest" SG_ 1915 RARS_GST_Byte0 0;
BA_ "UserSigValidity" SG_ 1915 RARS_GST_Byte0 0;
BA_ "UsrSigPurpose" SG_ 1915 RARS_GST_Byte0 4;
BA_ "Description" SG_ 1915 RARS_GST_Byte0 "TP Index : 158";
BA_ "Version" SG_ 1915 RARS_GST_Byte2 "22.07.01";
BA_ "NetworkRequestHoldingTime" SG_ 1915 RARS_GST_Byte2 5000;
BA_ "NetworkRequest" SG_ 1915 RARS_GST_Byte2 0;
BA_ "UserSigValidity" SG_ 1915 RARS_GST_Byte2 0;
BA_ "UsrSigPurpose" SG_ 1915 RARS_GST_Byte2 4;
BA_ "Description" SG_ 1915 RARS_GST_Byte2 "TP Index : 158";
BA_ "Version" SG_ 1915 RARS_GST_Byte3 "22.07.01";
BA_ "NetworkRequestHoldingTime" SG_ 1915 RARS_GST_Byte3 5000;
BA_ "NetworkRequest" SG_ 1915 RARS_GST_Byte3 0;
BA_ "UserSigValidity" SG_ 1915 RARS_GST_Byte3 0;
BA_ "UsrSigPurpose" SG_ 1915 RARS_GST_Byte3 4;
BA_ "Description" SG_ 1915 RARS_GST_Byte3 "TP Index : 158";
BA_ "Version" SG_ 1915 RARS_GST_Byte4 "22.07.01";
BA_ "NetworkRequestHoldingTime" SG_ 1915 RARS_GST_Byte4 5000;
BA_ "NetworkRequest" SG_ 1915 RARS_GST_Byte4 0;
BA_ "UserSigValidity" SG_ 1915 RARS_GST_Byte4 0;
BA_ "UsrSigPurpose" SG_ 1915 RARS_GST_Byte4 4;
BA_ "Description" SG_ 1915 RARS_GST_Byte4 "TP Index : 158";
BA_ "Version" SG_ 1915 RARS_GST_Byte5 "22.07.01";
BA_ "NetworkRequestHoldingTime" SG_ 1915 RARS_GST_Byte5 5000;
BA_ "NetworkRequest" SG_ 1915 RARS_GST_Byte5 0;
BA_ "UserSigValidity" SG_ 1915 RARS_GST_Byte5 0;
BA_ "UsrSigPurpose" SG_ 1915 RARS_GST_Byte5 4;
BA_ "Description" SG_ 1915 RARS_GST_Byte5 "TP Index : 158";
BA_ "Version" SG_ 1915 RARS_GST_Byte6 "22.07.01";
BA_ "NetworkRequestHoldingTime" SG_ 1915 RARS_GST_Byte6 5000;
BA_ "NetworkRequest" SG_ 1915 RARS_GST_Byte6 0;
BA_ "UserSigValidity" SG_ 1915 RARS_GST_Byte6 0;
BA_ "UsrSigPurpose" SG_ 1915 RARS_GST_Byte6 4;
BA_ "Description" SG_ 1915 RARS_GST_Byte6 "TP Index : 158";
BA_ "Version" SG_ 1915 RARS_GST_Byte7 "22.07.01";
BA_ "NetworkRequestHoldingTime" SG_ 1915 RARS_GST_Byte7 5000;
BA_ "NetworkRequest" SG_ 1915 RARS_GST_Byte7 0;
BA_ "UserSigValidity" SG_ 1915 RARS_GST_Byte7 0;
BA_ "UsrSigPurpose" SG_ 1915 RARS_GST_Byte7 4;
BA_ "Description" SG_ 1915 RARS_GST_Byte7 "TP Index : 158";
BA_ "Version" SG_ 1915 RARS_GST_Byte1 "22.07.01";
BA_ "NetworkRequestHoldingTime" SG_ 1915 RARS_GST_Byte1 5000;
BA_ "NetworkRequest" SG_ 1915 RARS_GST_Byte1 0;
BA_ "UserSigValidity" SG_ 1915 RARS_GST_Byte1 0;
BA_ "UsrSigPurpose" SG_ 1915 RARS_GST_Byte1 4;
BA_ "Description" SG_ 1915 RARS_GST_Byte1 "TP Index : 158";
BA_ "Version" SG_ 1914 RRMSS_MSS_RR_GST_Byte0 "23.11.01";
BA_ "UserSigValidity" SG_ 1914 RRMSS_MSS_RR_GST_Byte0 0;
BA_ "UsrSigPurpose" SG_ 1914 RRMSS_MSS_RR_GST_Byte0 4;
BA_ "Description" SG_ 1914 RRMSS_MSS_RR_GST_Byte0 "TP Index : 261";
BA_ "Version" SG_ 1914 RRMSS_MSS_RR_GST_Byte2 "23.11.01";
BA_ "UserSigValidity" SG_ 1914 RRMSS_MSS_RR_GST_Byte2 0;
BA_ "UsrSigPurpose" SG_ 1914 RRMSS_MSS_RR_GST_Byte2 4;
BA_ "Description" SG_ 1914 RRMSS_MSS_RR_GST_Byte2 "TP Index : 261";
BA_ "Version" SG_ 1914 RRMSS_MSS_RR_GST_Byte3 "23.11.01";
BA_ "UserSigValidity" SG_ 1914 RRMSS_MSS_RR_GST_Byte3 0;
BA_ "UsrSigPurpose" SG_ 1914 RRMSS_MSS_RR_GST_Byte3 4;
BA_ "Description" SG_ 1914 RRMSS_MSS_RR_GST_Byte3 "TP Index : 261";
BA_ "Version" SG_ 1914 RRMSS_MSS_RR_GST_Byte4 "23.11.01";
BA_ "UserSigValidity" SG_ 1914 RRMSS_MSS_RR_GST_Byte4 0;
BA_ "UsrSigPurpose" SG_ 1914 RRMSS_MSS_RR_GST_Byte4 4;
BA_ "Description" SG_ 1914 RRMSS_MSS_RR_GST_Byte4 "TP Index : 261";
BA_ "Version" SG_ 1914 RRMSS_MSS_RR_GST_Byte5 "23.11.01";
BA_ "UserSigValidity" SG_ 1914 RRMSS_MSS_RR_GST_Byte5 0;
BA_ "UsrSigPurpose" SG_ 1914 RRMSS_MSS_RR_GST_Byte5 4;
BA_ "Description" SG_ 1914 RRMSS_MSS_RR_GST_Byte5 "TP Index : 261";
BA_ "Version" SG_ 1914 RRMSS_MSS_RR_GST_Byte6 "23.11.01";
BA_ "UserSigValidity" SG_ 1914 RRMSS_MSS_RR_GST_Byte6 0;
BA_ "UsrSigPurpose" SG_ 1914 RRMSS_MSS_RR_GST_Byte6 4;
BA_ "Description" SG_ 1914 RRMSS_MSS_RR_GST_Byte6 "TP Index : 261";
BA_ "Version" SG_ 1914 RRMSS_MSS_RR_GST_Byte7 "23.11.01";
BA_ "UserSigValidity" SG_ 1914 RRMSS_MSS_RR_GST_Byte7 0;
BA_ "UsrSigPurpose" SG_ 1914 RRMSS_MSS_RR_GST_Byte7 4;
BA_ "Description" SG_ 1914 RRMSS_MSS_RR_GST_Byte7 "TP Index : 261";
BA_ "Version" SG_ 1914 RRMSS_MSS_RR_GST_Byte1 "23.11.01";
BA_ "UserSigValidity" SG_ 1914 RRMSS_MSS_RR_GST_Byte1 0;
BA_ "UsrSigPurpose" SG_ 1914 RRMSS_MSS_RR_GST_Byte1 4;
BA_ "Description" SG_ 1914 RRMSS_MSS_RR_GST_Byte1 "TP Index : 261";
BA_ "Version" SG_ 2307024132 HEV_RbmSta_2nd "19.10.00";
BA_ "RoutingFactor" SG_ 2307024132 HEV_RbmSta_2nd 2;
BA_ "UserSigValidity" SG_ 2307024132 HEV_RbmSta_2nd 3;
BA_ "Description" SG_ 2307024132 HEV_RbmSta_2nd "Status of rate-based monitoring



Value Description

Bit0 : cold start condition for PHEV

Bit1 : cold start inhibition condition for HEV/PHEV

Bit2 : reserved

Bit3 : reserved

Bit4 : reserved

Bit5 : reserved

Bit6 : reserved";
BA_ "Version" SG_ 2307024132 HEV_OilLifeRatio "20.12.04";
BA_ "RoutingFactor" SG_ 2307024132 HEV_OilLifeRatio 2;
BA_ "UserSigValidity" SG_ 2307024132 HEV_OilLifeRatio 3;
BA_ "Description" SG_ 2307024132 HEV_OilLifeRatio "EMS calculates remaining engine oil life, and Cluster displays this information with % unit, in order to guide driver to change engine oil.";
BA_ "Version" SG_ 2307024132 HEV_OilLifeEna "20.12.04";
BA_ "RoutingFactor" SG_ 2307024132 HEV_OilLifeEna 2;
BA_ "UserSigValidity" SG_ 2307024132 HEV_OilLifeEna 3;
BA_ "Description" SG_ 2307024132 HEV_OilLifeEna "Cluster displays engine oil life warning and life ratio signal if this enabling bit is true.";
BA_ "Version" SG_ 2307024132 HEV_OilLifeWarn "20.12.04";
BA_ "RoutingFactor" SG_ 2307024132 HEV_OilLifeWarn 2;
BA_ "UserSigValidity" SG_ 2307024132 HEV_OilLifeWarn 3;
BA_ "Description" SG_ 2307024132 HEV_OilLifeWarn "This signal indicates status of engine oil life warning.";
BA_ "Version" SG_ 2307024132 HEV_ExtSoakTimeVal "21.06.08";
BA_ "RoutingFactor" SG_ 2307024132 HEV_ExtSoakTimeVal 2;
BA_ "UserSigValidity" SG_ 2307024132 HEV_ExtSoakTimeVal 3;
BA_ "Description" SG_ 2307024132 HEV_ExtSoakTimeVal "The SoakTimeExt is the Additional soak time information, which start to increase from the moment that Soak Time is over 255 min.



Total Soak Time [min] = 1 * HEV_SoakTimeVal (EMS_08_100ms) [min] + 5 * HEV_ExtSoakTimeVal (EMS_08_100ms) [min]";
BA_ "Version" SG_ 2307024132 HEV_RECTrigSta "20.02.02";
BA_ "RoutingFactor" SG_ 2307024132 HEV_RECTrigSta 2;
BA_ "UserSigValidity" SG_ 2307024132 HEV_RECTrigSta 3;
BA_ "Description" SG_ 2307024132 HEV_RECTrigSta "Trigger signal(10 event) - when REC is occurred in the HEV ECU(Engine controller)";
BA_ "Version" SG_ 2307024132 HEV_PendingTrigSta "20.02.02";
BA_ "RoutingFactor" SG_ 2307024132 HEV_PendingTrigSta 2;
BA_ "UserSigValidity" SG_ 2307024132 HEV_PendingTrigSta 3;
BA_ "Description" SG_ 2307024132 HEV_PendingTrigSta "Trigger signal(10 event) - when Pending DTC is occurred in the HEV ECU(Engine controller)";
BA_ "Version" SG_ 1907 GST_RARS_Byte0 "21.02.04";
BA_ "NetworkRequestHoldingTime" SG_ 1907 GST_RARS_Byte0 5000;
BA_ "NetworkRequest" SG_ 1907 GST_RARS_Byte0 0;
BA_ "UserSigValidity" SG_ 1907 GST_RARS_Byte0 0;
BA_ "UsrSigPurpose" SG_ 1907 GST_RARS_Byte0 3;
BA_ "Description" SG_ 1907 GST_RARS_Byte0 "TP Index : 158";
BA_ "Version" SG_ 1907 GST_RARS_Byte2 "21.02.04";
BA_ "NetworkRequestHoldingTime" SG_ 1907 GST_RARS_Byte2 5000;
BA_ "NetworkRequest" SG_ 1907 GST_RARS_Byte2 0;
BA_ "UserSigValidity" SG_ 1907 GST_RARS_Byte2 0;
BA_ "UsrSigPurpose" SG_ 1907 GST_RARS_Byte2 3;
BA_ "Description" SG_ 1907 GST_RARS_Byte2 "TP Index : 158";
BA_ "Version" SG_ 1907 GST_RARS_Byte3 "21.02.04";
BA_ "NetworkRequestHoldingTime" SG_ 1907 GST_RARS_Byte3 5000;
BA_ "NetworkRequest" SG_ 1907 GST_RARS_Byte3 0;
BA_ "UserSigValidity" SG_ 1907 GST_RARS_Byte3 0;
BA_ "UsrSigPurpose" SG_ 1907 GST_RARS_Byte3 3;
BA_ "Description" SG_ 1907 GST_RARS_Byte3 "TP Index : 158";
BA_ "Version" SG_ 1907 GST_RARS_Byte4 "21.02.04";
BA_ "NetworkRequestHoldingTime" SG_ 1907 GST_RARS_Byte4 5000;
BA_ "NetworkRequest" SG_ 1907 GST_RARS_Byte4 0;
BA_ "UserSigValidity" SG_ 1907 GST_RARS_Byte4 0;
BA_ "UsrSigPurpose" SG_ 1907 GST_RARS_Byte4 3;
BA_ "Description" SG_ 1907 GST_RARS_Byte4 "TP Index : 158";
BA_ "Version" SG_ 1907 GST_RARS_Byte5 "21.02.04";
BA_ "NetworkRequestHoldingTime" SG_ 1907 GST_RARS_Byte5 5000;
BA_ "NetworkRequest" SG_ 1907 GST_RARS_Byte5 0;
BA_ "UserSigValidity" SG_ 1907 GST_RARS_Byte5 0;
BA_ "UsrSigPurpose" SG_ 1907 GST_RARS_Byte5 3;
BA_ "Description" SG_ 1907 GST_RARS_Byte5 "TP Index : 158";
BA_ "Version" SG_ 1907 GST_RARS_Byte6 "21.02.04";
BA_ "NetworkRequestHoldingTime" SG_ 1907 GST_RARS_Byte6 5000;
BA_ "NetworkRequest" SG_ 1907 GST_RARS_Byte6 0;
BA_ "UserSigValidity" SG_ 1907 GST_RARS_Byte6 0;
BA_ "UsrSigPurpose" SG_ 1907 GST_RARS_Byte6 3;
BA_ "Description" SG_ 1907 GST_RARS_Byte6 "TP Index : 158";
BA_ "Version" SG_ 1907 GST_RARS_Byte7 "21.02.04";
BA_ "NetworkRequestHoldingTime" SG_ 1907 GST_RARS_Byte7 5000;
BA_ "NetworkRequest" SG_ 1907 GST_RARS_Byte7 0;
BA_ "UserSigValidity" SG_ 1907 GST_RARS_Byte7 0;
BA_ "UsrSigPurpose" SG_ 1907 GST_RARS_Byte7 3;
BA_ "Description" SG_ 1907 GST_RARS_Byte7 "TP Index : 158";
BA_ "Version" SG_ 1907 GST_RARS_Byte1 "21.02.04";
BA_ "NetworkRequestHoldingTime" SG_ 1907 GST_RARS_Byte1 5000;
BA_ "NetworkRequest" SG_ 1907 GST_RARS_Byte1 0;
BA_ "UserSigValidity" SG_ 1907 GST_RARS_Byte1 0;
BA_ "UsrSigPurpose" SG_ 1907 GST_RARS_Byte1 3;
BA_ "Description" SG_ 1907 GST_RARS_Byte1 "TP Index : 158";
BA_ "Version" SG_ 830 USM_CmdWPC2Sta "22.02.06";
BA_ "NetworkRequestHoldingTime" SG_ 830 USM_CmdWPC2Sta 5000;
BA_ "NetworkRequest" SG_ 830 USM_CmdWPC2Sta 0;
BA_ "UserSigValidity" SG_ 830 USM_CmdWPC2Sta 0;
BA_ "GenSigSendType" SG_ 830 USM_CmdWPC2Sta 4;
BA_ "Description" SG_ 830 USM_CmdWPC2Sta "USM request value of WPC2";
BA_ "Version" SG_ 830 WPC2_OptSta "22.03.02";
BA_ "NetworkRequestHoldingTime" SG_ 830 WPC2_OptSta 5000;
BA_ "NetworkRequest" SG_ 830 WPC2_OptSta 0;
BA_ "UserSigValidity" SG_ 830 WPC2_OptSta 0;
BA_ "GenSigSendType" SG_ 830 WPC2_OptSta 4;
BA_ "Description" SG_ 830 WPC2_OptSta "Apply dual WPC information	2";
BA_ "Version" SG_ 830 WPC2_SWVerMajor1 "22.02.06";
BA_ "UserSigValidity" SG_ 830 WPC2_SWVerMajor1 0;
BA_ "GenSigSendType" SG_ 830 WPC2_SWVerMajor1 4;
BA_ "Description" SG_ 830 WPC2_SWVerMajor1 "Indicate the WPC2 software version as follows:

- The software version is displayed in three digits.

- The Major and Minor digits are separated by '.'

- Signal values are transmitted to ASCII codes.



¡Ø Example

WPC2_SWVerMajor1 : 0x41 (HEX) -> ASCII";
BA_ "Version" SG_ 830 WPC2_PhnLftWrngSta "24.01.00";
BA_ "NetworkRequestHoldingTime" SG_ 830 WPC2_PhnLftWrngSta 5000;
BA_ "NetworkRequest" SG_ 830 WPC2_PhnLftWrngSta 0;
BA_ "UserSigValidity" SG_ 830 WPC2_PhnLftWrngSta 0;
BA_ "GenSigSendType" SG_ 830 WPC2_PhnLftWrngSta 4;
BA_ "Description" SG_ 830 WPC2_PhnLftWrngSta "Warning by WPC2 for User (Phone left in vehicle)";
BA_ "Version" SG_ 830 WPC2_SWVerMinor1 "22.02.06";
BA_ "UserSigValidity" SG_ 830 WPC2_SWVerMinor1 0;
BA_ "GenSigSendType" SG_ 830 WPC2_SWVerMinor1 4;
BA_ "Description" SG_ 830 WPC2_SWVerMinor1 "Indicate the WPC2 software version as follows:

- The software version is displayed in three digits.

- The Major and Minor digits are separated by '.'

- Signal values are transmitted to ASCII codes.



¡Ø Example

WPC2_SWVerMajor1 : 0x41 (HEX) -> ASCII";
BA_ "Version" SG_ 830 WPC2_SWVerMinor2 "22.02.06";
BA_ "UserSigValidity" SG_ 830 WPC2_SWVerMinor2 0;
BA_ "GenSigSendType" SG_ 830 WPC2_SWVerMinor2 4;
BA_ "Description" SG_ 830 WPC2_SWVerMinor2 "Indicate the WPC2 software version as follows:

- The software version is displayed in three digits.

- The Major and Minor digits are separated by '.'

- Signal values are transmitted to ASCII codes.



¡Ø Example

WPC2_SWVerMajor1 : 0x41 (HEX) -> ASCII";
BA_ "Version" SG_ 830 WPC2_IndSyncVal "22.04.01";
BA_ "UserSigValidity" SG_ 830 WPC2_IndSyncVal 3;
BA_ "TimeoutValue" SG_ 830 WPC2_IndSyncVal "0x0";
BA_ "GenSigSendType" SG_ 830 WPC2_IndSyncVal 4;
BA_ "Description" SG_ 830 WPC2_IndSyncVal "WPC IND ANIMATION SYNC SIGNAL";
BA_ "Version" SG_ 830 WPC2_ResetOpSta "24.05.01";
BA_ "UserSigValidity" SG_ 830 WPC2_ResetOpSta 0;
BA_ "GenSigSendType" SG_ 830 WPC2_ResetOpSta 4;
BA_ "Description" SG_ 830 WPC2_ResetOpSta "This signal indicates whether the reset operation has been completed or not";
BA_ "Version" SG_ 1906 GST_RRMSS_MSS_RR_Byte0 "23.11.01";
BA_ "NetworkRequestHoldingTime" SG_ 1906 GST_RRMSS_MSS_RR_Byte0 5000;
BA_ "NetworkRequest" SG_ 1906 GST_RRMSS_MSS_RR_Byte0 0;
BA_ "UserSigValidity" SG_ 1906 GST_RRMSS_MSS_RR_Byte0 0;
BA_ "UsrSigPurpose" SG_ 1906 GST_RRMSS_MSS_RR_Byte0 3;
BA_ "Description" SG_ 1906 GST_RRMSS_MSS_RR_Byte0 "TP Index : 261";
BA_ "Version" SG_ 1906 GST_RRMSS_MSS_RR_Byte2 "23.11.01";
BA_ "NetworkRequestHoldingTime" SG_ 1906 GST_RRMSS_MSS_RR_Byte2 5000;
BA_ "NetworkRequest" SG_ 1906 GST_RRMSS_MSS_RR_Byte2 0;
BA_ "UserSigValidity" SG_ 1906 GST_RRMSS_MSS_RR_Byte2 0;
BA_ "UsrSigPurpose" SG_ 1906 GST_RRMSS_MSS_RR_Byte2 3;
BA_ "Description" SG_ 1906 GST_RRMSS_MSS_RR_Byte2 "TP Index : 261";
BA_ "Version" SG_ 1906 GST_RRMSS_MSS_RR_Byte3 "23.11.01";
BA_ "NetworkRequestHoldingTime" SG_ 1906 GST_RRMSS_MSS_RR_Byte3 5000;
BA_ "NetworkRequest" SG_ 1906 GST_RRMSS_MSS_RR_Byte3 0;
BA_ "UserSigValidity" SG_ 1906 GST_RRMSS_MSS_RR_Byte3 0;
BA_ "UsrSigPurpose" SG_ 1906 GST_RRMSS_MSS_RR_Byte3 3;
BA_ "Description" SG_ 1906 GST_RRMSS_MSS_RR_Byte3 "TP Index : 261";
BA_ "Version" SG_ 1906 GST_RRMSS_MSS_RR_Byte4 "23.11.01";
BA_ "NetworkRequestHoldingTime" SG_ 1906 GST_RRMSS_MSS_RR_Byte4 5000;
BA_ "NetworkRequest" SG_ 1906 GST_RRMSS_MSS_RR_Byte4 0;
BA_ "UserSigValidity" SG_ 1906 GST_RRMSS_MSS_RR_Byte4 0;
BA_ "UsrSigPurpose" SG_ 1906 GST_RRMSS_MSS_RR_Byte4 3;
BA_ "Description" SG_ 1906 GST_RRMSS_MSS_RR_Byte4 "TP Index : 261";
BA_ "Version" SG_ 1906 GST_RRMSS_MSS_RR_Byte5 "23.11.01";
BA_ "NetworkRequestHoldingTime" SG_ 1906 GST_RRMSS_MSS_RR_Byte5 5000;
BA_ "NetworkRequest" SG_ 1906 GST_RRMSS_MSS_RR_Byte5 0;
BA_ "UserSigValidity" SG_ 1906 GST_RRMSS_MSS_RR_Byte5 0;
BA_ "UsrSigPurpose" SG_ 1906 GST_RRMSS_MSS_RR_Byte5 3;
BA_ "Description" SG_ 1906 GST_RRMSS_MSS_RR_Byte5 "TP Index : 261";
BA_ "Version" SG_ 1906 GST_RRMSS_MSS_RR_Byte6 "23.11.01";
BA_ "NetworkRequestHoldingTime" SG_ 1906 GST_RRMSS_MSS_RR_Byte6 5000;
BA_ "NetworkRequest" SG_ 1906 GST_RRMSS_MSS_RR_Byte6 0;
BA_ "UserSigValidity" SG_ 1906 GST_RRMSS_MSS_RR_Byte6 0;
BA_ "UsrSigPurpose" SG_ 1906 GST_RRMSS_MSS_RR_Byte6 3;
BA_ "Description" SG_ 1906 GST_RRMSS_MSS_RR_Byte6 "TP Index : 261";
BA_ "Version" SG_ 1906 GST_RRMSS_MSS_RR_Byte7 "23.11.01";
BA_ "NetworkRequestHoldingTime" SG_ 1906 GST_RRMSS_MSS_RR_Byte7 5000;
BA_ "NetworkRequest" SG_ 1906 GST_RRMSS_MSS_RR_Byte7 0;
BA_ "UserSigValidity" SG_ 1906 GST_RRMSS_MSS_RR_Byte7 0;
BA_ "UsrSigPurpose" SG_ 1906 GST_RRMSS_MSS_RR_Byte7 3;
BA_ "Description" SG_ 1906 GST_RRMSS_MSS_RR_Byte7 "TP Index : 261";
BA_ "Version" SG_ 1906 GST_RRMSS_MSS_RR_Byte1 "23.11.01";
BA_ "NetworkRequestHoldingTime" SG_ 1906 GST_RRMSS_MSS_RR_Byte1 5000;
BA_ "NetworkRequest" SG_ 1906 GST_RRMSS_MSS_RR_Byte1 0;
BA_ "UserSigValidity" SG_ 1906 GST_RRMSS_MSS_RR_Byte1 0;
BA_ "UsrSigPurpose" SG_ 1906 GST_RRMSS_MSS_RR_Byte1 3;
BA_ "Description" SG_ 1906 GST_RRMSS_MSS_RR_Byte1 "TP Index : 261";
BA_ "Version" SG_ 2307024130 HEV_IgnCycCntVal "17.11.00";
BA_ "RoutingFactor" SG_ 2307024130 HEV_IgnCycCntVal 2;
BA_ "UserSigValidity" SG_ 2307024130 HEV_IgnCycCntVal 3;
BA_ "Description" SG_ 2307024130 HEV_IgnCycCntVal "Number of driving cycle since first ECU power-up. The counter increases each time a driving cycle with engine running for a specified time duration is detected. This value is only initialized with 0 on saved RAM lost (or reprogramming).";
BA_ "Version" SG_ 2307024130 HEV_SoakTimeVal "17.11.00";
BA_ "RoutingFactor" SG_ 2307024130 HEV_SoakTimeVal 2;
BA_ "UserSigValidity" SG_ 2307024130 HEV_SoakTimeVal 3;
BA_ "Description" SG_ 2307024130 HEV_SoakTimeVal "Engine soaking time";
BA_ "Version" SG_ 2307024130 HEV_SoakTimeErrSta "19.11.11";
BA_ "RoutingFactor" SG_ 2307024130 HEV_SoakTimeErrSta 2;
BA_ "UserSigValidity" SG_ 2307024130 HEV_SoakTimeErrSta 3;
BA_ "Description" SG_ 2307024130 HEV_SoakTimeErrSta "If the HEV_SoakTimeErrSta = 1 then the engine is in fuel cut off state, i.e. e. no injection is applied.";
BA_ "Version" SG_ 2307024130 HEV_SoakTimeOvrSta "18.12.01";
BA_ "RoutingFactor" SG_ 2307024130 HEV_SoakTimeOvrSta 2;
BA_ "UserSigValidity" SG_ 2307024130 HEV_SoakTimeOvrSta 3;
BA_ "Version" SG_ 2307024130 HEV_FuelRunOutSta "17.11.00";
BA_ "RoutingFactor" SG_ 2307024130 HEV_FuelRunOutSta 2;
BA_ "UserSigValidity" SG_ 2307024130 HEV_FuelRunOutSta 3;
BA_ "Version" SG_ 2307024130 HEV_FuelRunOutDetSta "17.11.00";
BA_ "RoutingFactor" SG_ 2307024130 HEV_FuelRunOutDetSta 2;
BA_ "UserSigValidity" SG_ 2307024130 HEV_FuelRunOutDetSta 3;
BA_ "Version" SG_ 2307024130 HEV_FuelCnsmptSumVal "17.11.00";
BA_ "RoutingFactor" SG_ 2307024130 HEV_FuelCnsmptSumVal 2;
BA_ "UserSigValidity" SG_ 2307024130 HEV_FuelCnsmptSumVal 3;
BA_ "Description" SG_ 2307024130 HEV_FuelCnsmptSumVal "Fuel Comsumption summed";
BA_REL_ "GenSigTimeoutTime" BU_SG_REL_ RCM SG_ 2231452931 DATC_OutTempSnsrVal 1500;
BA_REL_ "GenSigTimeoutTime" BU_SG_REL_ ALBCU SG_ 2290230530 CLU_DrvngModSwSta 1500;
BA_REL_ "GenSigTimeoutTime" BU_SG_REL_ GW_DLBCU SG_ 2290230530 CLU_DrvngModSwSta 1500;
BA_REL_ "GenSigTimeoutTime" BU_SG_REL_ SWRC SG_ 2290230530 CLU_DrvngModSwSta 1500;
BA_REL_ "GenSigTimeoutTime" BU_SG_REL_ ALBCU SG_ 2290230530 CLU_TerrainModSwSta 1500;
BA_REL_ "GenSigTimeoutTime" BU_SG_REL_ ASAU SG_ 2290230530 CLU_TerrainModSwSta 1500;
BA_REL_ "GenSigTimeoutTime" BU_SG_REL_ DSAU SG_ 2290230530 CLU_TerrainModSwSta 1500;
BA_REL_ "GenSigTimeoutTime" BU_SG_REL_ GW_DLBCU SG_ 2290230530 CLU_TerrainModSwSta 1500;
BA_REL_ "GenSigTimeoutTime" BU_SG_REL_ SWRC SG_ 2290230530 CLU_TerrainModSwSta 1500;
BA_REL_ "GenSigTimeoutTime" BU_SG_REL_ FCS SG_ 2290230529 CLU_TerrainMainSwSta 1500;
BA_REL_ "GenSigTimeoutTime" BU_SG_REL_ SWRC SG_ 2290230529 CLU_TerrainMainSwSta 1500;
BA_REL_ "GenSigTimeoutTime" BU_SG_REL_ vDummy_HS_B SG_ 2315421697 CCU_AP_OTA_Crc1Val 1500;
BA_REL_ "GenSigTimeoutTime" BU_SG_REL_ vDummy_HS_B SG_ 2315421697 CCU_AP_OTA_AlvCnt1Val 1500;
BA_REL_ "GenSigTimeoutTime" BU_SG_REL_ WPC SG_ 2470763009 USM_WpcSetReq 0;
BA_REL_ "GenSigTimeoutTime" BU_SG_REL_ WPC2 SG_ 2470763009 USM_WpcSetReq 0;
BA_REL_ "GenSigTimeoutTime" BU_SG_REL_ WPC2 SG_ 2470763009 USM_Wpc2SetReq 0;
BA_REL_ "GenSigTimeoutTime" BU_SG_REL_ CGW_CCU SG_ 742 SGU_BlindOnOffSet 1500;
BA_REL_ "GenSigTimeoutTime" BU_SG_REL_ RCM SG_ 742 SGU_BlindOpenReq 1500;
BA_REL_ "GenSigTimeoutTime" BU_SG_REL_ CGW_CCU SG_ 742 SGU_Roof_OprLv 1500;
BA_REL_ "GenSigTimeoutTime" BU_SG_REL_ CGW_CCU SG_ 742 SGU_2ndLeftDoor_OprLv 1500;
BA_REL_ "GenSigTimeoutTime" BU_SG_REL_ CGW_CCU SG_ 742 SGU_2ndRightDoor_OprLv 1500;
BA_REL_ "GenSigTimeoutTime" BU_SG_REL_ CGW_CCU SG_ 742 SGU_3rdLeftDoor_OprLv 1500;
BA_REL_ "GenSigTimeoutTime" BU_SG_REL_ CGW_CCU SG_ 742 SGU_3rdRightDoor_OprLv 1500;
BA_REL_ "GenSigTimeoutTime" BU_SG_REL_ CGW_CCU SG_ 742 SGU_RearWindow_OprLv 1500;
BA_REL_ "GenSigTimeoutTime" BU_SG_REL_ CGW_CCU SG_ 742 SGU_OprLvVehicleSet 1500;
BA_REL_ "GenSigTimeoutTime" BU_SG_REL_ BLTN_CAM SG_ 763 Warn_HoodSwSta_SBCM 1500;
BA_REL_ "GenSigTimeoutTime" BU_SG_REL_ BLTN_CAM SG_ 763 Hood_TypeOption 1500;
BA_REL_ "GenSigTimeoutTime" BU_SG_REL_ GW_DPSU SG_ 761 IMS_OSMirPlayBackSta_RH 1500;
BA_REL_ "GenSigTimeoutTime" BU_SG_REL_ GW_DPSU SG_ 758 IMS_OSMirPlayBackSta_LH 1500;
BA_REL_ "GenSigTimeoutTime" BU_SG_REL_ SWRC SG_ 2344811010 xEV_SocDis 1500;
BA_REL_ "GenSigTimeoutTime" BU_SG_REL_ ALBCU SG_ 2344811009 xEV_MainRlyOnSta 1500;
BA_REL_ "GenSigTimeoutTime" BU_SG_REL_ GW_APSU SG_ 2344811009 xEV_MainRlyOnSta 1500;
BA_REL_ "GenSigTimeoutTime" BU_SG_REL_ GW_DLBCU SG_ 2344811009 xEV_MainRlyOnSta 1500;
BA_REL_ "GenSigTimeoutTime" BU_SG_REL_ GW_DPSU SG_ 2344811009 xEV_MainRlyOnSta 1500;
BA_REL_ "GenSigTimeoutTime" BU_SG_REL_ GW_RLPSU SG_ 2344811009 xEV_MainRlyOnSta 1500;
BA_REL_ "GenSigTimeoutTime" BU_SG_REL_ GW_RRPSU SG_ 2344811009 xEV_MainRlyOnSta 1500;
BA_REL_ "GenSigTimeoutTime" BU_SG_REL_ RLHV SG_ 2344811009 xEV_MainRlyOnSta 1500;
BA_REL_ "GenSigTimeoutTime" BU_SG_REL_ RRHV SG_ 2344811009 xEV_MainRlyOnSta 1500;
BA_REL_ "GenSigTimeoutTime" BU_SG_REL_ SHVU_FR SG_ 2344811009 xEV_MainRlyOnSta 1500;
BA_REL_ "GenSigTimeoutTime" BU_SG_REL_ SHVU_RR SG_ 2344811009 xEV_MainRlyOnSta 1500;
BA_REL_ "GenSigTimeoutTime" BU_SG_REL_ GW_DPSU SG_ 733 IMS_CMSPlayBackSta_LH 1500;
BA_REL_ "GenSigTimeoutTime" BU_SG_REL_ BLTN_CAM SG_ 721 HU_DR_Altitude 1500;
BA_REL_ "GenSigTimeoutTime" BU_SG_REL_ BLTN_CAM SG_ 722 HU_DR_Latitude 1500;
BA_REL_ "GenSigTimeoutTime" BU_SG_REL_ BLTN_CAM SG_ 722 HU_DR_Longitude 1500;
BA_REL_ "GenSigTimeoutTime" BU_SG_REL_ BLTN_CAM SG_ 723 HU_DR_Heading 1500;
BA_REL_ "GenSigTimeoutTime" BU_SG_REL_ CGW_CCU SG_ 1915 RARS_GST_Byte0 0;
BA_REL_ "GenSigTimeoutTime" BU_SG_REL_ CGW_CCU SG_ 1915 RARS_GST_Byte2 0;
BA_REL_ "GenSigTimeoutTime" BU_SG_REL_ CGW_CCU SG_ 1915 RARS_GST_Byte3 0;
BA_REL_ "GenSigTimeoutTime" BU_SG_REL_ CGW_CCU SG_ 1915 RARS_GST_Byte4 0;
BA_REL_ "GenSigTimeoutTime" BU_SG_REL_ CGW_CCU SG_ 1915 RARS_GST_Byte5 0;
BA_REL_ "GenSigTimeoutTime" BU_SG_REL_ CGW_CCU SG_ 1915 RARS_GST_Byte6 0;
BA_REL_ "GenSigTimeoutTime" BU_SG_REL_ CGW_CCU SG_ 1915 RARS_GST_Byte7 0;
BA_REL_ "GenSigTimeoutTime" BU_SG_REL_ CGW_CCU SG_ 1915 RARS_GST_Byte1 0;
BA_REL_ "GenSigTimeoutTime" BU_SG_REL_ CGW_CCU SG_ 1914 RRMSS_MSS_RR_GST_Byte0 0;
BA_REL_ "GenSigTimeoutTime" BU_SG_REL_ CGW_CCU SG_ 1914 RRMSS_MSS_RR_GST_Byte2 0;
BA_REL_ "GenSigTimeoutTime" BU_SG_REL_ CGW_CCU SG_ 1914 RRMSS_MSS_RR_GST_Byte3 0;
BA_REL_ "GenSigTimeoutTime" BU_SG_REL_ CGW_CCU SG_ 1914 RRMSS_MSS_RR_GST_Byte4 0;
BA_REL_ "GenSigTimeoutTime" BU_SG_REL_ CGW_CCU SG_ 1914 RRMSS_MSS_RR_GST_Byte5 0;
BA_REL_ "GenSigTimeoutTime" BU_SG_REL_ CGW_CCU SG_ 1914 RRMSS_MSS_RR_GST_Byte6 0;
BA_REL_ "GenSigTimeoutTime" BU_SG_REL_ CGW_CCU SG_ 1914 RRMSS_MSS_RR_GST_Byte7 0;
BA_REL_ "GenSigTimeoutTime" BU_SG_REL_ CGW_CCU SG_ 1914 RRMSS_MSS_RR_GST_Byte1 0;
BA_REL_ "GenSigTimeoutTime" BU_SG_REL_ ARS SG_ 1907 GST_RARS_Byte0 0;
BA_REL_ "GenSigTimeoutTime" BU_SG_REL_ ARS SG_ 1907 GST_RARS_Byte2 0;
BA_REL_ "GenSigTimeoutTime" BU_SG_REL_ ARS SG_ 1907 GST_RARS_Byte3 0;
BA_REL_ "GenSigTimeoutTime" BU_SG_REL_ ARS SG_ 1907 GST_RARS_Byte4 0;
BA_REL_ "GenSigTimeoutTime" BU_SG_REL_ ARS SG_ 1907 GST_RARS_Byte5 0;
BA_REL_ "GenSigTimeoutTime" BU_SG_REL_ ARS SG_ 1907 GST_RARS_Byte6 0;
BA_REL_ "GenSigTimeoutTime" BU_SG_REL_ ARS SG_ 1907 GST_RARS_Byte7 0;
BA_REL_ "GenSigTimeoutTime" BU_SG_REL_ ARS SG_ 1907 GST_RARS_Byte1 0;
BA_REL_ "GenSigTimeoutTime" BU_SG_REL_ CGW_CCU SG_ 830 USM_CmdWPC2Sta 1500;
BA_REL_ "GenSigTimeoutTime" BU_SG_REL_ CGW_CCU SG_ 830 WPC2_OptSta 1500;
BA_REL_ "GenSigTimeoutTime" BU_SG_REL_ CGW_CCU SG_ 830 WPC2_SWVerMajor1 1500;
BA_REL_ "GenSigTimeoutTime" BU_SG_REL_ CGW_CCU SG_ 830 WPC2_PhnLftWrngSta 1500;
BA_REL_ "GenSigTimeoutTime" BU_SG_REL_ CGW_CCU SG_ 830 WPC2_SWVerMinor1 1500;
BA_REL_ "GenSigTimeoutTime" BU_SG_REL_ CGW_CCU SG_ 830 WPC2_SWVerMinor2 1500;
BA_REL_ "GenSigTimeoutTime" BU_SG_REL_ RWPC SG_ 830 WPC2_IndSyncVal 1500;
BA_REL_ "GenSigTimeoutTime" BU_SG_REL_ WPC SG_ 830 WPC2_IndSyncVal 1500;
BA_REL_ "GenSigTimeoutTime" BU_SG_REL_ GW_RRPSU SG_ 1906 GST_RRMSS_MSS_RR_Byte0 0;
BA_REL_ "GenSigTimeoutTime" BU_SG_REL_ GW_RRPSU SG_ 1906 GST_RRMSS_MSS_RR_Byte2 0;
BA_REL_ "GenSigTimeoutTime" BU_SG_REL_ GW_RRPSU SG_ 1906 GST_RRMSS_MSS_RR_Byte3 0;
BA_REL_ "GenSigTimeoutTime" BU_SG_REL_ GW_RRPSU SG_ 1906 GST_RRMSS_MSS_RR_Byte4 0;
BA_REL_ "GenSigTimeoutTime" BU_SG_REL_ GW_RRPSU SG_ 1906 GST_RRMSS_MSS_RR_Byte5 0;
BA_REL_ "GenSigTimeoutTime" BU_SG_REL_ GW_RRPSU SG_ 1906 GST_RRMSS_MSS_RR_Byte6 0;
BA_REL_ "GenSigTimeoutTime" BU_SG_REL_ GW_RRPSU SG_ 1906 GST_RRMSS_MSS_RR_Byte7 0;
BA_REL_ "GenSigTimeoutTime" BU_SG_REL_ GW_RRPSU SG_ 1906 GST_RRMSS_MSS_RR_Byte1 0;
VAL_ 2172675331 IEB_DrvWhlSlipFlg_Frnt 0 "No slip occurred at the driving wheels" 1 "Slip occurred at the driving wheels" ;
VAL_ 2172675331 IEB_IndDriftMode 0 "Default" 1 "off" 2 "on" 3 "RESERVED" 4 "RESERVED" 5 "RESERVED" 6 "RESERVED" 7 "Invaild" ;
VAL_ 2172675331 IEB_TCS_Req 0 "TCS control is not active" 1 "TCS control is active by requested TORQUE based" 2 "TCS control is active by requested RPM based" 3 "Not used" ;
VAL_ 2172675331 IEB_RSC_Req 0 "RSC is not active" 1 "RSC is active" 2 "RESERVED" 3 "RESERVED" ;
VAL_ 2172675331 TCS_TqFlag_Frnt 0 "Positive" 1 "Negative" ;
VAL_ 2172675331 TCS_TqFlag_Rear 0 "Positive" 1 "Negative" ;
VAL_ 2172675331 RSC_TqFlag_Frnt 0 "Positive" 1 "Negative" ;
VAL_ 2172675331 RSC_TqFlag_Rear 0 "Positive" 1 "Negative" ;
VAL_ 2172675330 IEB_Sta 0 "Not Ready" 1 "Ready" 2 "Ready (Front only) & Not Ready(Rear)" 3 "Ready (Rear only) & Not Ready(Front)" ;
VAL_ 2172675330 IEB_SnsrFailSta 0 "Normal" 1 "Fail" 2 "Not used" 3 "Error Indicator" ;
VAL_ 2172675330 IEB_RbsWrngLmpSta 0 "RBS Warning Lamp OFF" 1 "RBS Warning Lamp ON" 2 "Not used" 3 "Error Indicator" ;
VAL_ 2172675330 IEB_AbsNGearReq 0 "Inactive" 1 "N Gear position Request Active" 2 "Not used" 3 "Error Indicator" ;
VAL_ 2172675330 IEB_EstBrkPdlValVldSta 0 "Invalid" 1 "Valid" 2 "Not used" 3 "Error Indicator" ;
VAL_ 2172675330 IEB_VacSysDfctvSta 0 "Vacuum pump NOT defective" 1 "Vacuum pump defective (failed)" 2 "Not used" 3 "Error Indicator" ;
VAL_ 2172675330 IEB_FRAmode_Req 0 "No Request" 1 "Inhibit Transition To 4WD" 2 "Request FRA mode" 3 "Not used" ;
VAL_ 2231452930 DATC_AcnECompOpSta 0 "E-Compressor Not-Operation" 1 "E-Compressor Operation" 2 "Not used" 3 "Error Indicator" ;
VAL_ 2231452930 DATC_HVCompIntlkSta 0 "Disconnect" 1 "Connect" 2 "Not used" 3 "Error Indicator" ;
VAL_ 2231452930 DATC_HVIntDischrgLkReq 0 "Not Request" 1 "Request" 2 "Not used" 3 "Error Indicator" ;
VAL_ 2231452930 DATC_AcnECompMaxReqPwrVal 1023 "Error Indicator" ;
VAL_ 2231452930 DATC_AcnCompFltSta 0 "A/C E-Compressor Normal" 1 "A/C E-Compressor Fail" 2 "Not used" 3 "Error Indicator" ;
VAL_ 2231452930 DATC_AcnECompCnsmptPwrVal 1023 "Error Indicator" ;
VAL_ 2231452930 DATC_MainRlyOnOffReq 0 "Non-Request(Default)" 1 "OFF Request" 2 "ON Request" 3 "Error Indicator" ;
VAL_ 2231452930 DATC_MixDfgSelSta 0 "Battery FAN Non-on Request" 1 "Battery FAN On Request" 2 "Not used" 3 "Error Indicator" ;
VAL_ 2231452930 DATC_BattChlrVlvSta 0 "Dafault" 1 "OPEN" 2 "CLOSE" 3 "Error Indicator" ;
VAL_ 2231452930 DATC_WaterPmpOnReq 0 "Engine Water Pump Non request" 1 "Engine Water Pump On request" 2 "Not used" 3 "Error Indicator" ;
VAL_ 2231452930 DATC_AcnECompSpdVal 65534 "Not used" 65535 "Error Indicator" ;
VAL_ 2231452930 DATC_AcnCompSlpModCodVal 0 "Normal" 1 "Thermistor open" 2 "Thermister short" 4 "Over torque stall" 8 "Short circuit current" 16 "Driver voltage" 32 "Current measuring" 64 "Max Temperature Gradient" 128 "Internal Error" 255 "Error" ;
VAL_ 2231452931 DATC_AcnCompWaitCodVal 0 "Normal" 1 "Low_Voltage" 2 "High_Voltage" 4 "Over_Heat_Protection" 8 "Over_Loaded" 16 "Over_Current_Protection" 32 "Abnormal(not receiving)" 64 "Missed_Restart" ;
VAL_ 2231452931 DATC_RadFanReq_Duty 254 "EMS Wake Up Req" ;
VAL_ 2231452931 DATC_OutTempSnsrVal 0 "0x0x00~0xC8:-40¡É~60¡É" 200 "0x0x00~0xC8:-40¡É~60¡É" 201 "RESERVED" 202 "RESERVED" 203 "RESERVED" 204 "RESERVED" 205 "RESERVED" 206 "RESERVED" 207 "RESERVED" 208 "RESERVED" 209 "RESERVED" 210 "RESERVED" 211 "RESERVED" 212 "RESERVED" 213 "RESERVED" 214 "RESERVED" 215 "RESERVED" 216 "RESERVED" 217 "RESERVED" 218 "RESERVED" 219 "RESERVED" 220 "RESERVED" 221 "RESERVED" 222 "RESERVED" 223 "RESERVED" 224 "RESERVED" 225 "RESERVED" 226 "RESERVED" 227 "RESERVED" 228 "RESERVED" 229 "RESERVED" 230 "RESERVED" 231 "RESERVED" 232 "RESERVED" 233 "RESERVED" 234 "RESERVED" 235 "RESERVED" 236 "RESERVED" 237 "RESERVED" 238 "RESERVED" 239 "RESERVED" 240 "RESERVED" 241 "RESERVED" 242 "RESERVED" 243 "RESERVED" 244 "RESERVED" 245 "RESERVED" 246 "RESERVED" 247 "RESERVED" 248 "RESERVED" 249 "RESERVED" 250 "RESERVED" 251 "RESERVED" 252 "RESERVED" 253 "RESERVED" 254 "Default" 255 "Error Indicator" ;
VAL_ 2231452931 DATC_DfgSw 0 "FRONT DEF switch is not selected" 1 "FRONT DEF switch is selected" 2 "Not Used" 3 "Error Indicator" ;
VAL_ 2231452931 DATC_BattChlrVlv_FltCode 0 "Dafault" 1 "No Error" 2 "Error" 3 "Error Indicator" ;
VAL_ 2231452931 DATC_BattEvapVlvSta 0 "Default" 1 "Valve Off (OPEN)" 2 "Valve On (CLOSE)" 3 "Error Indicator" ;
VAL_ 2231452931 DATC_BattEvapVlv_FltCode 0 "Default" 1 "No Error" 2 "Error" 3 "Error Indicator" ;
VAL_ 2231452931 DATC_SSC_EngStrtReq 0 "Normal (Default)" 1 "Engine Auto Start Request" 2 "Reserved" 3 "Error Indicator" ;
VAL_ 2231452929 DATC_Crc1Val 0 "0x0x0~0xFFFF:CRCValue" 65535 "0x0x0~0xFFFF:CRCValue" ;
VAL_ 2231452929 DATC_AlvCnt1Val 0 "0x0x0~0xFF:AlvCntValue" 255 "0x0x0~0xFF:AlvCntValue" ;
VAL_ 2231452929 DATC_PtcRlySta 0 "PTC OFF" 1 "PTC ON Lv1" 2 "PTC ON Lv1&2" 3 "PTC ON Lv1&2&3" 4 "Not used" 5 "Not used" 6 "Not used" 7 "Error Indicator" ;
VAL_ 2231452929 DATC_ManufacturerTyp 0 "FATC Type 0 (default)" 1 "FATC Type 1 (Doowon)" 2 "FATC Type 2 (Hanon)/0X3:FATC Type 3(DENSO)" 4 "Not used" 5 "Not used" 6 "Not used" 7 "Error Indicator" ;
VAL_ 2231452929 DATC_AcnCompTyp 0 "Internal Compressor" 1 "External Compressor with Comp clutch" 2 "External Compressor without Comp clutch" 3 "Fixed Compressor" 4 "electrical Compressor" 6 "Not used" 7 "Error Indicator" ;
VAL_ 2231452929 DATC_Cooldown 0 "Default" 1 "Initial" 2 "Cool down" 3 "Error Indicator" ;
VAL_ 2231452929 DATC_AcnReq 0 "A/C Non-Request" 1 "A/C Request" 2 "Not used" 3 "Error Indicator" ;
VAL_ 2231452929 DATC_BlwSta 0 "Blower Off" 1 "Blower On" 2 "Not used" 3 "Error Indicator" ;
VAL_ 2231452929 DATC_BlwMaxSta 0 "NOT Max blower speed" 1 "Max blower speed" 2 "Not used" 3 "Error Indicator" ;
VAL_ 2231452929 DATC_EngStrtReq 0 "Engine Not on Request" 1 "Engine Auto Start Request" 2 "Not used" 3 "Error Indicator" ;
VAL_ 2231452929 DATC_IsgInhbtReq 0 "ISG Inhibit Request Off" 1 "ISG Inhibit Request ON" 2 "Not used" 3 "Error Indicator" ;
VAL_ 2231452929 DATC_AcnCompOnReq 0 "A/C COMP Request Off" 1 "A/C COMP Request ON" 2 "Not used" 3 "Error Indicator" ;
VAL_ 2231452929 DATC_SrvLmpReq 0 "Off" 1 "Service Lamp On" 2 "Not used" 3 "Error Indicator" ;
VAL_ 2231452929 DATC_EcvFltSta 0 "Normal(No fault)" 1 "ECV Control Fault" 2 "Not used" 3 "Error Indicator" ;
VAL_ 2231452929 DATC_CalcAcnCompTqVal 254 "Not used" 255 "Error Indicator" ;
VAL_ 2231452932 DATC_SSC_InhbtReq 0 "Normal (Default)" 1 "Inhibit Engine Stop" 2 "Reserved" 3 "Error Indicator" ;
VAL_ 2231452932 DATC_EngIdlRpmUpReq 0 "Off" 1 "A/C Off request" 2 "A/C On request" 3 "A/C On and Engine Speed 1 stage up request" 4 "A/C On and Engine Speed 2 stage up request" 5 "Warmup_Idle RPM_Up" 6 "Reserved" 7 "Error Indicator" ;
VAL_ 2231452932 DATC_MaxBlwVolt 0 "Default" 1 "OFF" 2 "ON (B+)" 3 "Error Indicator" ;
VAL_ 2231452932 DATC_MildCooldown 0 "Default" 1 "Initial State" 2 "Mild Cooldown" 3 "Error Indicator" ;
VAL_ 2231452932 DATC_BlwrLvl 0 "OFF" 1 "0 level" 2 "1 level" 3 "2 level" 4 "3 level" 5 "4 level" 6 "5 level" 7 "6 level" 8 "7 evel" 9 "8 level" 10 "Reserved" 11 "Reserved" 12 "Reserved" 13 "Reserved" 14 "Reserved" 15 "Error Indicator" ;
VAL_ 2231452932 DATC_AAFOpenReq 0 "Default" 1 "1 st" 2 "2 nd" 3 "Open" 4 "Reserved" 5 "Reserved" 6 "Reserved" 7 "Error indicator" ;
VAL_ 2231452932 DATC_BlwSta_Rr 0 "Blower Off(Default)" 1 "Blower On" 2 "RESERVED" 3 "Error Indicator" ;
VAL_ 2231452932 DATC_BattEwpOpReq 255 "Error Indicator" ;
VAL_ 2290230530 CLU_RefuelWrnSta 0 "Refuel Popup is off" 1 "Refuel Popup is on" 2 "Reserved" 3 "Invalid" ;
VAL_ 2290230530 CLU_DrvngModSwSta 0 "Off" 1 "Normal" 2 "Eco" 3 "Sport" 4 "Sport+" 5 "Smart" 6 "Custom(Custom#1_N)" 7 "N-mode(or GT mode)" 8 "RESERVED" 9 "Custom#2_N" 10 "RESERVED" 11 "MAGMA Sprint" 12 "MAGMA GT" 13 "RESERVED" 14 "RESERVED" 15 "Invalid" ;
VAL_ 2290230530 CLU_FuelLvlSta 0 "0x0x0~0x64:0%~100%" 100 "0x0x0~0x64:0%~100%" 101 "Reserved" 102 "Reserved" 103 "Reserved" 104 "Reserved" 105 "Reserved" 106 "Reserved" 107 "Reserved" 108 "Reserved" 109 "Reserved" 110 "Reserved" 111 "Reserved" 112 "Reserved" 113 "Reserved" 114 "Reserved" 115 "Reserved" 116 "Reserved" 117 "Reserved" 118 "Reserved" 119 "Reserved" 120 "Reserved" 121 "Reserved" 122 "Reserved" 123 "Reserved" 124 "Reserved" 125 "Reserved" 126 "Reserved" 127 "Invalid(Error)" ;
VAL_ 2290230530 CLU_SRSWrngLmpSta 0 "Lamp OFF" 1 "Lamp On" 2 "Lamp Flashing" 3 "ACU message error" 6 "Initialization" 7 "Lamp Circuit Failure" ;
VAL_ 2290230530 CLU_TerrainModSwSta 0 "Default" 1 "Snow" 2 "Sand" 3 "Mud" 4 "Auto" 5 "Deep Snow" 6 "Rock" 7 "RESERVED" ;
VAL_ 2290230530 CLU_OdoVal 16777215 "Error" ;
VAL_ 2290230529 CLU_Crc2Val 0 "0x0x0~0xFFFF:CRCValue" 65535 "0x0x0~0xFFFF:CRCValue" ;
VAL_ 2290230529 CLU_AlvCnt2Val 0 "0x0x0~0xFF:AlvCntValue" 255 "0x0x0~0xFF:AlvCntValue" ;
VAL_ 2290230529 CLU_DTEVal 0 "Valid DTE 0 (Display '---')" 1 "0x1~0xFFE:Valid DTE (1 ~ 4094 km)" 4094 "0x1~0xFFE:Valid DTE (1 ~ 4094 km)" 4095 "Invalid(Display '---' Blink)" ;
VAL_ 2290230529 CLU_TripUnitSta 0 "Not Used" 1 "km" 2 "mile" 3 "Invailid" ;
VAL_ 2290230529 CLU_LoFuelWrngSta 0 "Low fuel Warning is off" 1 "Low fuel Warning is on" 2 "Not used" 3 "Invalid" ;
VAL_ 2290230529 CLU_RefuelDetSta 0 "Non refuel detected" 1 "Refuel detected" 2 "Not used" 3 "Error Indicator" ;
VAL_ 2290230529 CLU_TerrainMainSwSta 0 "Default" 1 "On-Road" 2 "Off-Road" 3 "Reserved" ;
VAL_ 2315421697 CCU_AP_OTA_Crc1Val 0 "0x0x0~0xFFFF:CRCValue" 65535 "0x0x0~0xFFFF:CRCValue" ;
VAL_ 2315421697 CCU_AP_OTA_AlvCnt1Val 0 "0x0x0~0xFF:AlvCntValue" 255 "0x0x0~0xFF:AlvCntValue" ;
VAL_ 2315421697 CCU_OTA_mode 0 "idle" 1 "Download" 2 "BackgroundSend" 3 "UpdateReady_bf_apv" 4 "UpdateReady_af_apv" 5 "Update_preprocess" 6 "Update_PE" 7 "Update_other" ;
VAL_ 2315421697 CCU_OTA_IG3On_request 0 "off(Default)" 1 "on" 2 "Not used" 3 "Error Indicator" ;
VAL_ 2315421697 OTA_Cond_Vehicle_Pwr 0 "NoDisplay" 1 "OK" 2 "NOK" 3 "Reserved" ;
VAL_ 2315421697 OTA_Cond_Gear_P 0 "NoDisplay" 1 "OK" 2 "NOK" 3 "Reserved" ;
VAL_ 2315421697 OTA_Cond_Parking_Brk 0 "NoDisplay" 1 "OK" 2 "NOK" 3 "Reserved" ;
VAL_ 2315421697 OTA_Cond_Ext_Lamp 0 "NoDisplay" 1 "OK" 2 "NOK" 3 "Reserved" ;
VAL_ 2315421697 OTA_Cond_Hood_Closed 0 "NoDisplay" 1 "OK" 2 "NOK" 3 "Reserved" ;
VAL_ 2315421697 CCU_OTA_Cond_Request 0 "No Request" 1 "Request" 2 "Not Used" 3 "Error Indicator" ;
VAL_ 2315421697 CCU_OTA_Tele_Cranking 0 "default (off)" 1 "IGN1 on, Cranking" 2 "IGN1 on" 3 "Stop" 7 "Error Indicator" ;
VAL_ 2315421697 OTA_UI_Ready_request 0 "off (default)" 1 "ON" 2 "Not Used" 3 "Error Indicator" ;
VAL_ 2315421697 OTA_Result 0 "Default" 1 "Success" 2 "failed_rollback_complete" 3 "failed_rollback_failed" ;
VAL_ 2315421697 CF_AVN_InterAutoLockMode_Set2_Co 0 "Default" 1 "Auto Mode" 2 "Lock Mode" 3 "Unlock Mode" 4 "Reserved" 5 "Reserved" 6 "Reserved" 7 "Invalid" ;
VAL_ 2315421697 CCU_OTA_EOU 0 "OFF" 1 "ON" 2 "Reserved" 3 "Invalid" ;
VAL_ 2470763009 CLU_Crc9Val 0 "0x0x0~0xFFFF:CRCValue" 65535 "0x0x0~0xFFFF:CRCValue" ;
VAL_ 2470763009 CLU_AlvCnt9Val 0 "0x0x0~0xFF:AlvCntValue" 255 "0x0x0~0xFF:AlvCntValue" ;
VAL_ 2470763009 USM_MdLmpClrSetReq 0 "Default" 1 "color 1" 2 "color 2" 3 "color 3" 4 "color 4" 5 "color 5" 6 "color 6" 7 "color 7" 8 "color 8" 9 "color 9" 10 "color 10" 11 "reserved" 12 "reserved" 13 "reserved" 14 "reserved" 15 "Invalid" ;
VAL_ 2470763009 USM_RrWiperRevSetReq 0 "Default" 1 "Rear Wiper(reverse) Off" 2 "Rear Wiper(reverse) On" 3 "Invalid" ;
VAL_ 2470763009 USM_RrStRemindSetReq 0 "Default" 1 "Off(Disable)" 2 "On(Enable)" 3 "Invalid" ;
VAL_ 2470763009 USM_RrWpcSetReq 0 "Default" 1 "Off(Disable)" 2 "On(Enable)" 3 "Invalid" ;
VAL_ 2470763009 USM_WpcSetReq 0 "Default" 1 "Off(Disable)" 2 "On(Enable)" 3 "Invalid" ;
VAL_ 2470763009 USM_SeqLmpSetReq 0 "Default" 1 "Off" 2 "On" 3 "Invalid" ;
VAL_ 2470763009 USM_UnlckWlcmSetReq 0 "Default Value" 1 "Off" 2 "On" 3 "Invalid" ;
VAL_ 2470763009 USM_SmrtWlcmSetReq 0 "Default Value" 1 "Off" 2 "On" 3 "Invalid" ;
VAL_ 2470763009 USM_UipSetReq 0 "Default(USM¹Ì±¸¼º)" 1 "Off(Disable)" 2 "On(Enable)" 3 "Invalid" ;
VAL_ 2470763009 USM_DigitalKeyEnblSetReq 0 "Default(¹Ì±¸¼º)" 1 "Disable" 2 "Enable" 3 "Invalid" ;
VAL_ 2470763009 USM_OwnerPhnRegSetReq 0 "Default(¹Ì±¸¼º)" 1 "Deleter" 2 "Register" 3 "Invalid" ;
VAL_ 2470763009 USM_NFCCard1RegSetReq 0 "Default(¹Ì±¸¼º)" 1 "Disable" 2 "Enable" 3 "Invalid" ;
VAL_ 2470763009 USM_NFCCard2RegSetReq 0 "Default(¹Ì±¸¼º)" 1 "Disable" 2 "Enable" 3 "Invalid" ;
VAL_ 2470763009 USM_ProcStpReq 0 "Default" 1 "StopReq" ;
VAL_ 2470763009 USM_PwrAutoOffTimeSetReq 0 "Default" 1 "Timer1" 2 "Timer2" 3 "Timer3" 4 "Timer4" 5 "Reserved" 6 "Reserved" 7 "Invalid" ;
VAL_ 2470763009 USM_RrStRemindSetReq_RestMode 0 "Default" 1 "Off(Disable)" 2 "On(Enable)" 3 "Invalid" 4 "Reserved" 5 "Reserved" 6 "Not Used" 7 "Error Indicator" ;
VAL_ 2470763009 USM_1stRrStRemindSetReq 0 "Default" 1 "Off(Disable)" 2 "On(Enable)" 3 "Invalid" ;
VAL_ 2470763009 USM_Wpc2SetReq 0 "Default" 1 "Off(Disable)" 2 "On(Enable)" 3 "Invalid" ;
VAL_ 742 SGU_FltSta 0 "Normal" 1 "Fault" 2 "Not Used" 3 "Error Indicator" ;
VAL_ 742 SGU_BlindOnOffSet 0 "USM Activation" 1 "Off" 2 "On" 3 "Invalid" ;
VAL_ 742 SGU_BlindOpenReq 0 "Default" 1 "BlindOpen" 2 "Reserved" 3 "Invalid" ;
VAL_ 742 SGU_Roof_OprLv 0 "Default" 1 "OFF" 2 "Level 1" 3 "Level 2" 4 "Level 3" 5 "Reserved" 6 "Reserved" 7 "Invalid" ;
VAL_ 742 SGU_2ndLeftDoor_OprLv 0 "Default" 1 "Off" 2 "Level 1" 3 "Level 2" 4 "Level 3" 5 "Reserved" 6 "Reserved" 7 "Invalid" ;
VAL_ 742 SGU_2ndRightDoor_OprLv 0 "Default" 1 "Off" 2 "Level 1" 3 "Level 2" 4 "Level 3" 5 "Reserved" 6 "Reserved" 7 "Invalid" ;
VAL_ 742 SGU_3rdLeftDoor_OprLv 0 "Default" 1 "Off" 2 "Level 1" 3 "Level 2" 4 "Level 3" 5 "Reserved" 6 "Reserved" 7 "Invalid" ;
VAL_ 742 SGU_3rdRightDoor_OprLv 0 "Default" 1 "Off" 2 "Level 1" 3 "Level 2" 4 "Level 3" 5 "Reserved" 6 "Reserved" 7 "Invalid" ;
VAL_ 742 SGU_RearWindow_OprLv 0 "Default" 1 "Off" 2 "Level 1" 3 "Level 2" 4 "Level 3" 5 "Reserved" 6 "Reserved" 7 "Invalid" ;
VAL_ 742 SGU_OprLvVehicleSet 0 "Default" 1 "Reserved" 2 "Off & Level 1" 3 "Off & Level 1 ~ 2" 4 "Off & Level 1 ~ 3" 5 "Off & Level 1 ~ 4" 6 "Off & Level 1 ~ 5" 7 "Invalid" ;
VAL_ 742 SGU_RdySta 0 "Off" 1 "Ready" 2 "Sleep" 3 "Reserved" ;
VAL_ 763 SBCM_DRV_Crc3Val 0 "0x0x0~0xFF:CRCValue" 255 "0x0x0~0xFF:CRCValue" ;
VAL_ 763 CDM_TypeOption 0 "Off" 1 "On" 2 "On_2EA" 3 "Error Indicator" ;
VAL_ 763 SBCM_DRV_AlvCnt3Val 0 "AlvCntValue" 1 "AlvCntValue" 2 "AlvCntValue" 3 "AlvCntValue" 4 "AlvCntValue" 5 "AlvCntValue" 6 "AlvCntValue" 7 "AlvCntValue" 8 "AlvCntValue" 9 "AlvCntValue" 10 "AlvCntValue" 11 "AlvCntValue" 12 "AlvCntValue" 13 "AlvCntValue" 14 "AlvCntValue" 15 "AlvCntValue" ;
VAL_ 763 CDM_ImmeChgSw_SBCM 0 "Default" 1 "Off" 2 "On" 3 "RESERVED" ;
VAL_ 763 CDM_FobSrchReq_DRV 0 "Off" 1 "On" 2 "RESERVED" 3 "Error Indicator" ;
VAL_ 763 CDM_OpnClsState_SBCM 0 "Default" 1 "Open" 2 "Close" 3 "RESERVED" ;
VAL_ 763 CDM_WarnMsg_SBCM 0 "Default" 1 "Normal" 2 "ChargeDoorErrorState" 3 "RESERVED" ;
VAL_ 763 CDM_AutoWashModeSta 0 "Default" 1 "CDM Auto Wash Mode Off (Ready)" 2 "CDM Auto Wash Mode Off (Error)" 3 "CDM Auto Wash Mode On" 4 "RESERVED" 5 "RESERVED" 6 "RESERVED" 7 "Invalid" ;
VAL_ 763 CDM_CmdStatus_SBCM 0 "Open (AVN)" 1 "Open (SMK)" 2 "Open (Sensor Switch)" 3 "Open (Command Hard Switch)" 4 "Open (Anti - Pinch)" 5 "Close (AVN)" 6 "Close (SMK)" 7 "Close (Assist Mode)" 8 "Close (Command Hard Switch)" 9 "Close (Connector)" 10 "Close (Gear Position)" 11 "Close (Time Over)" 12 "Close (Anti - Pinch)" 13 "Close (Sensor Switch)" 14 "Stall (Stop)" 15 "Invalid" ;
VAL_ 763 CDM_OutsideOpnSwSta 0 "Default" 1 "Push" 2 "RESERVED" 3 "Invalid" ;
VAL_ 763 PwrDRBuzzerOut_DRV 0 "OFF" 1 "Open" 2 "Close" 3 "Warning" ;
VAL_ 763 Warn_HoodSwSta_SBCM 0 "Off" 1 "On" 2 "RESERVED" 3 "Error Indicator" ;
VAL_ 763 Hood_TypeOption 0 "Off (Mechanical hood latch is applied)" 1 "On (E-Hood latch is applied)" 2 "RESERVED" 3 "Error Indicator" ;
VAL_ 763 SBCM_FrunkSta 0 "Default" 1 "Valid" 2 "RESERVED" 3 "Error Indicator" ;
VAL_ 763 Warn_HoodSwFullSta_SBCM 0 "Off" 1 "On" 2 "RESERVED" 3 "Error Indicator" ;
VAL_ 763 FrunkWarning_SBCM 0 "Off" 1 "On" 2 "RESERVED" 3 "Error Indicator" ;
VAL_ 763 SBCM_Longkey_DRVDrAtClsSwSta 0 "Default" 1 "Off" 2 "On" 3 "Error Indicator" ;
VAL_ 763 PwrDRClosingDRVDrSta 0 "Default" 1 "Close" 2 "Open" 3 "Stop" 4 "RESERVED" 5 "RESERVED" 6 "RESERVED" 7 "Invalid" ;
VAL_ 763 Drv_DrLkRetryFail_SBCM 0 "Normal" 1 "Fail" 2 "RESERVED" 3 "RESERVED" ;
VAL_ 763 CDM_GbtImmeChgSw_SBCM 0 "Default" 1 "Off" 2 "On" 3 "RESERVED" ;
VAL_ 763 CDM_GbtOpnClsState_SBCM 0 "Default" 1 "Open" 2 "Close" 3 "RESERVED" ;
VAL_ 763 CDM_GbtWarnMsg_SBCM 0 "Default" 1 "Normal" 2 "ChargeDoorErrorState" 3 "RESERVED" ;
VAL_ 763 CDM_GbtOutsideOpnSwSta 0 "Default" 1 "Push" 2 "RESERVED" 3 "Invalid" ;
VAL_ 763 DoorLock_DrvLkOutSta_SBCM 0 "Off" 1 "On" 2 "Not Used" 3 "Error Indicator" ;
VAL_ 763 CDM_InsideOpnSwSta 0 "Off" 1 "On" 2 "RESERVED" 3 "Error Indicator" ;
VAL_ 761 SBCM_AST_Crc3Val 0 "0x0x0~0xFF:CRCValue" 255 "0x0x0~0xFF:CRCValue" ;
VAL_ 761 CDM_TypeOption_AST 0 "Off" 1 "On" 2 "On_2EA" 3 "Error Indicator" ;
VAL_ 761 SBCM_AST_AlvCnt3Val 0 "AlvCntValue" 1 "AlvCntValue" 2 "AlvCntValue" 3 "AlvCntValue" 4 "AlvCntValue" 5 "AlvCntValue" 6 "AlvCntValue" 7 "AlvCntValue" 8 "AlvCntValue" 9 "AlvCntValue" 10 "AlvCntValue" 11 "AlvCntValue" 12 "AlvCntValue" 13 "AlvCntValue" 14 "AlvCntValue" 15 "AlvCntValue" ;
VAL_ 761 CDM_ImmeChgSw_AST 0 "Default" 1 "Off" 2 "On" 3 "RESERVED" ;
VAL_ 761 CDM_FobSrchReq_AST 0 "Off" 1 "On" 2 "RESERVED" 3 "Error Indicator" ;
VAL_ 761 CDM_OpnClsState_AST 0 "Default" 1 "Open" 2 "Close" 3 "RESERVED" ;
VAL_ 761 CDM_WarnMsg_AST 0 "Default" 1 "Normal" 2 "ChargeDoorErrorState" 3 "RESERVED" ;
VAL_ 761 Mirror_RH_FoldingSta 0 "Off" 1 "Folding" 2 "RESERVED" 3 "Error Indicator" ;
VAL_ 761 Mirror_RH_UnfoldingSta 0 "Off" 1 "Unfolding" 2 "RESERVED" 3 "Error Indicator" ;
VAL_ 761 CDM_CmdStatus_AST 0 "Open (AVN)" 1 "Open (SMK)" 2 "Open (Sensor Switch)" 3 "Open (Command Hard Switch)" 4 "Open (Anti - Pinch)" 5 "Close (AVN)" 6 "Close (SMK)" 7 "Close (Assist Mode)" 8 "Close (Command Hard Switch)" 9 "Close (Connector)" 10 "Close (Gear Position)" 11 "Close (Time Over)" 12 "Close (Anti - Pinch)" 13 "Close (Sensor Switch)" 14 "Stall (Stop)" 15 "Invalid" ;
VAL_ 761 AST_CrashMRActAlarm 0 "Off" 1 "On" 2 "RESERVED" 3 "Error Indicator" ;
VAL_ 761 PwrDRBuzzerOut_AST 0 "OFF" 1 "Open" 2 "Close" 3 "Warning" ;
VAL_ 761 IMS_OSMirPlayBackSta_RH 0 "Stop" 1 "Play 1" 2 "Play 2" 3 "Play 3" 4 "Smart IMS" 5 "Profile 1" 6 "Profile 2" 7 "Guest" 8 "RESERVED" 9 "RESERVED" 10 "RESERVED" 11 "RESERVED" 12 "RESERVED" 13 "RESERVED" 14 "RESERVED" 15 "Error Indicator" ;
VAL_ 761 PwrDRClosingASTDrSta 0 "Default" 1 "Close" 2 "Open" 3 "Stop" 4 "RESERVED" 5 "RESERVED" 6 "RESERVED" 7 "Invalid" ;
VAL_ 761 CDM_OutsideOpnSwSta_AST 0 "Default" 1 "Push" 2 "RESERVED" 3 "Invalid" ;
VAL_ 761 SBCM_Longkey_ASTDrAtClsSwSta 0 "Default" 1 "Off" 2 "On" 3 "Error Indicator" ;
VAL_ 761 Hood_TypeOption_AST 0 "Off (Mechanical hood latch is applied)" 1 "On (E-Hood latch is applied)" 2 "RESERVED" 3 "Error Indicator" ;
VAL_ 761 Warn_HoodSwSta_AST 0 "Off" 1 "On" 2 "RESERVED" 3 "Error Indicator" ;
VAL_ 761 FrunkWarning_AST 0 "Off" 1 "On" 2 "RESERVED" 3 "Error Indicator" ;
VAL_ 761 SBCM_FrunkSta_AST 0 "Default" 1 "Valid" 2 "RESERVED" 3 "Error Indicator" ;
VAL_ 761 Ast_DrLkRetryFail_SBCM 0 "Normal" 1 "Fail" 2 "RESERVED" 3 "RESERVED" ;
VAL_ 761 DoorLock_AstLkOutSta_SBCM 0 "Off" 1 "On" 2 "Not Used" 3 "Error Indicator" ;
VAL_ 761 SBCM_AST_DiagSta 0 "Default" 1 "Normal Operation" 2 "AST Indicator Circuit Failure" 3 "RESERVED" ;
VAL_ 758 SBCM_DRV_Crc2Val 0 "0x0x0~0xFF:CRCValue" 255 "0x0x0~0xFF:CRCValue" ;
VAL_ 758 DoorLock_CtrlDrLkUnLkSwSta_SBCM 0 "Off" 1 "On" 2 "RESERVED" 3 "Error Indicator" ;
VAL_ 758 SBCM_DRV_AlvCnt2Val 0 "AlvCntValue" 1 "AlvCntValue" 2 "AlvCntValue" 3 "AlvCntValue" 4 "AlvCntValue" 5 "AlvCntValue" 6 "AlvCntValue" 7 "AlvCntValue" 8 "AlvCntValue" 9 "AlvCntValue" 10 "AlvCntValue" 11 "AlvCntValue" 12 "AlvCntValue" 13 "AlvCntValue" 14 "AlvCntValue" 15 "AlvCntValue" ;
VAL_ 758 SBCM_PsvDrLkReq 0 "None" 1 "Lock" 2 "Passive Trunk Lock" 3 "RESERVED" ;
VAL_ 758 CDMAutoWashModeSet_SBCM 0 "Default" 1 "CDM Auto Wash Mode Off" 2 "CDM Auto Wash Mode On" 3 "RESERVED" 4 "RESERVED" 5 "RESERVED" 6 "RESERVED" 7 "Invalid" ;
VAL_ 758 USM_DrvGhostDoorSta 0 "Default" 1 "Off" 2 "On" 3 "RESERVED" ;
VAL_ 758 Mirror_LH_FoldingSta 0 "Off" 1 "Folding" 2 "RESERVED" 3 "Error Indicator" ;
VAL_ 758 Mirror_LH_UnfoldingSta 0 "Off" 1 "Unfolding" 2 "RESERVED" 3 "Error Indicator" ;
VAL_ 758 DRV_CrashMRActAlarm 0 "Off" 1 "On" 2 "RESERVED" 3 "Error Indicator" ;
VAL_ 758 MirrorFldReq 0 "Default" 1 "Folding Request" 2 "Unfolding Request" 3 "RESERVED" ;
VAL_ 758 OMU_TypeOption_DRV 0 "Off" 1 "On" 2 "RESERVED" 3 "Error Indicator" ;
VAL_ 758 IMS_OSMirPlayBackSta_LH 0 "Stop" 1 "Play 1" 2 "Play 2" 3 "Play 3" 4 "SmartIMS" 5 "Profile 1" 6 "Profile 2" 7 "Guest" 8 "RESERVED" 9 "RESERVED" 10 "RESERVED" 11 "RESERVED" 12 "RESERVED" 13 "RESERVED" 14 "RESERVED" 15 "Error Indicator" ;
VAL_ 758 ECMMRR_PLUS 0 "0x0x0~0x7D:0~1.25 V" 125 "0x0x0~0x7D:0~1.25 V" 126 "0x7E~0xFE:RESERVED" 254 "0x7E~0xFE:RESERVED" 255 "RESERVED" ;
VAL_ 758 SBCM_DRV_DiagSta 0 "Default" 1 "Normal Operation" 2 "DRV Indicator Circuit Failure" 3 "RESERVED" ;
VAL_ 2344811012 xEV_Bms_IsolDetDeactFuncSta 0 "Function disabled state" 1 "Functional activated state" 2 "Not used" 3 "Error indicator" ;
VAL_ 2344811012 xEV_Bms_CellBalDeactFuncSta 0 "Function disabled state" 1 "Functional activated state" 2 "Not used" 3 "Error indicator" ;
VAL_ 2344811012 EV_HiddenSOC_ChangeReq 0 "default" 1 "A to B Change" 2 "B to A Change" 3 "Not Used" ;
VAL_ 2344811012 xEV_BMS_SOC_2nd 65535 "Error Value" ;
VAL_ 2344811011 xEV_12VAlarmReqForICU 0 "Normal" 1 "3rd cut off" 2 "Warn. msg & 3rd cut off req" 3 "reserved" ;
VAL_ 2344811011 xEV_AuxBattChrgReq 0 "Charge Finish Request" 1 "LV2 Charge Request" 2 "LV1 Charge Request" 3 "Error Indicator" ;
VAL_ 2344811011 xEV_12VDarkCurrAlarmForICU 0 "Normal" 1 "Alarm Flag set" 2 "Not used" 3 "Error indicator" ;
VAL_ 2344811011 xEV_12VBatVLmt 255 "Error indicator" ;
VAL_ 2344811011 xEV_CharBatInfoReqForSDC 0 "Default(no request)" 1 "High volt bat. First" 2 "12 volt bat. First" 3 "Both of them possible" ;
VAL_ 2344811011 xEV_ClimateOffReq 0 "Default" 1 "Flag set" 2 "Not used" 3 "Error indicator" ;
VAL_ 2344811011 xEV_MainRlyOnRetrySta 0 "Normal" 1 "Relay ON Retry Operation" 2 "Not used" 3 "Error indicator" ;
VAL_ 2344811011 xEV_Bms_BlackBox_Data_req 0 "Default" 1 "Data Save Req (Isolation)" 2 "Data Set Clear" 3 "Error Indicator" ;
VAL_ 2344811011 xEV_12V_BatDchCurrLmt 255 "Error indicator" ;
VAL_ 2344811011 xEV_12VChargeReq 0 "Not Request(Normal)" 1 "Request" 2 "Not used" 3 "Error indicator" ;
VAL_ 2344811011 xEV_BmsRomType 0 "No Definition" 1 "Normal Battery Pack with Heater System" 2 "Normal Battery Pack without Heater System" 3 "Economy Battery Pack with Heater System" 4 "Economy Battery Pack without Heater System" 5 "Extented Battery Pack with Heater System" 6 "Extented Battery Pack without Heater System" 7 "Performance Battery Pack (Heater or Non Heater)" ;
VAL_ 2344811011 xEV_12V_CurrFltDetectReq 0 "Normal" 1 "Request" 2 "Not used" 3 "Error indicator" ;
VAL_ 2344811011 xEV_PRATempSnsVal_ 127 "Error indicator" ;
VAL_ 2344811011 xEV_PRATempSns2Val_ 127 "Error indicator" ;
VAL_ 2344811011 xEV_12VRlyOnSwReq 0 "Normal" 1 "Request" 2 "Not used" 3 "Error indicator" ;
VAL_ 2344811010 xEV_BattCurrVal 32767 "Error indicator" ;
VAL_ 2344811010 xEV_MinBattTempVal 127 "Error indicator" ;
VAL_ 2344811010 xEV_MaxBattTempVal 127 "Error indicator" ;
VAL_ 2344811010 xEV_FanSpdStpSta 0 "None" 1 "1step" 2 "2step" 3 "3step" 4 "4step" 5 "5step" 6 "6step" 7 "7step" 8 "8step" 9 "9step" ;
VAL_ 2344811010 xEV_12VRlyOffAlrmReq 0 "Normal" 1 "Pop up Request" 2 "Not used" 3 "Error indicator" ;
VAL_ 2344811010 xEV_12VRlyOnAlrmReq 0 "Normal" 1 "Pop up Request" 2 "Not used" 3 "Error indicator" ;
VAL_ 2344811010 xEV_SocDis 255 "Error value" ;
VAL_ 2344811009 BMS_Crc2Val 0 "0x0x0~0xFFFF:CRCValue" 65535 "0x0x0~0xFFFF:CRCValue" ;
VAL_ 2344811009 BMS_AlvCnt2Val 0 "0x0x0~0xFF:AlvCntValue" 255 "0x0x0~0xFF:AlvCntValue" ;
VAL_ 2344811009 xEV_SrvLmpReq 0 "Off" 1 "Service Lamp On" 2 "Not used" 3 "Error indicator" ;
VAL_ 2344811009 xEV_MainRlyOnSta 0 "Open" 1 "Close" 2 "Not used" 3 "Error indicator" ;
VAL_ 2344811009 xEV_SysFltSta 0 "Normal" 1 "Fault" 2 "Not used" 3 "Error indicator" ;
VAL_ 2344811009 EV_Unreliable_SOC 0 "Normal" 1 "Warning(30%)" 2 "Warning(70%)" 3 "Fault(100%)" ;
VAL_ 2344811009 xEV_InltTempVal 127 "Error value" ;
VAL_ 2344811009 xEV_MinBattCelVoltVal 255 "Error indicator" ;
VAL_ 2344811009 xEV_MaxBattCelVoltVal 255 "Error indicator" ;
VAL_ 733 CMS_LH_Crc1Val 0 "0x0x0~0xFF:CRCValue" 255 "0x0x0~0xFF:CRCValue" ;
VAL_ 733 CMS_LH_AlvCnt1Val 0 "AlvCntValue" 1 "AlvCntValue" 2 "AlvCntValue" 3 "AlvCntValue" 4 "AlvCntValue" 5 "AlvCntValue" 6 "AlvCntValue" 7 "AlvCntValue" 8 "AlvCntValue" 9 "AlvCntValue" 10 "AlvCntValue" 11 "AlvCntValue" 12 "AlvCntValue" 13 "AlvCntValue" 14 "AlvCntValue" 15 "AlvCntValue" ;
VAL_ 733 USM_TurnDstLnDispSta 0 "Default" 1 "Off" 2 "On" 3 "RESERVED" ;
VAL_ 733 USM_TurnDstLnDispStaRH 0 "Default" 1 "Off" 2 "On" 3 "RESERVED" ;
VAL_ 733 USM_RhstaLvlEnaSta 0 "Default" 1 "Off" 2 "On" 3 "RESERVED" ;
VAL_ 733 USM_RhstaLvlEnaStaRH 0 "Default" 1 "Off" 2 "On" 3 "RESERVED" ;
VAL_ 733 USM_CMSDayBrgtnsLvlLHSta 0 "-5 Level" 1 "-4 Level" 2 "-3 Level" 3 "-2 Level" 4 "-1 Level" 5 "0 Level" 6 "1 Level" 7 "2 Level" 8 "3 Level" 9 "4 Level" 10 "5 Level" 11 "RESERVED" 12 "RESERVED" 13 "RESERVED" 14 "Error Indicator" 15 "RESERVED" ;
VAL_ 733 USM_CMSNgtBrgtnsLvlLHSta 0 "-5 Level" 1 "-4 Level" 2 "-3 Level" 3 "-2 Level" 4 "-1 Level" 5 "0 Level" 6 "1 Level" 7 "2 Level" 8 "3 Level" 9 "4 Level" 10 "5 Level" 11 "RESERVED" 12 "RESERVED" 13 "RESERVED" 14 "Error Indicator" 15 "RESERVED" ;
VAL_ 733 IMS_CMSPlayBackSta_LH 0 "Stop" 1 "Play 1" 2 "Play 2" 3 "Play 3" 4 "Smart IMS" 5 "Profile 1" 6 "Profile 2" 7 "Guest" 8 "RESERVED" 9 "RESERVED" 10 "RESERVED" 11 "RESERVED" 12 "RESERVED" 13 "RESERVED" 14 "RESERVED" 15 "Error Indicator" ;
VAL_ 733 CMSFldReq 0 "Default" 1 "Folding Request" 2 "Unfolding Request" 3 "RESERVED" ;
VAL_ 733 CMS_LH_FoldingSta 0 "Off" 1 "Folding" 2 "RESERVED" 3 "Error Indicator" ;
VAL_ 733 CMS_LH_UnfoldingSta 0 "Off" 1 "Unfolding" 2 "RESERVED" 3 "Error Indicator" ;
VAL_ 733 CMS_LHVerPosVal 0 "0x0x00~0xFA:Real values" 250 "0x0x00~0xFA:Real values" 251 "RESERVED" 252 "RESERVED" 253 "RESERVED" 254 "RESERVED" 255 "Error Indicator" ;
VAL_ 733 CMS_LHHorPosVal 0 "0x0x00~0xFA:Real values" 250 "0x0x00~0xFA:Real values" 251 "RESERVED" 252 "RESERVED" 253 "RESERVED" 254 "RESERVED" 255 "Error Indicator" ;
VAL_ 733 Monitor_ViewPanningCmd 0 "No Movement" 1 "Move Up" 2 "Move Down" 3 "Move Left" 4 "Move Right" 5 "RESERVED" 6 "RESERVED" 7 "RESERVED" ;
VAL_ 721 HU_DR_Position_Status 1 "Valid" ;
VAL_ 721 HU_DR_Altitude_Status 1 "valid" ;
VAL_ 721 HU_DR_Heading_Status 1 "Valid" ;
VAL_ 721 HU_DR_Speed_Status 1 "Valid" ;
VAL_ 721 HU_DR_DirectionSwitch_Sta 1 "Valid" ;
VAL_ 721 HU_DR_Direction 1 "Backward" ;
VAL_ 721 HU_DR_GyroCalib_Sta 1 "Calibrated" ;
VAL_ 721 HU_DR_TachoCalib_Sta 1 "Calibrated" ;
VAL_ 721 HU_DR_Solution_Sta 0 "invalid" 1 "DR valid" ;
VAL_ 721 HU_DR_GNSS_Fix_Age 1 "0x0x1~0xFE:time since last GNSS fix" 254 "0x0x1~0xFE:time since last GNSS fix" 255 "No GNSS fix yet" ;
VAL_ 2307024132 HEV_OilLifeRatio 1 "Engine oil life ratio with % unit" 2 "Engine oil life ratio with % unit" 3 "Engine oil life ratio with % unit" 4 "Engine oil life ratio with % unit" 5 "Engine oil life ratio with % unit" 6 "Engine oil life ratio with % unit" 7 "Engine oil life ratio with % unit" 8 "Engine oil life ratio with % unit" 9 "Engine oil life ratio with % unit" 10 "Engine oil life ratio with % unit" 11 "Engine oil life ratio with % unit" 12 "Engine oil life ratio with % unit" 13 "Engine oil life ratio with % unit" 14 "Engine oil life ratio with % unit" 15 "Engine oil life ratio with % unit" 16 "Engine oil life ratio with % unit" 17 "Engine oil life ratio with % unit" 18 "Engine oil life ratio with % unit" 19 "Engine oil life ratio with % unit" 20 "Engine oil life ratio with % unit" 21 "Engine oil life ratio with % unit" 22 "Engine oil life ratio with % unit" 23 "Engine oil life ratio with % unit" 24 "Engine oil life ratio with % unit" 25 "Engine oil life ratio with % unit" 26 "Engine oil life ratio with % unit" 27 "Engine oil life ratio with % unit" 28 "Engine oil life ratio with % unit" 29 "Engine oil life ratio with % unit" 30 "Engine oil life ratio with % unit" 31 "Engine oil life ratio with % unit" 32 "Engine oil life ratio with % unit" 33 "Engine oil life ratio with % unit" 34 "Engine oil life ratio with % unit" 35 "Engine oil life ratio with % unit" 36 "Engine oil life ratio with % unit" 37 "Engine oil life ratio with % unit" 38 "Engine oil life ratio with % unit" 39 "Engine oil life ratio with % unit" 40 "Engine oil life ratio with % unit" 41 "Engine oil life ratio with % unit" 42 "Engine oil life ratio with % unit" 43 "Engine oil life ratio with % unit" 44 "Engine oil life ratio with % unit" 45 "Engine oil life ratio with % unit" 46 "Engine oil life ratio with % unit" 47 "Engine oil life ratio with % unit" 48 "Engine oil life ratio with % unit" 49 "Engine oil life ratio with % unit" 50 "Engine oil life ratio with % unit" 51 "Engine oil life ratio with % unit" 52 "Engine oil life ratio with % unit" 53 "Engine oil life ratio with % unit" 54 "Engine oil life ratio with % unit" 55 "Engine oil life ratio with % unit" 56 "Engine oil life ratio with % unit" 57 "Engine oil life ratio with % unit" 58 "Engine oil life ratio with % unit" 59 "Engine oil life ratio with % unit" 60 "Engine oil life ratio with % unit" 61 "Engine oil life ratio with % unit" 62 "Engine oil life ratio with % unit" 63 "Engine oil life ratio with % unit" 64 "Engine oil life ratio with % unit" 65 "Engine oil life ratio with % unit" 66 "Engine oil life ratio with % unit" 67 "Engine oil life ratio with % unit" 68 "Engine oil life ratio with % unit" 69 "Engine oil life ratio with % unit" 70 "Engine oil life ratio with % unit" 71 "Engine oil life ratio with % unit" 72 "Engine oil life ratio with % unit" 73 "Engine oil life ratio with % unit" 74 "Engine oil life ratio with % unit" 75 "Engine oil life ratio with % unit" 76 "Engine oil life ratio with % unit" 77 "Engine oil life ratio with % unit" 78 "Engine oil life ratio with % unit" 79 "Engine oil life ratio with % unit" 80 "Engine oil life ratio with % unit" 81 "Engine oil life ratio with % unit" 82 "Engine oil life ratio with % unit" 83 "Engine oil life ratio with % unit" 84 "Engine oil life ratio with % unit" 85 "Engine oil life ratio with % unit" 86 "Engine oil life ratio with % unit" 87 "Engine oil life ratio with % unit" 88 "Engine oil life ratio with % unit" 89 "Engine oil life ratio with % unit" 90 "Engine oil life ratio with % unit" 91 "Engine oil life ratio with % unit" 92 "Engine oil life ratio with % unit" 93 "Engine oil life ratio with % unit" 94 "Engine oil life ratio with % unit" 95 "Engine oil life ratio with % unit" 96 "Engine oil life ratio with % unit" 97 "Engine oil life ratio with % unit" 98 "Engine oil life ratio with % unit" 99 "Engine oil life ratio with % unit" 100 "Engine oil life ratio with % unit" 101 "Not used" 102 "Not used" 103 "Not used" 104 "Not used" 105 "Not used" 106 "Not used" 107 "Not used" 108 "Not used" 109 "Not used" 110 "Not used" 111 "Not used" 112 "Not used" 113 "Not used" 114 "Not used" 115 "Not used" 116 "Not used" 117 "Not used" 118 "Not used" 119 "Not used" 120 "Not used" 121 "Not used" 122 "Not used" 123 "Not used" 124 "Not used" 125 "Not used" 126 "Not used" 127 "Error" ;
VAL_ 2307024132 HEV_OilLifeEna 0 "Oil life monitoring Not applied" 1 "Oil life monitoring Applied" 2 "Reserved" 3 "Error" ;
VAL_ 2307024132 HEV_OilLifeWarn 0 "No display" 1 "'Change engine oil' warning, 1st step (Low urgency)" 2 "'Change engine oil' warning, 2nd step (High urgency)" 3 "Oil change question based on oil temperature" 4 "Oil change confirm based on oil temperature" 5 "Reserved" 6 "Reserved" 7 "Error" ;
VAL_ 2307024132 HEV_RECTrigSta 0 "No detected" 1 "REC detected" ;
VAL_ 2307024132 HEV_PendingTrigSta 0 "No detected" 1 "Pending detected" ;
VAL_ 830 USM_CmdWPC2Sta 0 "Default" 1 "Off(Disable)" 2 "On(Enable)" 3 "Invalid" ;
VAL_ 830 WPC2_OptSta 0 "Default" 1 "Apply" 2 "RESERVED" 3 "Invalid" ;
VAL_ 830 WPC2_SWVerMajor1 0 "0x0x0~0x7F:ASCII Code Value (HEX)" 127 "0x0x0~0x7F:ASCII Code Value (HEX)" ;
VAL_ 830 WPC2_PhnLftWrngSta 0 "Off" 1 "Cellphone on the pad" 2 "Charging" 3 "Charging complete" 4 "Cellphone reminder" 5 "Error" 6 "NFC Card detected" 7 "Invalid" ;
VAL_ 830 WPC2_SWVerMinor1 0 "0x0x0~0x7F:ASCII Code Value (HEX)" 127 "0x0x0~0x7F:ASCII Code Value (HEX)" ;
VAL_ 830 WPC2_SWVerMinor2 0 "0x0x0~0x7F:ASCII Code Value (HEX)" 127 "0x0x0~0x7F:ASCII Code Value (HEX)" ;
VAL_ 830 WPC2_IndSyncVal 0 "default" 1 "off" 2 "1st sync" 3 "2nd sync" 4 "3rd sync" 5 "error off" 6 "error on" 7 "reserved" ;
VAL_ 830 WPC2_ResetOpSta 0 "Normal" 1 "Reset Complete" 2 "Reset Fail" 3 "RESERVED" ;
VAL_ 2307024130 HEV_SoakTimeErrSta 0 "No failure detected" 1 "Failure detected" 2 "Not used" 3 "Error indicator" ;
VAL_ 2307024130 HEV_SoakTimeOvrSta 0 "Engine soaking time < 360 min" 1 "Engine soaking time ¡Ã 360 min" 2 "Not used" 3 "Error indicator" ;
VAL_ 2307024130 HEV_FuelRunOutSta 0 "None" 1 "Fuel RunOut" 2 "Not used" 3 "Error indicator" ;
VAL_ 2307024130 HEV_FuelRunOutDetSta 0 "Inactive" 1 "Active" 2 "Not used" 3 "Error indicator" ;
